[part 2 of 3: package /STELLANTIS/EPT/ASWCs]
AUTOSAR XML (schema 4-2-2)
package /STELLANTIS/EPT/ASWCs  (continued)
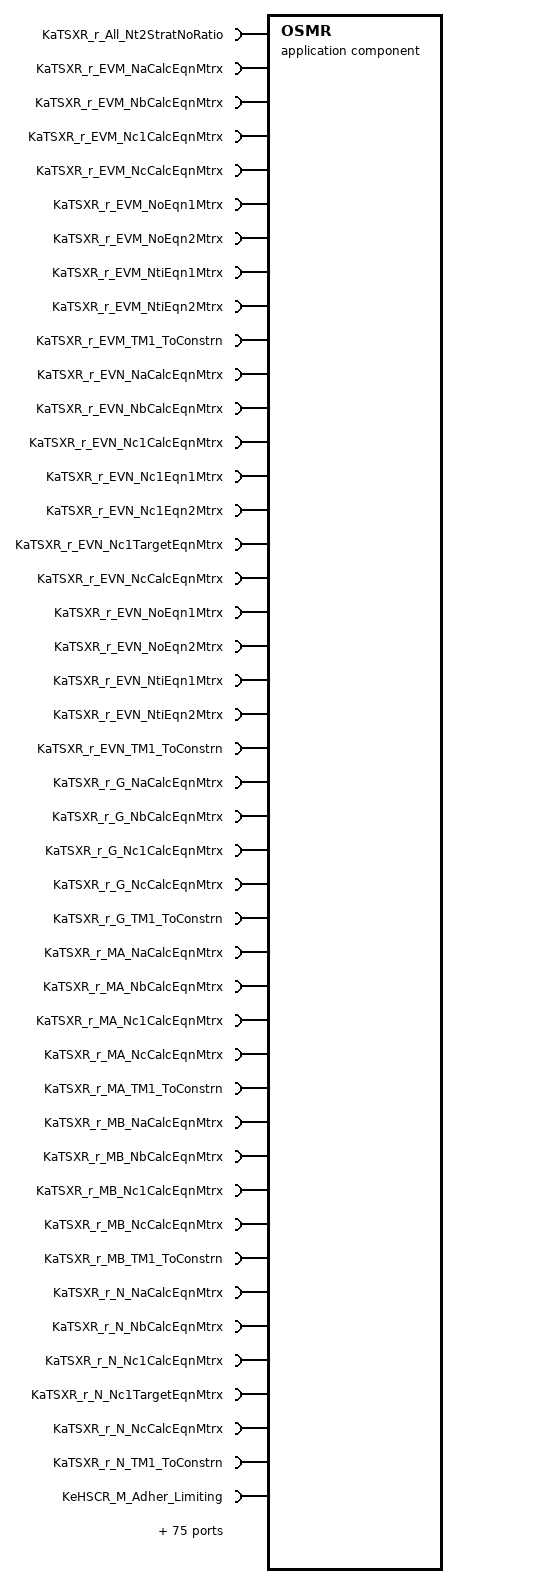
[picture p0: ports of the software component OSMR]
  application sw component type OSMR  (continued)
    119 x require port:
      KaTSXR_r_All_Nt2StratNoRatio: parameter-require-com-spec{init-value=KaTSXR_r_All_Nt2StratNoRatio_KaTSXR_r_All_Nt2StratNoRatio:[KaTSXR_r_All_Nt2StratNoRatio_KaTSXR_r_All_Nt2StratNoRatio_rt_Array_Float_9_1:1, KaTSXR_r_All_Nt2StratNoRatio_KaTSXR_r_All_Nt2StratNoRatio_rt_Array_Float_9_2:1, KaTSXR_r_All_Nt2StratNoRatio_KaTSXR_r_All_Nt2StratNoRatio_rt_Array_Float_9_3:1, KaTSXR_r_All_Nt2StratNoRatio_KaTSXR_r_All_Nt2StratNoRatio_rt_Array_Float_9_4:1, KaTSXR_r_All_Nt2StratNoRatio_KaTSXR_r_All_Nt2StratNoRatio_rt_Array_Float_9_5:1, KaTSXR_r_All_Nt2StratNoRatio_KaTSXR_r_All_Nt2StratNoRatio_rt_Array_Float_9_6:1, KaTSXR_r_All_Nt2StratNoRatio_KaTSXR_r_All_Nt2StratNoRatio_rt_Array_Float_9_7:1, KaTSXR_r_All_Nt2StratNoRatio_KaTSXR_r_All_Nt2StratNoRatio_rt_Array_Float_9_8:1, KaTSXR_r_All_Nt2StratNoRatio_KaTSXR_r_All_Nt2StratNoRatio_rt_Array_Float_9_9:1], parameter=KaTSXR_r_All_Nt2StratNoRatio}, required-interface=KaTSXR_r_All_Nt2StratNoRatio
      KaTSXR_r_EVM_NaCalcEqnMtrx: parameter-require-com-spec{init-value=KaTSXR_r_EVM_NaCalcEqnMtrx_KaTSXR_r_EVM_NaCalcEqnMtrx:[KaTSXR_r_EVM_NaCalcEqnMtrx_KaTSXR_r_EVM_NaCalcEqnMtrx_rt_Array_Float_27_1:0, KaTSXR_r_EVM_NaCalcEqnMtrx_KaTSXR_r_EVM_NaCalcEqnMtrx_rt_Array_Float_27_2:0, KaTSXR_r_EVM_NaCalcEqnMtrx_KaTSXR_r_EVM_NaCalcEqnMtrx_rt_Array_Float_27_3:0, KaTSXR_r_EVM_NaCalcEqnMtrx_KaTSXR_r_EVM_NaCalcEqnMtrx_rt_Array_Float_27_4:0, KaTSXR_r_EVM_NaCalcEqnMtrx_KaTSXR_r_EVM_NaCalcEqnMtrx_rt_Array_Float_27_5:0, KaTSXR_r_EVM_NaCalcEqnMtrx_KaTSXR_r_EVM_NaCalcEqnMtrx_rt_Array_Float_27_6:0, KaTSXR_r_EVM_NaCalcEqnMtrx_KaTSXR_r_EVM_NaCalcEqnMtrx_rt_Array_Float_27_7:0, KaTSXR_r_EVM_NaCalcEqnMtrx_KaTSXR_r_EVM_NaCalcEqnMtrx_rt_Array_Float_27_8:0, KaTSXR_r_EVM_NaCalcEqnMtrx_KaTSXR_r_EVM_NaCalcEqnMtrx_rt_Array_Float_27_9:0, KaTSXR_r_EVM_NaCalcEqnMtrx_KaTSXR_r_EVM_NaCalcEqnMtrx_rt_Array_Float_27_10:0, KaTSXR_r_EVM_NaCalcEqnMtrx_KaTSXR_r_EVM_NaCalcEqnMtrx_rt_Array_Float_27_11:0, KaTSXR_r_EVM_NaCalcEqnMtrx_KaTSXR_r_EVM_NaCalcEqnMtrx_rt_Array_Float_27_12:0, KaTSXR_r_EVM_NaCalcEqnMtrx_KaTSXR_r_EVM_NaCalcEqnMtrx_rt_Array_Float_27_13:0, KaTSXR_r_EVM_NaCalcEqnMtrx_KaTSXR_r_EVM_NaCalcEqnMtrx_rt_Array_Float_27_14:0, KaTSXR_r_EVM_NaCalcEqnMtrx_KaTSXR_r_EVM_NaCalcEqnMtrx_rt_Array_Float_27_15:0, KaTSXR_r_EVM_NaCalcEqnMtrx_KaTSXR_r_EVM_NaCalcEqnMtrx_rt_Array_Float_27_16:0, KaTSXR_r_EVM_NaCalcEqnMtrx_KaTSXR_r_EVM_NaCalcEqnMtrx_rt_Array_Float_27_17:0, KaTSXR_r_EVM_NaCalcEqnMtrx_KaTSXR_r_EVM_NaCalcEqnMtrx_rt_Array_Float_27_18:0, KaTSXR_r_EVM_NaCalcEqnMtrx_KaTSXR_r_EVM_NaCalcEqnMtrx_rt_Array_Float_27_19:0, KaTSXR_r_EVM_NaCalcEqnMtrx_KaTSXR_r_EVM_NaCalcEqnMtrx_rt_Array_Float_27_20:0, KaTSXR_r_EVM_NaCalcEqnMtrx_KaTSXR_r_EVM_NaCalcEqnMtrx_rt_Array_Float_27_21:0, KaTSXR_r_EVM_NaCalcEqnMtrx_KaTSXR_r_EVM_NaCalcEqnMtrx_rt_Array_Float_27_22:0, KaTSXR_r_EVM_NaCalcEqnMtrx_KaTSXR_r_EVM_NaCalcEqnMtrx_rt_Array_Float_27_23:0, KaTSXR_r_EVM_NaCalcEqnMtrx_KaTSXR_r_EVM_NaCalcEqnMtrx_rt_Array_Float_27_24:0, KaTSXR_r_EVM_NaCalcEqnMtrx_KaTSXR_r_EVM_NaCalcEqnMtrx_rt_Array_Float_27_25:0, KaTSXR_r_EVM_NaCalcEqnMtrx_KaTSXR_r_EVM_NaCalcEqnMtrx_rt_Array_Float_27_26:0, KaTSXR_r_EVM_NaCalcEqnMtrx_KaTSXR_r_EVM_NaCalcEqnMtrx_rt_Array_Float_27_27:0], parameter=KaTSXR_r_EVM_NaCalcEqnMtrx}, required-interface=KaTSXR_r_EVM_NaCalcEqnMtrx
      KaTSXR_r_EVM_NbCalcEqnMtrx: parameter-require-com-spec{init-value=KaTSXR_r_EVM_NbCalcEqnMtrx_KaTSXR_r_EVM_NbCalcEqnMtrx:[KaTSXR_r_EVM_NbCalcEqnMtrx_KaTSXR_r_EVM_NbCalcEqnMtrx_rt_Array_Float_27_1:0, KaTSXR_r_EVM_NbCalcEqnMtrx_KaTSXR_r_EVM_NbCalcEqnMtrx_rt_Array_Float_27_2:0, KaTSXR_r_EVM_NbCalcEqnMtrx_KaTSXR_r_EVM_NbCalcEqnMtrx_rt_Array_Float_27_3:0, KaTSXR_r_EVM_NbCalcEqnMtrx_KaTSXR_r_EVM_NbCalcEqnMtrx_rt_Array_Float_27_4:0, KaTSXR_r_EVM_NbCalcEqnMtrx_KaTSXR_r_EVM_NbCalcEqnMtrx_rt_Array_Float_27_5:0, KaTSXR_r_EVM_NbCalcEqnMtrx_KaTSXR_r_EVM_NbCalcEqnMtrx_rt_Array_Float_27_6:0, KaTSXR_r_EVM_NbCalcEqnMtrx_KaTSXR_r_EVM_NbCalcEqnMtrx_rt_Array_Float_27_7:0, KaTSXR_r_EVM_NbCalcEqnMtrx_KaTSXR_r_EVM_NbCalcEqnMtrx_rt_Array_Float_27_8:0, KaTSXR_r_EVM_NbCalcEqnMtrx_KaTSXR_r_EVM_NbCalcEqnMtrx_rt_Array_Float_27_9:0, KaTSXR_r_EVM_NbCalcEqnMtrx_KaTSXR_r_EVM_NbCalcEqnMtrx_rt_Array_Float_27_10:0, KaTSXR_r_EVM_NbCalcEqnMtrx_KaTSXR_r_EVM_NbCalcEqnMtrx_rt_Array_Float_27_11:0, KaTSXR_r_EVM_NbCalcEqnMtrx_KaTSXR_r_EVM_NbCalcEqnMtrx_rt_Array_Float_27_12:0, KaTSXR_r_EVM_NbCalcEqnMtrx_KaTSXR_r_EVM_NbCalcEqnMtrx_rt_Array_Float_27_13:0, KaTSXR_r_EVM_NbCalcEqnMtrx_KaTSXR_r_EVM_NbCalcEqnMtrx_rt_Array_Float_27_14:0, KaTSXR_r_EVM_NbCalcEqnMtrx_KaTSXR_r_EVM_NbCalcEqnMtrx_rt_Array_Float_27_15:0, KaTSXR_r_EVM_NbCalcEqnMtrx_KaTSXR_r_EVM_NbCalcEqnMtrx_rt_Array_Float_27_16:0, KaTSXR_r_EVM_NbCalcEqnMtrx_KaTSXR_r_EVM_NbCalcEqnMtrx_rt_Array_Float_27_17:0, KaTSXR_r_EVM_NbCalcEqnMtrx_KaTSXR_r_EVM_NbCalcEqnMtrx_rt_Array_Float_27_18:0, KaTSXR_r_EVM_NbCalcEqnMtrx_KaTSXR_r_EVM_NbCalcEqnMtrx_rt_Array_Float_27_19:0, KaTSXR_r_EVM_NbCalcEqnMtrx_KaTSXR_r_EVM_NbCalcEqnMtrx_rt_Array_Float_27_20:0, KaTSXR_r_EVM_NbCalcEqnMtrx_KaTSXR_r_EVM_NbCalcEqnMtrx_rt_Array_Float_27_21:0, KaTSXR_r_EVM_NbCalcEqnMtrx_KaTSXR_r_EVM_NbCalcEqnMtrx_rt_Array_Float_27_22:0, KaTSXR_r_EVM_NbCalcEqnMtrx_KaTSXR_r_EVM_NbCalcEqnMtrx_rt_Array_Float_27_23:0, KaTSXR_r_EVM_NbCalcEqnMtrx_KaTSXR_r_EVM_NbCalcEqnMtrx_rt_Array_Float_27_24:0, KaTSXR_r_EVM_NbCalcEqnMtrx_KaTSXR_r_EVM_NbCalcEqnMtrx_rt_Array_Float_27_25:0, KaTSXR_r_EVM_NbCalcEqnMtrx_KaTSXR_r_EVM_NbCalcEqnMtrx_rt_Array_Float_27_26:0, KaTSXR_r_EVM_NbCalcEqnMtrx_KaTSXR_r_EVM_NbCalcEqnMtrx_rt_Array_Float_27_27:0], parameter=KaTSXR_r_EVM_NbCalcEqnMtrx}, required-interface=KaTSXR_r_EVM_NbCalcEqnMtrx
      KaTSXR_r_EVM_Nc1CalcEqnMtrx: parameter-require-com-spec{init-value=KaTSXR_r_EVM_Nc1CalcEqnMtrx_KaTSXR_r_EVM_Nc1CalcEqnMtrx:[KaTSXR_r_EVM_Nc1CalcEqnMtrx_KaTSXR_r_EVM_Nc1CalcEqnMtrx_rt_Array_Float_27_1:0, KaTSXR_r_EVM_Nc1CalcEqnMtrx_KaTSXR_r_EVM_Nc1CalcEqnMtrx_rt_Array_Float_27_2:0, KaTSXR_r_EVM_Nc1CalcEqnMtrx_KaTSXR_r_EVM_Nc1CalcEqnMtrx_rt_Array_Float_27_3:0, KaTSXR_r_EVM_Nc1CalcEqnMtrx_KaTSXR_r_EVM_Nc1CalcEqnMtrx_rt_Array_Float_27_4:0, KaTSXR_r_EVM_Nc1CalcEqnMtrx_KaTSXR_r_EVM_Nc1CalcEqnMtrx_rt_Array_Float_27_5:0, KaTSXR_r_EVM_Nc1CalcEqnMtrx_KaTSXR_r_EVM_Nc1CalcEqnMtrx_rt_Array_Float_27_6:0, KaTSXR_r_EVM_Nc1CalcEqnMtrx_KaTSXR_r_EVM_Nc1CalcEqnMtrx_rt_Array_Float_27_7:0, KaTSXR_r_EVM_Nc1CalcEqnMtrx_KaTSXR_r_EVM_Nc1CalcEqnMtrx_rt_Array_Float_27_8:0, KaTSXR_r_EVM_Nc1CalcEqnMtrx_KaTSXR_r_EVM_Nc1CalcEqnMtrx_rt_Array_Float_27_9:0, KaTSXR_r_EVM_Nc1CalcEqnMtrx_KaTSXR_r_EVM_Nc1CalcEqnMtrx_rt_Array_Float_27_10:0, KaTSXR_r_EVM_Nc1CalcEqnMtrx_KaTSXR_r_EVM_Nc1CalcEqnMtrx_rt_Array_Float_27_11:0, KaTSXR_r_EVM_Nc1CalcEqnMtrx_KaTSXR_r_EVM_Nc1CalcEqnMtrx_rt_Array_Float_27_12:0, KaTSXR_r_EVM_Nc1CalcEqnMtrx_KaTSXR_r_EVM_Nc1CalcEqnMtrx_rt_Array_Float_27_13:0, KaTSXR_r_EVM_Nc1CalcEqnMtrx_KaTSXR_r_EVM_Nc1CalcEqnMtrx_rt_Array_Float_27_14:0, KaTSXR_r_EVM_Nc1CalcEqnMtrx_KaTSXR_r_EVM_Nc1CalcEqnMtrx_rt_Array_Float_27_15:0, KaTSXR_r_EVM_Nc1CalcEqnMtrx_KaTSXR_r_EVM_Nc1CalcEqnMtrx_rt_Array_Float_27_16:0, KaTSXR_r_EVM_Nc1CalcEqnMtrx_KaTSXR_r_EVM_Nc1CalcEqnMtrx_rt_Array_Float_27_17:0, KaTSXR_r_EVM_Nc1CalcEqnMtrx_KaTSXR_r_EVM_Nc1CalcEqnMtrx_rt_Array_Float_27_18:0, KaTSXR_r_EVM_Nc1CalcEqnMtrx_KaTSXR_r_EVM_Nc1CalcEqnMtrx_rt_Array_Float_27_19:0, KaTSXR_r_EVM_Nc1CalcEqnMtrx_KaTSXR_r_EVM_Nc1CalcEqnMtrx_rt_Array_Float_27_20:0, KaTSXR_r_EVM_Nc1CalcEqnMtrx_KaTSXR_r_EVM_Nc1CalcEqnMtrx_rt_Array_Float_27_21:0, KaTSXR_r_EVM_Nc1CalcEqnMtrx_KaTSXR_r_EVM_Nc1CalcEqnMtrx_rt_Array_Float_27_22:0, KaTSXR_r_EVM_Nc1CalcEqnMtrx_KaTSXR_r_EVM_Nc1CalcEqnMtrx_rt_Array_Float_27_23:0, KaTSXR_r_EVM_Nc1CalcEqnMtrx_KaTSXR_r_EVM_Nc1CalcEqnMtrx_rt_Array_Float_27_24:0, KaTSXR_r_EVM_Nc1CalcEqnMtrx_KaTSXR_r_EVM_Nc1CalcEqnMtrx_rt_Array_Float_27_25:0, KaTSXR_r_EVM_Nc1CalcEqnMtrx_KaTSXR_r_EVM_Nc1CalcEqnMtrx_rt_Array_Float_27_26:0, KaTSXR_r_EVM_Nc1CalcEqnMtrx_KaTSXR_r_EVM_Nc1CalcEqnMtrx_rt_Array_Float_27_27:0], parameter=KaTSXR_r_EVM_Nc1CalcEqnMtrx}, required-interface=KaTSXR_r_EVM_Nc1CalcEqnMtrx
      KaTSXR_r_EVM_NcCalcEqnMtrx: parameter-require-com-spec{init-value=KaTSXR_r_EVM_NcCalcEqnMtrx_KaTSXR_r_EVM_NcCalcEqnMtrx:[KaTSXR_r_EVM_NcCalcEqnMtrx_KaTSXR_r_EVM_NcCalcEqnMtrx_rt_Array_Float_27_1:0, KaTSXR_r_EVM_NcCalcEqnMtrx_KaTSXR_r_EVM_NcCalcEqnMtrx_rt_Array_Float_27_2:0, KaTSXR_r_EVM_NcCalcEqnMtrx_KaTSXR_r_EVM_NcCalcEqnMtrx_rt_Array_Float_27_3:0, KaTSXR_r_EVM_NcCalcEqnMtrx_KaTSXR_r_EVM_NcCalcEqnMtrx_rt_Array_Float_27_4:0, KaTSXR_r_EVM_NcCalcEqnMtrx_KaTSXR_r_EVM_NcCalcEqnMtrx_rt_Array_Float_27_5:0, KaTSXR_r_EVM_NcCalcEqnMtrx_KaTSXR_r_EVM_NcCalcEqnMtrx_rt_Array_Float_27_6:0, KaTSXR_r_EVM_NcCalcEqnMtrx_KaTSXR_r_EVM_NcCalcEqnMtrx_rt_Array_Float_27_7:0, KaTSXR_r_EVM_NcCalcEqnMtrx_KaTSXR_r_EVM_NcCalcEqnMtrx_rt_Array_Float_27_8:0, KaTSXR_r_EVM_NcCalcEqnMtrx_KaTSXR_r_EVM_NcCalcEqnMtrx_rt_Array_Float_27_9:0, KaTSXR_r_EVM_NcCalcEqnMtrx_KaTSXR_r_EVM_NcCalcEqnMtrx_rt_Array_Float_27_10:0, KaTSXR_r_EVM_NcCalcEqnMtrx_KaTSXR_r_EVM_NcCalcEqnMtrx_rt_Array_Float_27_11:0, KaTSXR_r_EVM_NcCalcEqnMtrx_KaTSXR_r_EVM_NcCalcEqnMtrx_rt_Array_Float_27_12:0, KaTSXR_r_EVM_NcCalcEqnMtrx_KaTSXR_r_EVM_NcCalcEqnMtrx_rt_Array_Float_27_13:0, KaTSXR_r_EVM_NcCalcEqnMtrx_KaTSXR_r_EVM_NcCalcEqnMtrx_rt_Array_Float_27_14:0, KaTSXR_r_EVM_NcCalcEqnMtrx_KaTSXR_r_EVM_NcCalcEqnMtrx_rt_Array_Float_27_15:0, KaTSXR_r_EVM_NcCalcEqnMtrx_KaTSXR_r_EVM_NcCalcEqnMtrx_rt_Array_Float_27_16:0, KaTSXR_r_EVM_NcCalcEqnMtrx_KaTSXR_r_EVM_NcCalcEqnMtrx_rt_Array_Float_27_17:0, KaTSXR_r_EVM_NcCalcEqnMtrx_KaTSXR_r_EVM_NcCalcEqnMtrx_rt_Array_Float_27_18:0, KaTSXR_r_EVM_NcCalcEqnMtrx_KaTSXR_r_EVM_NcCalcEqnMtrx_rt_Array_Float_27_19:0, KaTSXR_r_EVM_NcCalcEqnMtrx_KaTSXR_r_EVM_NcCalcEqnMtrx_rt_Array_Float_27_20:0, KaTSXR_r_EVM_NcCalcEqnMtrx_KaTSXR_r_EVM_NcCalcEqnMtrx_rt_Array_Float_27_21:0, KaTSXR_r_EVM_NcCalcEqnMtrx_KaTSXR_r_EVM_NcCalcEqnMtrx_rt_Array_Float_27_22:0, KaTSXR_r_EVM_NcCalcEqnMtrx_KaTSXR_r_EVM_NcCalcEqnMtrx_rt_Array_Float_27_23:0, KaTSXR_r_EVM_NcCalcEqnMtrx_KaTSXR_r_EVM_NcCalcEqnMtrx_rt_Array_Float_27_24:0, KaTSXR_r_EVM_NcCalcEqnMtrx_KaTSXR_r_EVM_NcCalcEqnMtrx_rt_Array_Float_27_25:0, KaTSXR_r_EVM_NcCalcEqnMtrx_KaTSXR_r_EVM_NcCalcEqnMtrx_rt_Array_Float_27_26:0, KaTSXR_r_EVM_NcCalcEqnMtrx_KaTSXR_r_EVM_NcCalcEqnMtrx_rt_Array_Float_27_27:0], parameter=KaTSXR_r_EVM_NcCalcEqnMtrx}, required-interface=KaTSXR_r_EVM_NcCalcEqnMtrx
      KaTSXR_r_EVM_NoEqn1Mtrx: parameter-require-com-spec{init-value=KaTSXR_r_EVM_NoEqn1Mtrx_KaTSXR_r_EVM_NoEqn1Mtrx:[KaTSXR_r_EVM_NoEqn1Mtrx_KaTSXR_r_EVM_NoEqn1Mtrx_rt_Array_Float_54_1:0, KaTSXR_r_EVM_NoEqn1Mtrx_KaTSXR_r_EVM_NoEqn1Mtrx_rt_Array_Float_54_2:0, KaTSXR_r_EVM_NoEqn1Mtrx_KaTSXR_r_EVM_NoEqn1Mtrx_rt_Array_Float_54_3:0, KaTSXR_r_EVM_NoEqn1Mtrx_KaTSXR_r_EVM_NoEqn1Mtrx_rt_Array_Float_54_4:0, KaTSXR_r_EVM_NoEqn1Mtrx_KaTSXR_r_EVM_NoEqn1Mtrx_rt_Array_Float_54_5:0, KaTSXR_r_EVM_NoEqn1Mtrx_KaTSXR_r_EVM_NoEqn1Mtrx_rt_Array_Float_54_6:0, KaTSXR_r_EVM_NoEqn1Mtrx_KaTSXR_r_EVM_NoEqn1Mtrx_rt_Array_Float_54_7:0, KaTSXR_r_EVM_NoEqn1Mtrx_KaTSXR_r_EVM_NoEqn1Mtrx_rt_Array_Float_54_8:0, KaTSXR_r_EVM_NoEqn1Mtrx_KaTSXR_r_EVM_NoEqn1Mtrx_rt_Array_Float_54_9:0, KaTSXR_r_EVM_NoEqn1Mtrx_KaTSXR_r_EVM_NoEqn1Mtrx_rt_Array_Float_54_10:0, KaTSXR_r_EVM_NoEqn1Mtrx_KaTSXR_r_EVM_NoEqn1Mtrx_rt_Array_Float_54_11:0, KaTSXR_r_EVM_NoEqn1Mtrx_KaTSXR_r_EVM_NoEqn1Mtrx_rt_Array_Float_54_12:0, KaTSXR_r_EVM_NoEqn1Mtrx_KaTSXR_r_EVM_NoEqn1Mtrx_rt_Array_Float_54_13:0, KaTSXR_r_EVM_NoEqn1Mtrx_KaTSXR_r_EVM_NoEqn1Mtrx_rt_Array_Float_54_14:0, KaTSXR_r_EVM_NoEqn1Mtrx_KaTSXR_r_EVM_NoEqn1Mtrx_rt_Array_Float_54_15:0, KaTSXR_r_EVM_NoEqn1Mtrx_KaTSXR_r_EVM_NoEqn1Mtrx_rt_Array_Float_54_16:0, KaTSXR_r_EVM_NoEqn1Mtrx_KaTSXR_r_EVM_NoEqn1Mtrx_rt_Array_Float_54_17:0, KaTSXR_r_EVM_NoEqn1Mtrx_KaTSXR_r_EVM_NoEqn1Mtrx_rt_Array_Float_54_18:0, KaTSXR_r_EVM_NoEqn1Mtrx_KaTSXR_r_EVM_NoEqn1Mtrx_rt_Array_Float_54_19:0, KaTSXR_r_EVM_NoEqn1Mtrx_KaTSXR_r_EVM_NoEqn1Mtrx_rt_Array_Float_54_20:0, KaTSXR_r_EVM_NoEqn1Mtrx_KaTSXR_r_EVM_NoEqn1Mtrx_rt_Array_Float_54_21:0, KaTSXR_r_EVM_NoEqn1Mtrx_KaTSXR_r_EVM_NoEqn1Mtrx_rt_Array_Float_54_22:0, KaTSXR_r_EVM_NoEqn1Mtrx_KaTSXR_r_EVM_NoEqn1Mtrx_rt_Array_Float_54_23:0, KaTSXR_r_EVM_NoEqn1Mtrx_KaTSXR_r_EVM_NoEqn1Mtrx_rt_Array_Float_54_24:0, KaTSXR_r_EVM_NoEqn1Mtrx_KaTSXR_r_EVM_NoEqn1Mtrx_rt_Array_Float_54_25:0, KaTSXR_r_EVM_NoEqn1Mtrx_KaTSXR_r_EVM_NoEqn1Mtrx_rt_Array_Float_54_26:0, KaTSXR_r_EVM_NoEqn1Mtrx_KaTSXR_r_EVM_NoEqn1Mtrx_rt_Array_Float_54_27:0, KaTSXR_r_EVM_NoEqn1Mtrx_KaTSXR_r_EVM_NoEqn1Mtrx_rt_Array_Float_54_28:0, KaTSXR_r_EVM_NoEqn1Mtrx_KaTSXR_r_EVM_NoEqn1Mtrx_rt_Array_Float_54_29:0, KaTSXR_r_EVM_NoEqn1Mtrx_KaTSXR_r_EVM_NoEqn1Mtrx_rt_Array_Float_54_30:0, KaTSXR_r_EVM_NoEqn1Mtrx_KaTSXR_r_EVM_NoEqn1Mtrx_rt_Array_Float_54_31:0, KaTSXR_r_EVM_NoEqn1Mtrx_KaTSXR_r_EVM_NoEqn1Mtrx_rt_Array_Float_54_32:0, KaTSXR_r_EVM_NoEqn1Mtrx_KaTSXR_r_EVM_NoEqn1Mtrx_rt_Array_Float_54_33:0, KaTSXR_r_EVM_NoEqn1Mtrx_KaTSXR_r_EVM_NoEqn1Mtrx_rt_Array_Float_54_34:0, KaTSXR_r_EVM_NoEqn1Mtrx_KaTSXR_r_EVM_NoEqn1Mtrx_rt_Array_Float_54_35:0, KaTSXR_r_EVM_NoEqn1Mtrx_KaTSXR_r_EVM_NoEqn1Mtrx_rt_Array_Float_54_36:0, KaTSXR_r_EVM_NoEqn1Mtrx_KaTSXR_r_EVM_NoEqn1Mtrx_rt_Array_Float_54_37:0, KaTSXR_r_EVM_NoEqn1Mtrx_KaTSXR_r_EVM_NoEqn1Mtrx_rt_Array_Float_54_38:0, KaTSXR_r_EVM_NoEqn1Mtrx_KaTSXR_r_EVM_NoEqn1Mtrx_rt_Array_Float_54_39:0, KaTSXR_r_EVM_NoEqn1Mtrx_KaTSXR_r_EVM_NoEqn1Mtrx_rt_Array_Float_54_40:0, KaTSXR_r_EVM_NoEqn1Mtrx_KaTSXR_r_EVM_NoEqn1Mtrx_rt_Array_Float_54_41:0, KaTSXR_r_EVM_NoEqn1Mtrx_KaTSXR_r_EVM_NoEqn1Mtrx_rt_Array_Float_54_42:0, KaTSXR_r_EVM_NoEqn1Mtrx_KaTSXR_r_EVM_NoEqn1Mtrx_rt_Array_Float_54_43:0, KaTSXR_r_EVM_NoEqn1Mtrx_KaTSXR_r_EVM_NoEqn1Mtrx_rt_Array_Float_54_44:0, KaTSXR_r_EVM_NoEqn1Mtrx_KaTSXR_r_EVM_NoEqn1Mtrx_rt_Array_Float_54_45:0, KaTSXR_r_EVM_NoEqn1Mtrx_KaTSXR_r_EVM_NoEqn1Mtrx_rt_Array_Float_54_46:0, KaTSXR_r_EVM_NoEqn1Mtrx_KaTSXR_r_EVM_NoEqn1Mtrx_rt_Array_Float_54_47:0, KaTSXR_r_EVM_NoEqn1Mtrx_KaTSXR_r_EVM_NoEqn1Mtrx_rt_Array_Float_54_48:0, KaTSXR_r_EVM_NoEqn1Mtrx_KaTSXR_r_EVM_NoEqn1Mtrx_rt_Array_Float_54_49:0, KaTSXR_r_EVM_NoEqn1Mtrx_KaTSXR_r_EVM_NoEqn1Mtrx_rt_Array_Float_54_50:0, KaTSXR_r_EVM_NoEqn1Mtrx_KaTSXR_r_EVM_NoEqn1Mtrx_rt_Array_Float_54_51:0, KaTSXR_r_EVM_NoEqn1Mtrx_KaTSXR_r_EVM_NoEqn1Mtrx_rt_Array_Float_54_52:0, KaTSXR_r_EVM_NoEqn1Mtrx_KaTSXR_r_EVM_NoEqn1Mtrx_rt_Array_Float_54_53:0, KaTSXR_r_EVM_NoEqn1Mtrx_KaTSXR_r_EVM_NoEqn1Mtrx_rt_Array_Float_54_54:0], parameter=KaTSXR_r_EVM_NoEqn1Mtrx}, required-interface=KaTSXR_r_EVM_NoEqn1Mtrx
      KaTSXR_r_EVM_NoEqn2Mtrx: parameter-require-com-spec{init-value=KaTSXR_r_EVM_NoEqn2Mtrx_KaTSXR_r_EVM_NoEqn2Mtrx:[KaTSXR_r_EVM_NoEqn2Mtrx_KaTSXR_r_EVM_NoEqn2Mtrx_rt_Array_Float_54_1:0, KaTSXR_r_EVM_NoEqn2Mtrx_KaTSXR_r_EVM_NoEqn2Mtrx_rt_Array_Float_54_2:0, KaTSXR_r_EVM_NoEqn2Mtrx_KaTSXR_r_EVM_NoEqn2Mtrx_rt_Array_Float_54_3:0, KaTSXR_r_EVM_NoEqn2Mtrx_KaTSXR_r_EVM_NoEqn2Mtrx_rt_Array_Float_54_4:0, KaTSXR_r_EVM_NoEqn2Mtrx_KaTSXR_r_EVM_NoEqn2Mtrx_rt_Array_Float_54_5:0, KaTSXR_r_EVM_NoEqn2Mtrx_KaTSXR_r_EVM_NoEqn2Mtrx_rt_Array_Float_54_6:0, KaTSXR_r_EVM_NoEqn2Mtrx_KaTSXR_r_EVM_NoEqn2Mtrx_rt_Array_Float_54_7:0, KaTSXR_r_EVM_NoEqn2Mtrx_KaTSXR_r_EVM_NoEqn2Mtrx_rt_Array_Float_54_8:0, KaTSXR_r_EVM_NoEqn2Mtrx_KaTSXR_r_EVM_NoEqn2Mtrx_rt_Array_Float_54_9:0, KaTSXR_r_EVM_NoEqn2Mtrx_KaTSXR_r_EVM_NoEqn2Mtrx_rt_Array_Float_54_10:0, KaTSXR_r_EVM_NoEqn2Mtrx_KaTSXR_r_EVM_NoEqn2Mtrx_rt_Array_Float_54_11:0, KaTSXR_r_EVM_NoEqn2Mtrx_KaTSXR_r_EVM_NoEqn2Mtrx_rt_Array_Float_54_12:0, KaTSXR_r_EVM_NoEqn2Mtrx_KaTSXR_r_EVM_NoEqn2Mtrx_rt_Array_Float_54_13:0, KaTSXR_r_EVM_NoEqn2Mtrx_KaTSXR_r_EVM_NoEqn2Mtrx_rt_Array_Float_54_14:0, KaTSXR_r_EVM_NoEqn2Mtrx_KaTSXR_r_EVM_NoEqn2Mtrx_rt_Array_Float_54_15:0, KaTSXR_r_EVM_NoEqn2Mtrx_KaTSXR_r_EVM_NoEqn2Mtrx_rt_Array_Float_54_16:0, KaTSXR_r_EVM_NoEqn2Mtrx_KaTSXR_r_EVM_NoEqn2Mtrx_rt_Array_Float_54_17:0, KaTSXR_r_EVM_NoEqn2Mtrx_KaTSXR_r_EVM_NoEqn2Mtrx_rt_Array_Float_54_18:0, KaTSXR_r_EVM_NoEqn2Mtrx_KaTSXR_r_EVM_NoEqn2Mtrx_rt_Array_Float_54_19:0, KaTSXR_r_EVM_NoEqn2Mtrx_KaTSXR_r_EVM_NoEqn2Mtrx_rt_Array_Float_54_20:0, KaTSXR_r_EVM_NoEqn2Mtrx_KaTSXR_r_EVM_NoEqn2Mtrx_rt_Array_Float_54_21:0, KaTSXR_r_EVM_NoEqn2Mtrx_KaTSXR_r_EVM_NoEqn2Mtrx_rt_Array_Float_54_22:0, KaTSXR_r_EVM_NoEqn2Mtrx_KaTSXR_r_EVM_NoEqn2Mtrx_rt_Array_Float_54_23:0, KaTSXR_r_EVM_NoEqn2Mtrx_KaTSXR_r_EVM_NoEqn2Mtrx_rt_Array_Float_54_24:0, KaTSXR_r_EVM_NoEqn2Mtrx_KaTSXR_r_EVM_NoEqn2Mtrx_rt_Array_Float_54_25:0, KaTSXR_r_EVM_NoEqn2Mtrx_KaTSXR_r_EVM_NoEqn2Mtrx_rt_Array_Float_54_26:0, KaTSXR_r_EVM_NoEqn2Mtrx_KaTSXR_r_EVM_NoEqn2Mtrx_rt_Array_Float_54_27:0, KaTSXR_r_EVM_NoEqn2Mtrx_KaTSXR_r_EVM_NoEqn2Mtrx_rt_Array_Float_54_28:0, KaTSXR_r_EVM_NoEqn2Mtrx_KaTSXR_r_EVM_NoEqn2Mtrx_rt_Array_Float_54_29:0, KaTSXR_r_EVM_NoEqn2Mtrx_KaTSXR_r_EVM_NoEqn2Mtrx_rt_Array_Float_54_30:0, KaTSXR_r_EVM_NoEqn2Mtrx_KaTSXR_r_EVM_NoEqn2Mtrx_rt_Array_Float_54_31:0, KaTSXR_r_EVM_NoEqn2Mtrx_KaTSXR_r_EVM_NoEqn2Mtrx_rt_Array_Float_54_32:0, KaTSXR_r_EVM_NoEqn2Mtrx_KaTSXR_r_EVM_NoEqn2Mtrx_rt_Array_Float_54_33:0, KaTSXR_r_EVM_NoEqn2Mtrx_KaTSXR_r_EVM_NoEqn2Mtrx_rt_Array_Float_54_34:0, KaTSXR_r_EVM_NoEqn2Mtrx_KaTSXR_r_EVM_NoEqn2Mtrx_rt_Array_Float_54_35:0, KaTSXR_r_EVM_NoEqn2Mtrx_KaTSXR_r_EVM_NoEqn2Mtrx_rt_Array_Float_54_36:0, KaTSXR_r_EVM_NoEqn2Mtrx_KaTSXR_r_EVM_NoEqn2Mtrx_rt_Array_Float_54_37:0, KaTSXR_r_EVM_NoEqn2Mtrx_KaTSXR_r_EVM_NoEqn2Mtrx_rt_Array_Float_54_38:0, KaTSXR_r_EVM_NoEqn2Mtrx_KaTSXR_r_EVM_NoEqn2Mtrx_rt_Array_Float_54_39:0, KaTSXR_r_EVM_NoEqn2Mtrx_KaTSXR_r_EVM_NoEqn2Mtrx_rt_Array_Float_54_40:0, KaTSXR_r_EVM_NoEqn2Mtrx_KaTSXR_r_EVM_NoEqn2Mtrx_rt_Array_Float_54_41:0, KaTSXR_r_EVM_NoEqn2Mtrx_KaTSXR_r_EVM_NoEqn2Mtrx_rt_Array_Float_54_42:0, KaTSXR_r_EVM_NoEqn2Mtrx_KaTSXR_r_EVM_NoEqn2Mtrx_rt_Array_Float_54_43:0, KaTSXR_r_EVM_NoEqn2Mtrx_KaTSXR_r_EVM_NoEqn2Mtrx_rt_Array_Float_54_44:0, KaTSXR_r_EVM_NoEqn2Mtrx_KaTSXR_r_EVM_NoEqn2Mtrx_rt_Array_Float_54_45:0, KaTSXR_r_EVM_NoEqn2Mtrx_KaTSXR_r_EVM_NoEqn2Mtrx_rt_Array_Float_54_46:0, KaTSXR_r_EVM_NoEqn2Mtrx_KaTSXR_r_EVM_NoEqn2Mtrx_rt_Array_Float_54_47:0, KaTSXR_r_EVM_NoEqn2Mtrx_KaTSXR_r_EVM_NoEqn2Mtrx_rt_Array_Float_54_48:0, KaTSXR_r_EVM_NoEqn2Mtrx_KaTSXR_r_EVM_NoEqn2Mtrx_rt_Array_Float_54_49:0, KaTSXR_r_EVM_NoEqn2Mtrx_KaTSXR_r_EVM_NoEqn2Mtrx_rt_Array_Float_54_50:0, KaTSXR_r_EVM_NoEqn2Mtrx_KaTSXR_r_EVM_NoEqn2Mtrx_rt_Array_Float_54_51:0, KaTSXR_r_EVM_NoEqn2Mtrx_KaTSXR_r_EVM_NoEqn2Mtrx_rt_Array_Float_54_52:0, KaTSXR_r_EVM_NoEqn2Mtrx_KaTSXR_r_EVM_NoEqn2Mtrx_rt_Array_Float_54_53:0, KaTSXR_r_EVM_NoEqn2Mtrx_KaTSXR_r_EVM_NoEqn2Mtrx_rt_Array_Float_54_54:0], parameter=KaTSXR_r_EVM_NoEqn2Mtrx}, required-interface=KaTSXR_r_EVM_NoEqn2Mtrx
      KaTSXR_r_EVM_NtiEqn1Mtrx: parameter-require-com-spec{init-value=KaTSXR_r_EVM_NtiEqn1Mtrx_KaTSXR_r_EVM_NtiEqn1Mtrx:[KaTSXR_r_EVM_NtiEqn1Mtrx_KaTSXR_r_EVM_NtiEqn1Mtrx_rt_Array_Float_54_1:0, KaTSXR_r_EVM_NtiEqn1Mtrx_KaTSXR_r_EVM_NtiEqn1Mtrx_rt_Array_Float_54_2:0, KaTSXR_r_EVM_NtiEqn1Mtrx_KaTSXR_r_EVM_NtiEqn1Mtrx_rt_Array_Float_54_3:0, KaTSXR_r_EVM_NtiEqn1Mtrx_KaTSXR_r_EVM_NtiEqn1Mtrx_rt_Array_Float_54_4:0, KaTSXR_r_EVM_NtiEqn1Mtrx_KaTSXR_r_EVM_NtiEqn1Mtrx_rt_Array_Float_54_5:0, KaTSXR_r_EVM_NtiEqn1Mtrx_KaTSXR_r_EVM_NtiEqn1Mtrx_rt_Array_Float_54_6:0, KaTSXR_r_EVM_NtiEqn1Mtrx_KaTSXR_r_EVM_NtiEqn1Mtrx_rt_Array_Float_54_7:0, KaTSXR_r_EVM_NtiEqn1Mtrx_KaTSXR_r_EVM_NtiEqn1Mtrx_rt_Array_Float_54_8:0, KaTSXR_r_EVM_NtiEqn1Mtrx_KaTSXR_r_EVM_NtiEqn1Mtrx_rt_Array_Float_54_9:0, KaTSXR_r_EVM_NtiEqn1Mtrx_KaTSXR_r_EVM_NtiEqn1Mtrx_rt_Array_Float_54_10:0, KaTSXR_r_EVM_NtiEqn1Mtrx_KaTSXR_r_EVM_NtiEqn1Mtrx_rt_Array_Float_54_11:0, KaTSXR_r_EVM_NtiEqn1Mtrx_KaTSXR_r_EVM_NtiEqn1Mtrx_rt_Array_Float_54_12:0, KaTSXR_r_EVM_NtiEqn1Mtrx_KaTSXR_r_EVM_NtiEqn1Mtrx_rt_Array_Float_54_13:0, KaTSXR_r_EVM_NtiEqn1Mtrx_KaTSXR_r_EVM_NtiEqn1Mtrx_rt_Array_Float_54_14:0, KaTSXR_r_EVM_NtiEqn1Mtrx_KaTSXR_r_EVM_NtiEqn1Mtrx_rt_Array_Float_54_15:0, KaTSXR_r_EVM_NtiEqn1Mtrx_KaTSXR_r_EVM_NtiEqn1Mtrx_rt_Array_Float_54_16:0, KaTSXR_r_EVM_NtiEqn1Mtrx_KaTSXR_r_EVM_NtiEqn1Mtrx_rt_Array_Float_54_17:0, KaTSXR_r_EVM_NtiEqn1Mtrx_KaTSXR_r_EVM_NtiEqn1Mtrx_rt_Array_Float_54_18:0, KaTSXR_r_EVM_NtiEqn1Mtrx_KaTSXR_r_EVM_NtiEqn1Mtrx_rt_Array_Float_54_19:0, KaTSXR_r_EVM_NtiEqn1Mtrx_KaTSXR_r_EVM_NtiEqn1Mtrx_rt_Array_Float_54_20:0, KaTSXR_r_EVM_NtiEqn1Mtrx_KaTSXR_r_EVM_NtiEqn1Mtrx_rt_Array_Float_54_21:0, KaTSXR_r_EVM_NtiEqn1Mtrx_KaTSXR_r_EVM_NtiEqn1Mtrx_rt_Array_Float_54_22:0, KaTSXR_r_EVM_NtiEqn1Mtrx_KaTSXR_r_EVM_NtiEqn1Mtrx_rt_Array_Float_54_23:0, KaTSXR_r_EVM_NtiEqn1Mtrx_KaTSXR_r_EVM_NtiEqn1Mtrx_rt_Array_Float_54_24:0, KaTSXR_r_EVM_NtiEqn1Mtrx_KaTSXR_r_EVM_NtiEqn1Mtrx_rt_Array_Float_54_25:0, KaTSXR_r_EVM_NtiEqn1Mtrx_KaTSXR_r_EVM_NtiEqn1Mtrx_rt_Array_Float_54_26:0, KaTSXR_r_EVM_NtiEqn1Mtrx_KaTSXR_r_EVM_NtiEqn1Mtrx_rt_Array_Float_54_27:0, KaTSXR_r_EVM_NtiEqn1Mtrx_KaTSXR_r_EVM_NtiEqn1Mtrx_rt_Array_Float_54_28:0, KaTSXR_r_EVM_NtiEqn1Mtrx_KaTSXR_r_EVM_NtiEqn1Mtrx_rt_Array_Float_54_29:0, KaTSXR_r_EVM_NtiEqn1Mtrx_KaTSXR_r_EVM_NtiEqn1Mtrx_rt_Array_Float_54_30:0, KaTSXR_r_EVM_NtiEqn1Mtrx_KaTSXR_r_EVM_NtiEqn1Mtrx_rt_Array_Float_54_31:0, KaTSXR_r_EVM_NtiEqn1Mtrx_KaTSXR_r_EVM_NtiEqn1Mtrx_rt_Array_Float_54_32:0, KaTSXR_r_EVM_NtiEqn1Mtrx_KaTSXR_r_EVM_NtiEqn1Mtrx_rt_Array_Float_54_33:0, KaTSXR_r_EVM_NtiEqn1Mtrx_KaTSXR_r_EVM_NtiEqn1Mtrx_rt_Array_Float_54_34:0, KaTSXR_r_EVM_NtiEqn1Mtrx_KaTSXR_r_EVM_NtiEqn1Mtrx_rt_Array_Float_54_35:0, KaTSXR_r_EVM_NtiEqn1Mtrx_KaTSXR_r_EVM_NtiEqn1Mtrx_rt_Array_Float_54_36:0, KaTSXR_r_EVM_NtiEqn1Mtrx_KaTSXR_r_EVM_NtiEqn1Mtrx_rt_Array_Float_54_37:0, KaTSXR_r_EVM_NtiEqn1Mtrx_KaTSXR_r_EVM_NtiEqn1Mtrx_rt_Array_Float_54_38:0, KaTSXR_r_EVM_NtiEqn1Mtrx_KaTSXR_r_EVM_NtiEqn1Mtrx_rt_Array_Float_54_39:0, KaTSXR_r_EVM_NtiEqn1Mtrx_KaTSXR_r_EVM_NtiEqn1Mtrx_rt_Array_Float_54_40:0, KaTSXR_r_EVM_NtiEqn1Mtrx_KaTSXR_r_EVM_NtiEqn1Mtrx_rt_Array_Float_54_41:0, KaTSXR_r_EVM_NtiEqn1Mtrx_KaTSXR_r_EVM_NtiEqn1Mtrx_rt_Array_Float_54_42:0, KaTSXR_r_EVM_NtiEqn1Mtrx_KaTSXR_r_EVM_NtiEqn1Mtrx_rt_Array_Float_54_43:0, KaTSXR_r_EVM_NtiEqn1Mtrx_KaTSXR_r_EVM_NtiEqn1Mtrx_rt_Array_Float_54_44:0, KaTSXR_r_EVM_NtiEqn1Mtrx_KaTSXR_r_EVM_NtiEqn1Mtrx_rt_Array_Float_54_45:0, KaTSXR_r_EVM_NtiEqn1Mtrx_KaTSXR_r_EVM_NtiEqn1Mtrx_rt_Array_Float_54_46:0, KaTSXR_r_EVM_NtiEqn1Mtrx_KaTSXR_r_EVM_NtiEqn1Mtrx_rt_Array_Float_54_47:0, KaTSXR_r_EVM_NtiEqn1Mtrx_KaTSXR_r_EVM_NtiEqn1Mtrx_rt_Array_Float_54_48:0, KaTSXR_r_EVM_NtiEqn1Mtrx_KaTSXR_r_EVM_NtiEqn1Mtrx_rt_Array_Float_54_49:0, KaTSXR_r_EVM_NtiEqn1Mtrx_KaTSXR_r_EVM_NtiEqn1Mtrx_rt_Array_Float_54_50:0, KaTSXR_r_EVM_NtiEqn1Mtrx_KaTSXR_r_EVM_NtiEqn1Mtrx_rt_Array_Float_54_51:0, KaTSXR_r_EVM_NtiEqn1Mtrx_KaTSXR_r_EVM_NtiEqn1Mtrx_rt_Array_Float_54_52:0, KaTSXR_r_EVM_NtiEqn1Mtrx_KaTSXR_r_EVM_NtiEqn1Mtrx_rt_Array_Float_54_53:0, KaTSXR_r_EVM_NtiEqn1Mtrx_KaTSXR_r_EVM_NtiEqn1Mtrx_rt_Array_Float_54_54:0], parameter=KaTSXR_r_EVM_NtiEqn1Mtrx}, required-interface=KaTSXR_r_EVM_NtiEqn1Mtrx
      KaTSXR_r_EVM_NtiEqn2Mtrx: parameter-require-com-spec{init-value=KaTSXR_r_EVM_NtiEqn2Mtrx_KaTSXR_r_EVM_NtiEqn2Mtrx:[KaTSXR_r_EVM_NtiEqn2Mtrx_KaTSXR_r_EVM_NtiEqn2Mtrx_rt_Array_Float_54_1:0, KaTSXR_r_EVM_NtiEqn2Mtrx_KaTSXR_r_EVM_NtiEqn2Mtrx_rt_Array_Float_54_2:0, KaTSXR_r_EVM_NtiEqn2Mtrx_KaTSXR_r_EVM_NtiEqn2Mtrx_rt_Array_Float_54_3:0, KaTSXR_r_EVM_NtiEqn2Mtrx_KaTSXR_r_EVM_NtiEqn2Mtrx_rt_Array_Float_54_4:0, KaTSXR_r_EVM_NtiEqn2Mtrx_KaTSXR_r_EVM_NtiEqn2Mtrx_rt_Array_Float_54_5:0, KaTSXR_r_EVM_NtiEqn2Mtrx_KaTSXR_r_EVM_NtiEqn2Mtrx_rt_Array_Float_54_6:0, KaTSXR_r_EVM_NtiEqn2Mtrx_KaTSXR_r_EVM_NtiEqn2Mtrx_rt_Array_Float_54_7:0, KaTSXR_r_EVM_NtiEqn2Mtrx_KaTSXR_r_EVM_NtiEqn2Mtrx_rt_Array_Float_54_8:0, KaTSXR_r_EVM_NtiEqn2Mtrx_KaTSXR_r_EVM_NtiEqn2Mtrx_rt_Array_Float_54_9:0, KaTSXR_r_EVM_NtiEqn2Mtrx_KaTSXR_r_EVM_NtiEqn2Mtrx_rt_Array_Float_54_10:0, KaTSXR_r_EVM_NtiEqn2Mtrx_KaTSXR_r_EVM_NtiEqn2Mtrx_rt_Array_Float_54_11:0, KaTSXR_r_EVM_NtiEqn2Mtrx_KaTSXR_r_EVM_NtiEqn2Mtrx_rt_Array_Float_54_12:0, KaTSXR_r_EVM_NtiEqn2Mtrx_KaTSXR_r_EVM_NtiEqn2Mtrx_rt_Array_Float_54_13:0, KaTSXR_r_EVM_NtiEqn2Mtrx_KaTSXR_r_EVM_NtiEqn2Mtrx_rt_Array_Float_54_14:0, KaTSXR_r_EVM_NtiEqn2Mtrx_KaTSXR_r_EVM_NtiEqn2Mtrx_rt_Array_Float_54_15:0, KaTSXR_r_EVM_NtiEqn2Mtrx_KaTSXR_r_EVM_NtiEqn2Mtrx_rt_Array_Float_54_16:0, KaTSXR_r_EVM_NtiEqn2Mtrx_KaTSXR_r_EVM_NtiEqn2Mtrx_rt_Array_Float_54_17:0, KaTSXR_r_EVM_NtiEqn2Mtrx_KaTSXR_r_EVM_NtiEqn2Mtrx_rt_Array_Float_54_18:0, KaTSXR_r_EVM_NtiEqn2Mtrx_KaTSXR_r_EVM_NtiEqn2Mtrx_rt_Array_Float_54_19:0, KaTSXR_r_EVM_NtiEqn2Mtrx_KaTSXR_r_EVM_NtiEqn2Mtrx_rt_Array_Float_54_20:0, KaTSXR_r_EVM_NtiEqn2Mtrx_KaTSXR_r_EVM_NtiEqn2Mtrx_rt_Array_Float_54_21:0, KaTSXR_r_EVM_NtiEqn2Mtrx_KaTSXR_r_EVM_NtiEqn2Mtrx_rt_Array_Float_54_22:0, KaTSXR_r_EVM_NtiEqn2Mtrx_KaTSXR_r_EVM_NtiEqn2Mtrx_rt_Array_Float_54_23:0, KaTSXR_r_EVM_NtiEqn2Mtrx_KaTSXR_r_EVM_NtiEqn2Mtrx_rt_Array_Float_54_24:0, KaTSXR_r_EVM_NtiEqn2Mtrx_KaTSXR_r_EVM_NtiEqn2Mtrx_rt_Array_Float_54_25:0, KaTSXR_r_EVM_NtiEqn2Mtrx_KaTSXR_r_EVM_NtiEqn2Mtrx_rt_Array_Float_54_26:0, KaTSXR_r_EVM_NtiEqn2Mtrx_KaTSXR_r_EVM_NtiEqn2Mtrx_rt_Array_Float_54_27:0, KaTSXR_r_EVM_NtiEqn2Mtrx_KaTSXR_r_EVM_NtiEqn2Mtrx_rt_Array_Float_54_28:0, KaTSXR_r_EVM_NtiEqn2Mtrx_KaTSXR_r_EVM_NtiEqn2Mtrx_rt_Array_Float_54_29:0, KaTSXR_r_EVM_NtiEqn2Mtrx_KaTSXR_r_EVM_NtiEqn2Mtrx_rt_Array_Float_54_30:0, KaTSXR_r_EVM_NtiEqn2Mtrx_KaTSXR_r_EVM_NtiEqn2Mtrx_rt_Array_Float_54_31:0, KaTSXR_r_EVM_NtiEqn2Mtrx_KaTSXR_r_EVM_NtiEqn2Mtrx_rt_Array_Float_54_32:0, KaTSXR_r_EVM_NtiEqn2Mtrx_KaTSXR_r_EVM_NtiEqn2Mtrx_rt_Array_Float_54_33:0, KaTSXR_r_EVM_NtiEqn2Mtrx_KaTSXR_r_EVM_NtiEqn2Mtrx_rt_Array_Float_54_34:0, KaTSXR_r_EVM_NtiEqn2Mtrx_KaTSXR_r_EVM_NtiEqn2Mtrx_rt_Array_Float_54_35:0, KaTSXR_r_EVM_NtiEqn2Mtrx_KaTSXR_r_EVM_NtiEqn2Mtrx_rt_Array_Float_54_36:0, KaTSXR_r_EVM_NtiEqn2Mtrx_KaTSXR_r_EVM_NtiEqn2Mtrx_rt_Array_Float_54_37:0, KaTSXR_r_EVM_NtiEqn2Mtrx_KaTSXR_r_EVM_NtiEqn2Mtrx_rt_Array_Float_54_38:0, KaTSXR_r_EVM_NtiEqn2Mtrx_KaTSXR_r_EVM_NtiEqn2Mtrx_rt_Array_Float_54_39:0, KaTSXR_r_EVM_NtiEqn2Mtrx_KaTSXR_r_EVM_NtiEqn2Mtrx_rt_Array_Float_54_40:0, KaTSXR_r_EVM_NtiEqn2Mtrx_KaTSXR_r_EVM_NtiEqn2Mtrx_rt_Array_Float_54_41:0, KaTSXR_r_EVM_NtiEqn2Mtrx_KaTSXR_r_EVM_NtiEqn2Mtrx_rt_Array_Float_54_42:0, KaTSXR_r_EVM_NtiEqn2Mtrx_KaTSXR_r_EVM_NtiEqn2Mtrx_rt_Array_Float_54_43:0, KaTSXR_r_EVM_NtiEqn2Mtrx_KaTSXR_r_EVM_NtiEqn2Mtrx_rt_Array_Float_54_44:0, KaTSXR_r_EVM_NtiEqn2Mtrx_KaTSXR_r_EVM_NtiEqn2Mtrx_rt_Array_Float_54_45:0, KaTSXR_r_EVM_NtiEqn2Mtrx_KaTSXR_r_EVM_NtiEqn2Mtrx_rt_Array_Float_54_46:0, KaTSXR_r_EVM_NtiEqn2Mtrx_KaTSXR_r_EVM_NtiEqn2Mtrx_rt_Array_Float_54_47:0, KaTSXR_r_EVM_NtiEqn2Mtrx_KaTSXR_r_EVM_NtiEqn2Mtrx_rt_Array_Float_54_48:0, KaTSXR_r_EVM_NtiEqn2Mtrx_KaTSXR_r_EVM_NtiEqn2Mtrx_rt_Array_Float_54_49:0, KaTSXR_r_EVM_NtiEqn2Mtrx_KaTSXR_r_EVM_NtiEqn2Mtrx_rt_Array_Float_54_50:0, KaTSXR_r_EVM_NtiEqn2Mtrx_KaTSXR_r_EVM_NtiEqn2Mtrx_rt_Array_Float_54_51:0, KaTSXR_r_EVM_NtiEqn2Mtrx_KaTSXR_r_EVM_NtiEqn2Mtrx_rt_Array_Float_54_52:0, KaTSXR_r_EVM_NtiEqn2Mtrx_KaTSXR_r_EVM_NtiEqn2Mtrx_rt_Array_Float_54_53:0, KaTSXR_r_EVM_NtiEqn2Mtrx_KaTSXR_r_EVM_NtiEqn2Mtrx_rt_Array_Float_54_54:0], parameter=KaTSXR_r_EVM_NtiEqn2Mtrx}, required-interface=KaTSXR_r_EVM_NtiEqn2Mtrx
      KaTSXR_r_EVM_TM1_ToConstrn: parameter-require-com-spec{init-value=KaTSXR_r_EVM_TM1_ToConstrn_KaTSXR_r_EVM_TM1_ToConstrn:[KaTSXR_r_EVM_TM1_ToConstrn_KaTSXR_r_EVM_TM1_ToConstrn_rt_Array_Float_126_1:0, KaTSXR_r_EVM_TM1_ToConstrn_KaTSXR_r_EVM_TM1_ToConstrn_rt_Array_Float_126_2:0, KaTSXR_r_EVM_TM1_ToConstrn_KaTSXR_r_EVM_TM1_ToConstrn_rt_Array_Float_126_3:0, KaTSXR_r_EVM_TM1_ToConstrn_KaTSXR_r_EVM_TM1_ToConstrn_rt_Array_Float_126_4:0, KaTSXR_r_EVM_TM1_ToConstrn_KaTSXR_r_EVM_TM1_ToConstrn_rt_Array_Float_126_5:0, KaTSXR_r_EVM_TM1_ToConstrn_KaTSXR_r_EVM_TM1_ToConstrn_rt_Array_Float_126_6:0, KaTSXR_r_EVM_TM1_ToConstrn_KaTSXR_r_EVM_TM1_ToConstrn_rt_Array_Float_126_7:0, KaTSXR_r_EVM_TM1_ToConstrn_KaTSXR_r_EVM_TM1_ToConstrn_rt_Array_Float_126_8:0, KaTSXR_r_EVM_TM1_ToConstrn_KaTSXR_r_EVM_TM1_ToConstrn_rt_Array_Float_126_9:0, KaTSXR_r_EVM_TM1_ToConstrn_KaTSXR_r_EVM_TM1_ToConstrn_rt_Array_Float_126_10:0, KaTSXR_r_EVM_TM1_ToConstrn_KaTSXR_r_EVM_TM1_ToConstrn_rt_Array_Float_126_11:0, KaTSXR_r_EVM_TM1_ToConstrn_KaTSXR_r_EVM_TM1_ToConstrn_rt_Array_Float_126_12:0, KaTSXR_r_EVM_TM1_ToConstrn_KaTSXR_r_EVM_TM1_ToConstrn_rt_Array_Float_126_13:0, KaTSXR_r_EVM_TM1_ToConstrn_KaTSXR_r_EVM_TM1_ToConstrn_rt_Array_Float_126_14:0, KaTSXR_r_EVM_TM1_ToConstrn_KaTSXR_r_EVM_TM1_ToConstrn_rt_Array_Float_126_15:0, KaTSXR_r_EVM_TM1_ToConstrn_KaTSXR_r_EVM_TM1_ToConstrn_rt_Array_Float_126_16:0, KaTSXR_r_EVM_TM1_ToConstrn_KaTSXR_r_EVM_TM1_ToConstrn_rt_Array_Float_126_17:0, KaTSXR_r_EVM_TM1_ToConstrn_KaTSXR_r_EVM_TM1_ToConstrn_rt_Array_Float_126_18:0, KaTSXR_r_EVM_TM1_ToConstrn_KaTSXR_r_EVM_TM1_ToConstrn_rt_Array_Float_126_19:0, KaTSXR_r_EVM_TM1_ToConstrn_KaTSXR_r_EVM_TM1_ToConstrn_rt_Array_Float_126_20:0, KaTSXR_r_EVM_TM1_ToConstrn_KaTSXR_r_EVM_TM1_ToConstrn_rt_Array_Float_126_21:0, KaTSXR_r_EVM_TM1_ToConstrn_KaTSXR_r_EVM_TM1_ToConstrn_rt_Array_Float_126_22:0, KaTSXR_r_EVM_TM1_ToConstrn_KaTSXR_r_EVM_TM1_ToConstrn_rt_Array_Float_126_23:0, KaTSXR_r_EVM_TM1_ToConstrn_KaTSXR_r_EVM_TM1_ToConstrn_rt_Array_Float_126_24:0, KaTSXR_r_EVM_TM1_ToConstrn_KaTSXR_r_EVM_TM1_ToConstrn_rt_Array_Float_126_25:0, KaTSXR_r_EVM_TM1_ToConstrn_KaTSXR_r_EVM_TM1_ToConstrn_rt_Array_Float_126_26:0, KaTSXR_r_EVM_TM1_ToConstrn_KaTSXR_r_EVM_TM1_ToConstrn_rt_Array_Float_126_27:0, KaTSXR_r_EVM_TM1_ToConstrn_KaTSXR_r_EVM_TM1_ToConstrn_rt_Array_Float_126_28:0, KaTSXR_r_EVM_TM1_ToConstrn_KaTSXR_r_EVM_TM1_ToConstrn_rt_Array_Float_126_29:0, KaTSXR_r_EVM_TM1_ToConstrn_KaTSXR_r_EVM_TM1_ToConstrn_rt_Array_Float_126_30:0, KaTSXR_r_EVM_TM1_ToConstrn_KaTSXR_r_EVM_TM1_ToConstrn_rt_Array_Float_126_31:0, KaTSXR_r_EVM_TM1_ToConstrn_KaTSXR_r_EVM_TM1_ToConstrn_rt_Array_Float_126_32:0, KaTSXR_r_EVM_TM1_ToConstrn_KaTSXR_r_EVM_TM1_ToConstrn_rt_Array_Float_126_33:0, KaTSXR_r_EVM_TM1_ToConstrn_KaTSXR_r_EVM_TM1_ToConstrn_rt_Array_Float_126_34:0, KaTSXR_r_EVM_TM1_ToConstrn_KaTSXR_r_EVM_TM1_ToConstrn_rt_Array_Float_126_35:0, KaTSXR_r_EVM_TM1_ToConstrn_KaTSXR_r_EVM_TM1_ToConstrn_rt_Array_Float_126_36:0, KaTSXR_r_EVM_TM1_ToConstrn_KaTSXR_r_EVM_TM1_ToConstrn_rt_Array_Float_126_37:0, KaTSXR_r_EVM_TM1_ToConstrn_KaTSXR_r_EVM_TM1_ToConstrn_rt_Array_Float_126_38:0, KaTSXR_r_EVM_TM1_ToConstrn_KaTSXR_r_EVM_TM1_ToConstrn_rt_Array_Float_126_39:0, KaTSXR_r_EVM_TM1_ToConstrn_KaTSXR_r_EVM_TM1_ToConstrn_rt_Array_Float_126_40:0, KaTSXR_r_EVM_TM1_ToConstrn_KaTSXR_r_EVM_TM1_ToConstrn_rt_Array_Float_126_41:0, KaTSXR_r_EVM_TM1_ToConstrn_KaTSXR_r_EVM_TM1_ToConstrn_rt_Array_Float_126_42:0, KaTSXR_r_EVM_TM1_ToConstrn_KaTSXR_r_EVM_TM1_ToConstrn_rt_Array_Float_126_43:0, KaTSXR_r_EVM_TM1_ToConstrn_KaTSXR_r_EVM_TM1_ToConstrn_rt_Array_Float_126_44:0, KaTSXR_r_EVM_TM1_ToConstrn_KaTSXR_r_EVM_TM1_ToConstrn_rt_Array_Float_126_45:0, KaTSXR_r_EVM_TM1_ToConstrn_KaTSXR_r_EVM_TM1_ToConstrn_rt_Array_Float_126_46:0, KaTSXR_r_EVM_TM1_ToConstrn_KaTSXR_r_EVM_TM1_ToConstrn_rt_Array_Float_126_47:0, KaTSXR_r_EVM_TM1_ToConstrn_KaTSXR_r_EVM_TM1_ToConstrn_rt_Array_Float_126_48:0, KaTSXR_r_EVM_TM1_ToConstrn_KaTSXR_r_EVM_TM1_ToConstrn_rt_Array_Float_126_49:0, KaTSXR_r_EVM_TM1_ToConstrn_KaTSXR_r_EVM_TM1_ToConstrn_rt_Array_Float_126_50:0, KaTSXR_r_EVM_TM1_ToConstrn_KaTSXR_r_EVM_TM1_ToConstrn_rt_Array_Float_126_51:0, KaTSXR_r_EVM_TM1_ToConstrn_KaTSXR_r_EVM_TM1_ToConstrn_rt_Array_Float_126_52:0, KaTSXR_r_EVM_TM1_ToConstrn_KaTSXR_r_EVM_TM1_ToConstrn_rt_Array_Float_126_53:0, KaTSXR_r_EVM_TM1_ToConstrn_KaTSXR_r_EVM_TM1_ToConstrn_rt_Array_Float_126_54:0, KaTSXR_r_EVM_TM1_ToConstrn_KaTSXR_r_EVM_TM1_ToConstrn_rt_Array_Float_126_55:0, KaTSXR_r_EVM_TM1_ToConstrn_KaTSXR_r_EVM_TM1_ToConstrn_rt_Array_Float_126_56:0, KaTSXR_r_EVM_TM1_ToConstrn_KaTSXR_r_EVM_TM1_ToConstrn_rt_Array_Float_126_57:0, KaTSXR_r_EVM_TM1_ToConstrn_KaTSXR_r_EVM_TM1_ToConstrn_rt_Array_Float_126_58:0, KaTSXR_r_EVM_TM1_ToConstrn_KaTSXR_r_EVM_TM1_ToConstrn_rt_Array_Float_126_59:0, KaTSXR_r_EVM_TM1_ToConstrn_KaTSXR_r_EVM_TM1_ToConstrn_rt_Array_Float_126_60:0, KaTSXR_r_EVM_TM1_ToConstrn_KaTSXR_r_EVM_TM1_ToConstrn_rt_Array_Float_126_61:0, KaTSXR_r_EVM_TM1_ToConstrn_KaTSXR_r_EVM_TM1_ToConstrn_rt_Array_Float_126_62:0, KaTSXR_r_EVM_TM1_ToConstrn_KaTSXR_r_EVM_TM1_ToConstrn_rt_Array_Float_126_63:0, KaTSXR_r_EVM_TM1_ToConstrn_KaTSXR_r_EVM_TM1_ToConstrn_rt_Array_Float_126_64:0, KaTSXR_r_EVM_TM1_ToConstrn_KaTSXR_r_EVM_TM1_ToConstrn_rt_Array_Float_126_65:0, KaTSXR_r_EVM_TM1_ToConstrn_KaTSXR_r_EVM_TM1_ToConstrn_rt_Array_Float_126_66:0, KaTSXR_r_EVM_TM1_ToConstrn_KaTSXR_r_EVM_TM1_ToConstrn_rt_Array_Float_126_67:0, KaTSXR_r_EVM_TM1_ToConstrn_KaTSXR_r_EVM_TM1_ToConstrn_rt_Array_Float_126_68:0, KaTSXR_r_EVM_TM1_ToConstrn_KaTSXR_r_EVM_TM1_ToConstrn_rt_Array_Float_126_69:0, KaTSXR_r_EVM_TM1_ToConstrn_KaTSXR_r_EVM_TM1_ToConstrn_rt_Array_Float_126_70:0, KaTSXR_r_EVM_TM1_ToConstrn_KaTSXR_r_EVM_TM1_ToConstrn_rt_Array_Float_126_71:0, KaTSXR_r_EVM_TM1_ToConstrn_KaTSXR_r_EVM_TM1_ToConstrn_rt_Array_Float_126_72:0, KaTSXR_r_EVM_TM1_ToConstrn_KaTSXR_r_EVM_TM1_ToConstrn_rt_Array_Float_126_73:0, KaTSXR_r_EVM_TM1_ToConstrn_KaTSXR_r_EVM_TM1_ToConstrn_rt_Array_Float_126_74:0, KaTSXR_r_EVM_TM1_ToConstrn_KaTSXR_r_EVM_TM1_ToConstrn_rt_Array_Float_126_75:0, KaTSXR_r_EVM_TM1_ToConstrn_KaTSXR_r_EVM_TM1_ToConstrn_rt_Array_Float_126_76:0, KaTSXR_r_EVM_TM1_ToConstrn_KaTSXR_r_EVM_TM1_ToConstrn_rt_Array_Float_126_77:0, KaTSXR_r_EVM_TM1_ToConstrn_KaTSXR_r_EVM_TM1_ToConstrn_rt_Array_Float_126_78:0, KaTSXR_r_EVM_TM1_ToConstrn_KaTSXR_r_EVM_TM1_ToConstrn_rt_Array_Float_126_79:0, KaTSXR_r_EVM_TM1_ToConstrn_KaTSXR_r_EVM_TM1_ToConstrn_rt_Array_Float_126_80:0, KaTSXR_r_EVM_TM1_ToConstrn_KaTSXR_r_EVM_TM1_ToConstrn_rt_Array_Float_126_81:0, KaTSXR_r_EVM_TM1_ToConstrn_KaTSXR_r_EVM_TM1_ToConstrn_rt_Array_Float_126_82:0, KaTSXR_r_EVM_TM1_ToConstrn_KaTSXR_r_EVM_TM1_ToConstrn_rt_Array_Float_126_83:0, KaTSXR_r_EVM_TM1_ToConstrn_KaTSXR_r_EVM_TM1_ToConstrn_rt_Array_Float_126_84:0, KaTSXR_r_EVM_TM1_ToConstrn_KaTSXR_r_EVM_TM1_ToConstrn_rt_Array_Float_126_85:0, KaTSXR_r_EVM_TM1_ToConstrn_KaTSXR_r_EVM_TM1_ToConstrn_rt_Array_Float_126_86:0, KaTSXR_r_EVM_TM1_ToConstrn_KaTSXR_r_EVM_TM1_ToConstrn_rt_Array_Float_126_87:0, KaTSXR_r_EVM_TM1_ToConstrn_KaTSXR_r_EVM_TM1_ToConstrn_rt_Array_Float_126_88:0, KaTSXR_r_EVM_TM1_ToConstrn_KaTSXR_r_EVM_TM1_ToConstrn_rt_Array_Float_126_89:0, KaTSXR_r_EVM_TM1_ToConstrn_KaTSXR_r_EVM_TM1_ToConstrn_rt_Array_Float_126_90:0, KaTSXR_r_EVM_TM1_ToConstrn_KaTSXR_r_EVM_TM1_ToConstrn_rt_Array_Float_126_91:0, KaTSXR_r_EVM_TM1_ToConstrn_KaTSXR_r_EVM_TM1_ToConstrn_rt_Array_Float_126_92:0, KaTSXR_r_EVM_TM1_ToConstrn_KaTSXR_r_EVM_TM1_ToConstrn_rt_Array_Float_126_93:0, KaTSXR_r_EVM_TM1_ToConstrn_KaTSXR_r_EVM_TM1_ToConstrn_rt_Array_Float_126_94:0, KaTSXR_r_EVM_TM1_ToConstrn_KaTSXR_r_EVM_TM1_ToConstrn_rt_Array_Float_126_95:0, KaTSXR_r_EVM_TM1_ToConstrn_KaTSXR_r_EVM_TM1_ToConstrn_rt_Array_Float_126_96:0, KaTSXR_r_EVM_TM1_ToConstrn_KaTSXR_r_EVM_TM1_ToConstrn_rt_Array_Float_126_97:0, KaTSXR_r_EVM_TM1_ToConstrn_KaTSXR_r_EVM_TM1_ToConstrn_rt_Array_Float_126_98:0, KaTSXR_r_EVM_TM1_ToConstrn_KaTSXR_r_EVM_TM1_ToConstrn_rt_Array_Float_126_99:0, KaTSXR_r_EVM_TM1_ToConstrn_KaTSXR_r_EVM_TM1_ToConstrn_rt_Array_Float_126_100:0, KaTSXR_r_EVM_TM1_ToConstrn_KaTSXR_r_EVM_TM1_ToConstrn_rt_Array_Float_126_101:0, KaTSXR_r_EVM_TM1_ToConstrn_KaTSXR_r_EVM_TM1_ToConstrn_rt_Array_Float_126_102:0, KaTSXR_r_EVM_TM1_ToConstrn_KaTSXR_r_EVM_TM1_ToConstrn_rt_Array_Float_126_103:0, KaTSXR_r_EVM_TM1_ToConstrn_KaTSXR_r_EVM_TM1_ToConstrn_rt_Array_Float_126_104:0, KaTSXR_r_EVM_TM1_ToConstrn_KaTSXR_r_EVM_TM1_ToConstrn_rt_Array_Float_126_105:0, KaTSXR_r_EVM_TM1_ToConstrn_KaTSXR_r_EVM_TM1_ToConstrn_rt_Array_Float_126_106:0, KaTSXR_r_EVM_TM1_ToConstrn_KaTSXR_r_EVM_TM1_ToConstrn_rt_Array_Float_126_107:0, KaTSXR_r_EVM_TM1_ToConstrn_KaTSXR_r_EVM_TM1_ToConstrn_rt_Array_Float_126_108:0, KaTSXR_r_EVM_TM1_ToConstrn_KaTSXR_r_EVM_TM1_ToConstrn_rt_Array_Float_126_109:0, KaTSXR_r_EVM_TM1_ToConstrn_KaTSXR_r_EVM_TM1_ToConstrn_rt_Array_Float_126_110:0, KaTSXR_r_EVM_TM1_ToConstrn_KaTSXR_r_EVM_TM1_ToConstrn_rt_Array_Float_126_111:0, KaTSXR_r_EVM_TM1_ToConstrn_KaTSXR_r_EVM_TM1_ToConstrn_rt_Array_Float_126_112:0, KaTSXR_r_EVM_TM1_ToConstrn_KaTSXR_r_EVM_TM1_ToConstrn_rt_Array_Float_126_113:0, KaTSXR_r_EVM_TM1_ToConstrn_KaTSXR_r_EVM_TM1_ToConstrn_rt_Array_Float_126_114:0, KaTSXR_r_EVM_TM1_ToConstrn_KaTSXR_r_EVM_TM1_ToConstrn_rt_Array_Float_126_115:0, KaTSXR_r_EVM_TM1_ToConstrn_KaTSXR_r_EVM_TM1_ToConstrn_rt_Array_Float_126_116:0, KaTSXR_r_EVM_TM1_ToConstrn_KaTSXR_r_EVM_TM1_ToConstrn_rt_Array_Float_126_117:0, KaTSXR_r_EVM_TM1_ToConstrn_KaTSXR_r_EVM_TM1_ToConstrn_rt_Array_Float_126_118:0, KaTSXR_r_EVM_TM1_ToConstrn_KaTSXR_r_EVM_TM1_ToConstrn_rt_Array_Float_126_119:0, KaTSXR_r_EVM_TM1_ToConstrn_KaTSXR_r_EVM_TM1_ToConstrn_rt_Array_Float_126_120:0, KaTSXR_r_EVM_TM1_ToConstrn_KaTSXR_r_EVM_TM1_ToConstrn_rt_Array_Float_126_121:0, KaTSXR_r_EVM_TM1_ToConstrn_KaTSXR_r_EVM_TM1_ToConstrn_rt_Array_Float_126_122:0, KaTSXR_r_EVM_TM1_ToConstrn_KaTSXR_r_EVM_TM1_ToConstrn_rt_Array_Float_126_123:0, KaTSXR_r_EVM_TM1_ToConstrn_KaTSXR_r_EVM_TM1_ToConstrn_rt_Array_Float_126_124:0, KaTSXR_r_EVM_TM1_ToConstrn_KaTSXR_r_EVM_TM1_ToConstrn_rt_Array_Float_126_125:0, KaTSXR_r_EVM_TM1_ToConstrn_KaTSXR_r_EVM_TM1_ToConstrn_rt_Array_Float_126_126:0], parameter=KaTSXR_r_EVM_TM1_ToConstrn}, required-interface=KaTSXR_r_EVM_TM1_ToConstrn
      KaTSXR_r_EVN_NaCalcEqnMtrx: parameter-require-com-spec{init-value=KaTSXR_r_EVN_NaCalcEqnMtrx_KaTSXR_r_EVN_NaCalcEqnMtrx:[KaTSXR_r_EVN_NaCalcEqnMtrx_KaTSXR_r_EVN_NaCalcEqnMtrx_rt_Array_Float_27_1:0, KaTSXR_r_EVN_NaCalcEqnMtrx_KaTSXR_r_EVN_NaCalcEqnMtrx_rt_Array_Float_27_2:0, KaTSXR_r_EVN_NaCalcEqnMtrx_KaTSXR_r_EVN_NaCalcEqnMtrx_rt_Array_Float_27_3:0, KaTSXR_r_EVN_NaCalcEqnMtrx_KaTSXR_r_EVN_NaCalcEqnMtrx_rt_Array_Float_27_4:0, KaTSXR_r_EVN_NaCalcEqnMtrx_KaTSXR_r_EVN_NaCalcEqnMtrx_rt_Array_Float_27_5:0, KaTSXR_r_EVN_NaCalcEqnMtrx_KaTSXR_r_EVN_NaCalcEqnMtrx_rt_Array_Float_27_6:0, KaTSXR_r_EVN_NaCalcEqnMtrx_KaTSXR_r_EVN_NaCalcEqnMtrx_rt_Array_Float_27_7:0, KaTSXR_r_EVN_NaCalcEqnMtrx_KaTSXR_r_EVN_NaCalcEqnMtrx_rt_Array_Float_27_8:0, KaTSXR_r_EVN_NaCalcEqnMtrx_KaTSXR_r_EVN_NaCalcEqnMtrx_rt_Array_Float_27_9:0, KaTSXR_r_EVN_NaCalcEqnMtrx_KaTSXR_r_EVN_NaCalcEqnMtrx_rt_Array_Float_27_10:0, KaTSXR_r_EVN_NaCalcEqnMtrx_KaTSXR_r_EVN_NaCalcEqnMtrx_rt_Array_Float_27_11:0, KaTSXR_r_EVN_NaCalcEqnMtrx_KaTSXR_r_EVN_NaCalcEqnMtrx_rt_Array_Float_27_12:0, KaTSXR_r_EVN_NaCalcEqnMtrx_KaTSXR_r_EVN_NaCalcEqnMtrx_rt_Array_Float_27_13:0, KaTSXR_r_EVN_NaCalcEqnMtrx_KaTSXR_r_EVN_NaCalcEqnMtrx_rt_Array_Float_27_14:0, KaTSXR_r_EVN_NaCalcEqnMtrx_KaTSXR_r_EVN_NaCalcEqnMtrx_rt_Array_Float_27_15:0, KaTSXR_r_EVN_NaCalcEqnMtrx_KaTSXR_r_EVN_NaCalcEqnMtrx_rt_Array_Float_27_16:0, KaTSXR_r_EVN_NaCalcEqnMtrx_KaTSXR_r_EVN_NaCalcEqnMtrx_rt_Array_Float_27_17:0, KaTSXR_r_EVN_NaCalcEqnMtrx_KaTSXR_r_EVN_NaCalcEqnMtrx_rt_Array_Float_27_18:0, KaTSXR_r_EVN_NaCalcEqnMtrx_KaTSXR_r_EVN_NaCalcEqnMtrx_rt_Array_Float_27_19:0, KaTSXR_r_EVN_NaCalcEqnMtrx_KaTSXR_r_EVN_NaCalcEqnMtrx_rt_Array_Float_27_20:0, KaTSXR_r_EVN_NaCalcEqnMtrx_KaTSXR_r_EVN_NaCalcEqnMtrx_rt_Array_Float_27_21:0, KaTSXR_r_EVN_NaCalcEqnMtrx_KaTSXR_r_EVN_NaCalcEqnMtrx_rt_Array_Float_27_22:0, KaTSXR_r_EVN_NaCalcEqnMtrx_KaTSXR_r_EVN_NaCalcEqnMtrx_rt_Array_Float_27_23:0, KaTSXR_r_EVN_NaCalcEqnMtrx_KaTSXR_r_EVN_NaCalcEqnMtrx_rt_Array_Float_27_24:0, KaTSXR_r_EVN_NaCalcEqnMtrx_KaTSXR_r_EVN_NaCalcEqnMtrx_rt_Array_Float_27_25:0, KaTSXR_r_EVN_NaCalcEqnMtrx_KaTSXR_r_EVN_NaCalcEqnMtrx_rt_Array_Float_27_26:0, KaTSXR_r_EVN_NaCalcEqnMtrx_KaTSXR_r_EVN_NaCalcEqnMtrx_rt_Array_Float_27_27:0], parameter=KaTSXR_r_EVN_NaCalcEqnMtrx}, required-interface=KaTSXR_r_EVN_NaCalcEqnMtrx
      KaTSXR_r_EVN_NbCalcEqnMtrx: parameter-require-com-spec{init-value=KaTSXR_r_EVN_NbCalcEqnMtrx_KaTSXR_r_EVN_NbCalcEqnMtrx:[KaTSXR_r_EVN_NbCalcEqnMtrx_KaTSXR_r_EVN_NbCalcEqnMtrx_rt_Array_Float_27_1:0, KaTSXR_r_EVN_NbCalcEqnMtrx_KaTSXR_r_EVN_NbCalcEqnMtrx_rt_Array_Float_27_2:0, KaTSXR_r_EVN_NbCalcEqnMtrx_KaTSXR_r_EVN_NbCalcEqnMtrx_rt_Array_Float_27_3:0, KaTSXR_r_EVN_NbCalcEqnMtrx_KaTSXR_r_EVN_NbCalcEqnMtrx_rt_Array_Float_27_4:0, KaTSXR_r_EVN_NbCalcEqnMtrx_KaTSXR_r_EVN_NbCalcEqnMtrx_rt_Array_Float_27_5:0, KaTSXR_r_EVN_NbCalcEqnMtrx_KaTSXR_r_EVN_NbCalcEqnMtrx_rt_Array_Float_27_6:0, KaTSXR_r_EVN_NbCalcEqnMtrx_KaTSXR_r_EVN_NbCalcEqnMtrx_rt_Array_Float_27_7:0, KaTSXR_r_EVN_NbCalcEqnMtrx_KaTSXR_r_EVN_NbCalcEqnMtrx_rt_Array_Float_27_8:0, KaTSXR_r_EVN_NbCalcEqnMtrx_KaTSXR_r_EVN_NbCalcEqnMtrx_rt_Array_Float_27_9:0, KaTSXR_r_EVN_NbCalcEqnMtrx_KaTSXR_r_EVN_NbCalcEqnMtrx_rt_Array_Float_27_10:0, KaTSXR_r_EVN_NbCalcEqnMtrx_KaTSXR_r_EVN_NbCalcEqnMtrx_rt_Array_Float_27_11:0, KaTSXR_r_EVN_NbCalcEqnMtrx_KaTSXR_r_EVN_NbCalcEqnMtrx_rt_Array_Float_27_12:0, KaTSXR_r_EVN_NbCalcEqnMtrx_KaTSXR_r_EVN_NbCalcEqnMtrx_rt_Array_Float_27_13:0, KaTSXR_r_EVN_NbCalcEqnMtrx_KaTSXR_r_EVN_NbCalcEqnMtrx_rt_Array_Float_27_14:0, KaTSXR_r_EVN_NbCalcEqnMtrx_KaTSXR_r_EVN_NbCalcEqnMtrx_rt_Array_Float_27_15:0, KaTSXR_r_EVN_NbCalcEqnMtrx_KaTSXR_r_EVN_NbCalcEqnMtrx_rt_Array_Float_27_16:0, KaTSXR_r_EVN_NbCalcEqnMtrx_KaTSXR_r_EVN_NbCalcEqnMtrx_rt_Array_Float_27_17:0, KaTSXR_r_EVN_NbCalcEqnMtrx_KaTSXR_r_EVN_NbCalcEqnMtrx_rt_Array_Float_27_18:0, KaTSXR_r_EVN_NbCalcEqnMtrx_KaTSXR_r_EVN_NbCalcEqnMtrx_rt_Array_Float_27_19:0, KaTSXR_r_EVN_NbCalcEqnMtrx_KaTSXR_r_EVN_NbCalcEqnMtrx_rt_Array_Float_27_20:0, KaTSXR_r_EVN_NbCalcEqnMtrx_KaTSXR_r_EVN_NbCalcEqnMtrx_rt_Array_Float_27_21:0, KaTSXR_r_EVN_NbCalcEqnMtrx_KaTSXR_r_EVN_NbCalcEqnMtrx_rt_Array_Float_27_22:0, KaTSXR_r_EVN_NbCalcEqnMtrx_KaTSXR_r_EVN_NbCalcEqnMtrx_rt_Array_Float_27_23:0, KaTSXR_r_EVN_NbCalcEqnMtrx_KaTSXR_r_EVN_NbCalcEqnMtrx_rt_Array_Float_27_24:0, KaTSXR_r_EVN_NbCalcEqnMtrx_KaTSXR_r_EVN_NbCalcEqnMtrx_rt_Array_Float_27_25:0, KaTSXR_r_EVN_NbCalcEqnMtrx_KaTSXR_r_EVN_NbCalcEqnMtrx_rt_Array_Float_27_26:0, KaTSXR_r_EVN_NbCalcEqnMtrx_KaTSXR_r_EVN_NbCalcEqnMtrx_rt_Array_Float_27_27:0], parameter=KaTSXR_r_EVN_NbCalcEqnMtrx}, required-interface=KaTSXR_r_EVN_NbCalcEqnMtrx
      KaTSXR_r_EVN_Nc1CalcEqnMtrx: parameter-require-com-spec{init-value=KaTSXR_r_EVN_Nc1CalcEqnMtrx_KaTSXR_r_EVN_Nc1CalcEqnMtrx:[KaTSXR_r_EVN_Nc1CalcEqnMtrx_KaTSXR_r_EVN_Nc1CalcEqnMtrx_rt_Array_Float_27_1:0, KaTSXR_r_EVN_Nc1CalcEqnMtrx_KaTSXR_r_EVN_Nc1CalcEqnMtrx_rt_Array_Float_27_2:0, KaTSXR_r_EVN_Nc1CalcEqnMtrx_KaTSXR_r_EVN_Nc1CalcEqnMtrx_rt_Array_Float_27_3:0, KaTSXR_r_EVN_Nc1CalcEqnMtrx_KaTSXR_r_EVN_Nc1CalcEqnMtrx_rt_Array_Float_27_4:0, KaTSXR_r_EVN_Nc1CalcEqnMtrx_KaTSXR_r_EVN_Nc1CalcEqnMtrx_rt_Array_Float_27_5:0, KaTSXR_r_EVN_Nc1CalcEqnMtrx_KaTSXR_r_EVN_Nc1CalcEqnMtrx_rt_Array_Float_27_6:0, KaTSXR_r_EVN_Nc1CalcEqnMtrx_KaTSXR_r_EVN_Nc1CalcEqnMtrx_rt_Array_Float_27_7:0, KaTSXR_r_EVN_Nc1CalcEqnMtrx_KaTSXR_r_EVN_Nc1CalcEqnMtrx_rt_Array_Float_27_8:0, KaTSXR_r_EVN_Nc1CalcEqnMtrx_KaTSXR_r_EVN_Nc1CalcEqnMtrx_rt_Array_Float_27_9:0, KaTSXR_r_EVN_Nc1CalcEqnMtrx_KaTSXR_r_EVN_Nc1CalcEqnMtrx_rt_Array_Float_27_10:0, KaTSXR_r_EVN_Nc1CalcEqnMtrx_KaTSXR_r_EVN_Nc1CalcEqnMtrx_rt_Array_Float_27_11:0, KaTSXR_r_EVN_Nc1CalcEqnMtrx_KaTSXR_r_EVN_Nc1CalcEqnMtrx_rt_Array_Float_27_12:0, KaTSXR_r_EVN_Nc1CalcEqnMtrx_KaTSXR_r_EVN_Nc1CalcEqnMtrx_rt_Array_Float_27_13:0, KaTSXR_r_EVN_Nc1CalcEqnMtrx_KaTSXR_r_EVN_Nc1CalcEqnMtrx_rt_Array_Float_27_14:0, KaTSXR_r_EVN_Nc1CalcEqnMtrx_KaTSXR_r_EVN_Nc1CalcEqnMtrx_rt_Array_Float_27_15:0, KaTSXR_r_EVN_Nc1CalcEqnMtrx_KaTSXR_r_EVN_Nc1CalcEqnMtrx_rt_Array_Float_27_16:0, KaTSXR_r_EVN_Nc1CalcEqnMtrx_KaTSXR_r_EVN_Nc1CalcEqnMtrx_rt_Array_Float_27_17:0, KaTSXR_r_EVN_Nc1CalcEqnMtrx_KaTSXR_r_EVN_Nc1CalcEqnMtrx_rt_Array_Float_27_18:0, KaTSXR_r_EVN_Nc1CalcEqnMtrx_KaTSXR_r_EVN_Nc1CalcEqnMtrx_rt_Array_Float_27_19:0, KaTSXR_r_EVN_Nc1CalcEqnMtrx_KaTSXR_r_EVN_Nc1CalcEqnMtrx_rt_Array_Float_27_20:0, KaTSXR_r_EVN_Nc1CalcEqnMtrx_KaTSXR_r_EVN_Nc1CalcEqnMtrx_rt_Array_Float_27_21:0, KaTSXR_r_EVN_Nc1CalcEqnMtrx_KaTSXR_r_EVN_Nc1CalcEqnMtrx_rt_Array_Float_27_22:0, KaTSXR_r_EVN_Nc1CalcEqnMtrx_KaTSXR_r_EVN_Nc1CalcEqnMtrx_rt_Array_Float_27_23:0, KaTSXR_r_EVN_Nc1CalcEqnMtrx_KaTSXR_r_EVN_Nc1CalcEqnMtrx_rt_Array_Float_27_24:0, KaTSXR_r_EVN_Nc1CalcEqnMtrx_KaTSXR_r_EVN_Nc1CalcEqnMtrx_rt_Array_Float_27_25:0, KaTSXR_r_EVN_Nc1CalcEqnMtrx_KaTSXR_r_EVN_Nc1CalcEqnMtrx_rt_Array_Float_27_26:0, KaTSXR_r_EVN_Nc1CalcEqnMtrx_KaTSXR_r_EVN_Nc1CalcEqnMtrx_rt_Array_Float_27_27:0], parameter=KaTSXR_r_EVN_Nc1CalcEqnMtrx}, required-interface=KaTSXR_r_EVN_Nc1CalcEqnMtrx
      KaTSXR_r_EVN_Nc1Eqn1Mtrx: parameter-require-com-spec{init-value=KaTSXR_r_EVN_Nc1Eqn1Mtrx_KaTSXR_r_EVN_Nc1Eqn1Mtrx:[KaTSXR_r_EVN_Nc1Eqn1Mtrx_KaTSXR_r_EVN_Nc1Eqn1Mtrx_rt_Array_Float_54_1:0, KaTSXR_r_EVN_Nc1Eqn1Mtrx_KaTSXR_r_EVN_Nc1Eqn1Mtrx_rt_Array_Float_54_2:0, KaTSXR_r_EVN_Nc1Eqn1Mtrx_KaTSXR_r_EVN_Nc1Eqn1Mtrx_rt_Array_Float_54_3:0, KaTSXR_r_EVN_Nc1Eqn1Mtrx_KaTSXR_r_EVN_Nc1Eqn1Mtrx_rt_Array_Float_54_4:0, KaTSXR_r_EVN_Nc1Eqn1Mtrx_KaTSXR_r_EVN_Nc1Eqn1Mtrx_rt_Array_Float_54_5:0, KaTSXR_r_EVN_Nc1Eqn1Mtrx_KaTSXR_r_EVN_Nc1Eqn1Mtrx_rt_Array_Float_54_6:0, KaTSXR_r_EVN_Nc1Eqn1Mtrx_KaTSXR_r_EVN_Nc1Eqn1Mtrx_rt_Array_Float_54_7:0, KaTSXR_r_EVN_Nc1Eqn1Mtrx_KaTSXR_r_EVN_Nc1Eqn1Mtrx_rt_Array_Float_54_8:0, KaTSXR_r_EVN_Nc1Eqn1Mtrx_KaTSXR_r_EVN_Nc1Eqn1Mtrx_rt_Array_Float_54_9:0, KaTSXR_r_EVN_Nc1Eqn1Mtrx_KaTSXR_r_EVN_Nc1Eqn1Mtrx_rt_Array_Float_54_10:0, KaTSXR_r_EVN_Nc1Eqn1Mtrx_KaTSXR_r_EVN_Nc1Eqn1Mtrx_rt_Array_Float_54_11:0, KaTSXR_r_EVN_Nc1Eqn1Mtrx_KaTSXR_r_EVN_Nc1Eqn1Mtrx_rt_Array_Float_54_12:0, KaTSXR_r_EVN_Nc1Eqn1Mtrx_KaTSXR_r_EVN_Nc1Eqn1Mtrx_rt_Array_Float_54_13:0, KaTSXR_r_EVN_Nc1Eqn1Mtrx_KaTSXR_r_EVN_Nc1Eqn1Mtrx_rt_Array_Float_54_14:0, KaTSXR_r_EVN_Nc1Eqn1Mtrx_KaTSXR_r_EVN_Nc1Eqn1Mtrx_rt_Array_Float_54_15:0, KaTSXR_r_EVN_Nc1Eqn1Mtrx_KaTSXR_r_EVN_Nc1Eqn1Mtrx_rt_Array_Float_54_16:0, KaTSXR_r_EVN_Nc1Eqn1Mtrx_KaTSXR_r_EVN_Nc1Eqn1Mtrx_rt_Array_Float_54_17:0, KaTSXR_r_EVN_Nc1Eqn1Mtrx_KaTSXR_r_EVN_Nc1Eqn1Mtrx_rt_Array_Float_54_18:0, KaTSXR_r_EVN_Nc1Eqn1Mtrx_KaTSXR_r_EVN_Nc1Eqn1Mtrx_rt_Array_Float_54_19:0, KaTSXR_r_EVN_Nc1Eqn1Mtrx_KaTSXR_r_EVN_Nc1Eqn1Mtrx_rt_Array_Float_54_20:0, KaTSXR_r_EVN_Nc1Eqn1Mtrx_KaTSXR_r_EVN_Nc1Eqn1Mtrx_rt_Array_Float_54_21:0, KaTSXR_r_EVN_Nc1Eqn1Mtrx_KaTSXR_r_EVN_Nc1Eqn1Mtrx_rt_Array_Float_54_22:0, KaTSXR_r_EVN_Nc1Eqn1Mtrx_KaTSXR_r_EVN_Nc1Eqn1Mtrx_rt_Array_Float_54_23:0, KaTSXR_r_EVN_Nc1Eqn1Mtrx_KaTSXR_r_EVN_Nc1Eqn1Mtrx_rt_Array_Float_54_24:0, KaTSXR_r_EVN_Nc1Eqn1Mtrx_KaTSXR_r_EVN_Nc1Eqn1Mtrx_rt_Array_Float_54_25:0, KaTSXR_r_EVN_Nc1Eqn1Mtrx_KaTSXR_r_EVN_Nc1Eqn1Mtrx_rt_Array_Float_54_26:0, KaTSXR_r_EVN_Nc1Eqn1Mtrx_KaTSXR_r_EVN_Nc1Eqn1Mtrx_rt_Array_Float_54_27:0, KaTSXR_r_EVN_Nc1Eqn1Mtrx_KaTSXR_r_EVN_Nc1Eqn1Mtrx_rt_Array_Float_54_28:0, KaTSXR_r_EVN_Nc1Eqn1Mtrx_KaTSXR_r_EVN_Nc1Eqn1Mtrx_rt_Array_Float_54_29:0, KaTSXR_r_EVN_Nc1Eqn1Mtrx_KaTSXR_r_EVN_Nc1Eqn1Mtrx_rt_Array_Float_54_30:0, KaTSXR_r_EVN_Nc1Eqn1Mtrx_KaTSXR_r_EVN_Nc1Eqn1Mtrx_rt_Array_Float_54_31:0, KaTSXR_r_EVN_Nc1Eqn1Mtrx_KaTSXR_r_EVN_Nc1Eqn1Mtrx_rt_Array_Float_54_32:0, KaTSXR_r_EVN_Nc1Eqn1Mtrx_KaTSXR_r_EVN_Nc1Eqn1Mtrx_rt_Array_Float_54_33:0, KaTSXR_r_EVN_Nc1Eqn1Mtrx_KaTSXR_r_EVN_Nc1Eqn1Mtrx_rt_Array_Float_54_34:0, KaTSXR_r_EVN_Nc1Eqn1Mtrx_KaTSXR_r_EVN_Nc1Eqn1Mtrx_rt_Array_Float_54_35:0, KaTSXR_r_EVN_Nc1Eqn1Mtrx_KaTSXR_r_EVN_Nc1Eqn1Mtrx_rt_Array_Float_54_36:0, KaTSXR_r_EVN_Nc1Eqn1Mtrx_KaTSXR_r_EVN_Nc1Eqn1Mtrx_rt_Array_Float_54_37:0, KaTSXR_r_EVN_Nc1Eqn1Mtrx_KaTSXR_r_EVN_Nc1Eqn1Mtrx_rt_Array_Float_54_38:0, KaTSXR_r_EVN_Nc1Eqn1Mtrx_KaTSXR_r_EVN_Nc1Eqn1Mtrx_rt_Array_Float_54_39:0, KaTSXR_r_EVN_Nc1Eqn1Mtrx_KaTSXR_r_EVN_Nc1Eqn1Mtrx_rt_Array_Float_54_40:0, KaTSXR_r_EVN_Nc1Eqn1Mtrx_KaTSXR_r_EVN_Nc1Eqn1Mtrx_rt_Array_Float_54_41:0, KaTSXR_r_EVN_Nc1Eqn1Mtrx_KaTSXR_r_EVN_Nc1Eqn1Mtrx_rt_Array_Float_54_42:0, KaTSXR_r_EVN_Nc1Eqn1Mtrx_KaTSXR_r_EVN_Nc1Eqn1Mtrx_rt_Array_Float_54_43:0, KaTSXR_r_EVN_Nc1Eqn1Mtrx_KaTSXR_r_EVN_Nc1Eqn1Mtrx_rt_Array_Float_54_44:0, KaTSXR_r_EVN_Nc1Eqn1Mtrx_KaTSXR_r_EVN_Nc1Eqn1Mtrx_rt_Array_Float_54_45:0, KaTSXR_r_EVN_Nc1Eqn1Mtrx_KaTSXR_r_EVN_Nc1Eqn1Mtrx_rt_Array_Float_54_46:0, KaTSXR_r_EVN_Nc1Eqn1Mtrx_KaTSXR_r_EVN_Nc1Eqn1Mtrx_rt_Array_Float_54_47:0, KaTSXR_r_EVN_Nc1Eqn1Mtrx_KaTSXR_r_EVN_Nc1Eqn1Mtrx_rt_Array_Float_54_48:0, KaTSXR_r_EVN_Nc1Eqn1Mtrx_KaTSXR_r_EVN_Nc1Eqn1Mtrx_rt_Array_Float_54_49:0, KaTSXR_r_EVN_Nc1Eqn1Mtrx_KaTSXR_r_EVN_Nc1Eqn1Mtrx_rt_Array_Float_54_50:0, KaTSXR_r_EVN_Nc1Eqn1Mtrx_KaTSXR_r_EVN_Nc1Eqn1Mtrx_rt_Array_Float_54_51:0, KaTSXR_r_EVN_Nc1Eqn1Mtrx_KaTSXR_r_EVN_Nc1Eqn1Mtrx_rt_Array_Float_54_52:0, KaTSXR_r_EVN_Nc1Eqn1Mtrx_KaTSXR_r_EVN_Nc1Eqn1Mtrx_rt_Array_Float_54_53:0, KaTSXR_r_EVN_Nc1Eqn1Mtrx_KaTSXR_r_EVN_Nc1Eqn1Mtrx_rt_Array_Float_54_54:0], parameter=KaTSXR_r_EVN_Nc1Eqn1Mtrx}, required-interface=KaTSXR_r_EVN_Nc1Eqn1Mtrx
      KaTSXR_r_EVN_Nc1Eqn2Mtrx: parameter-require-com-spec{init-value=KaTSXR_r_EVN_Nc1Eqn2Mtrx_KaTSXR_r_EVN_Nc1Eqn2Mtrx:[KaTSXR_r_EVN_Nc1Eqn2Mtrx_KaTSXR_r_EVN_Nc1Eqn2Mtrx_rt_Array_Float_54_1:0, KaTSXR_r_EVN_Nc1Eqn2Mtrx_KaTSXR_r_EVN_Nc1Eqn2Mtrx_rt_Array_Float_54_2:0, KaTSXR_r_EVN_Nc1Eqn2Mtrx_KaTSXR_r_EVN_Nc1Eqn2Mtrx_rt_Array_Float_54_3:0, KaTSXR_r_EVN_Nc1Eqn2Mtrx_KaTSXR_r_EVN_Nc1Eqn2Mtrx_rt_Array_Float_54_4:0, KaTSXR_r_EVN_Nc1Eqn2Mtrx_KaTSXR_r_EVN_Nc1Eqn2Mtrx_rt_Array_Float_54_5:0, KaTSXR_r_EVN_Nc1Eqn2Mtrx_KaTSXR_r_EVN_Nc1Eqn2Mtrx_rt_Array_Float_54_6:0, KaTSXR_r_EVN_Nc1Eqn2Mtrx_KaTSXR_r_EVN_Nc1Eqn2Mtrx_rt_Array_Float_54_7:0, KaTSXR_r_EVN_Nc1Eqn2Mtrx_KaTSXR_r_EVN_Nc1Eqn2Mtrx_rt_Array_Float_54_8:0, KaTSXR_r_EVN_Nc1Eqn2Mtrx_KaTSXR_r_EVN_Nc1Eqn2Mtrx_rt_Array_Float_54_9:0, KaTSXR_r_EVN_Nc1Eqn2Mtrx_KaTSXR_r_EVN_Nc1Eqn2Mtrx_rt_Array_Float_54_10:0, KaTSXR_r_EVN_Nc1Eqn2Mtrx_KaTSXR_r_EVN_Nc1Eqn2Mtrx_rt_Array_Float_54_11:0, KaTSXR_r_EVN_Nc1Eqn2Mtrx_KaTSXR_r_EVN_Nc1Eqn2Mtrx_rt_Array_Float_54_12:0, KaTSXR_r_EVN_Nc1Eqn2Mtrx_KaTSXR_r_EVN_Nc1Eqn2Mtrx_rt_Array_Float_54_13:0, KaTSXR_r_EVN_Nc1Eqn2Mtrx_KaTSXR_r_EVN_Nc1Eqn2Mtrx_rt_Array_Float_54_14:0, KaTSXR_r_EVN_Nc1Eqn2Mtrx_KaTSXR_r_EVN_Nc1Eqn2Mtrx_rt_Array_Float_54_15:0, KaTSXR_r_EVN_Nc1Eqn2Mtrx_KaTSXR_r_EVN_Nc1Eqn2Mtrx_rt_Array_Float_54_16:0, KaTSXR_r_EVN_Nc1Eqn2Mtrx_KaTSXR_r_EVN_Nc1Eqn2Mtrx_rt_Array_Float_54_17:0, KaTSXR_r_EVN_Nc1Eqn2Mtrx_KaTSXR_r_EVN_Nc1Eqn2Mtrx_rt_Array_Float_54_18:0, KaTSXR_r_EVN_Nc1Eqn2Mtrx_KaTSXR_r_EVN_Nc1Eqn2Mtrx_rt_Array_Float_54_19:0, KaTSXR_r_EVN_Nc1Eqn2Mtrx_KaTSXR_r_EVN_Nc1Eqn2Mtrx_rt_Array_Float_54_20:0, KaTSXR_r_EVN_Nc1Eqn2Mtrx_KaTSXR_r_EVN_Nc1Eqn2Mtrx_rt_Array_Float_54_21:0, KaTSXR_r_EVN_Nc1Eqn2Mtrx_KaTSXR_r_EVN_Nc1Eqn2Mtrx_rt_Array_Float_54_22:0, KaTSXR_r_EVN_Nc1Eqn2Mtrx_KaTSXR_r_EVN_Nc1Eqn2Mtrx_rt_Array_Float_54_23:0, KaTSXR_r_EVN_Nc1Eqn2Mtrx_KaTSXR_r_EVN_Nc1Eqn2Mtrx_rt_Array_Float_54_24:0, KaTSXR_r_EVN_Nc1Eqn2Mtrx_KaTSXR_r_EVN_Nc1Eqn2Mtrx_rt_Array_Float_54_25:0, KaTSXR_r_EVN_Nc1Eqn2Mtrx_KaTSXR_r_EVN_Nc1Eqn2Mtrx_rt_Array_Float_54_26:0, KaTSXR_r_EVN_Nc1Eqn2Mtrx_KaTSXR_r_EVN_Nc1Eqn2Mtrx_rt_Array_Float_54_27:0, KaTSXR_r_EVN_Nc1Eqn2Mtrx_KaTSXR_r_EVN_Nc1Eqn2Mtrx_rt_Array_Float_54_28:0, KaTSXR_r_EVN_Nc1Eqn2Mtrx_KaTSXR_r_EVN_Nc1Eqn2Mtrx_rt_Array_Float_54_29:0, KaTSXR_r_EVN_Nc1Eqn2Mtrx_KaTSXR_r_EVN_Nc1Eqn2Mtrx_rt_Array_Float_54_30:0, KaTSXR_r_EVN_Nc1Eqn2Mtrx_KaTSXR_r_EVN_Nc1Eqn2Mtrx_rt_Array_Float_54_31:0, KaTSXR_r_EVN_Nc1Eqn2Mtrx_KaTSXR_r_EVN_Nc1Eqn2Mtrx_rt_Array_Float_54_32:0, KaTSXR_r_EVN_Nc1Eqn2Mtrx_KaTSXR_r_EVN_Nc1Eqn2Mtrx_rt_Array_Float_54_33:0, KaTSXR_r_EVN_Nc1Eqn2Mtrx_KaTSXR_r_EVN_Nc1Eqn2Mtrx_rt_Array_Float_54_34:0, KaTSXR_r_EVN_Nc1Eqn2Mtrx_KaTSXR_r_EVN_Nc1Eqn2Mtrx_rt_Array_Float_54_35:0, KaTSXR_r_EVN_Nc1Eqn2Mtrx_KaTSXR_r_EVN_Nc1Eqn2Mtrx_rt_Array_Float_54_36:0, KaTSXR_r_EVN_Nc1Eqn2Mtrx_KaTSXR_r_EVN_Nc1Eqn2Mtrx_rt_Array_Float_54_37:0, KaTSXR_r_EVN_Nc1Eqn2Mtrx_KaTSXR_r_EVN_Nc1Eqn2Mtrx_rt_Array_Float_54_38:0, KaTSXR_r_EVN_Nc1Eqn2Mtrx_KaTSXR_r_EVN_Nc1Eqn2Mtrx_rt_Array_Float_54_39:0, KaTSXR_r_EVN_Nc1Eqn2Mtrx_KaTSXR_r_EVN_Nc1Eqn2Mtrx_rt_Array_Float_54_40:0, KaTSXR_r_EVN_Nc1Eqn2Mtrx_KaTSXR_r_EVN_Nc1Eqn2Mtrx_rt_Array_Float_54_41:0, KaTSXR_r_EVN_Nc1Eqn2Mtrx_KaTSXR_r_EVN_Nc1Eqn2Mtrx_rt_Array_Float_54_42:0, KaTSXR_r_EVN_Nc1Eqn2Mtrx_KaTSXR_r_EVN_Nc1Eqn2Mtrx_rt_Array_Float_54_43:0, KaTSXR_r_EVN_Nc1Eqn2Mtrx_KaTSXR_r_EVN_Nc1Eqn2Mtrx_rt_Array_Float_54_44:0, KaTSXR_r_EVN_Nc1Eqn2Mtrx_KaTSXR_r_EVN_Nc1Eqn2Mtrx_rt_Array_Float_54_45:0, KaTSXR_r_EVN_Nc1Eqn2Mtrx_KaTSXR_r_EVN_Nc1Eqn2Mtrx_rt_Array_Float_54_46:0, KaTSXR_r_EVN_Nc1Eqn2Mtrx_KaTSXR_r_EVN_Nc1Eqn2Mtrx_rt_Array_Float_54_47:0, KaTSXR_r_EVN_Nc1Eqn2Mtrx_KaTSXR_r_EVN_Nc1Eqn2Mtrx_rt_Array_Float_54_48:0, KaTSXR_r_EVN_Nc1Eqn2Mtrx_KaTSXR_r_EVN_Nc1Eqn2Mtrx_rt_Array_Float_54_49:0, KaTSXR_r_EVN_Nc1Eqn2Mtrx_KaTSXR_r_EVN_Nc1Eqn2Mtrx_rt_Array_Float_54_50:0, KaTSXR_r_EVN_Nc1Eqn2Mtrx_KaTSXR_r_EVN_Nc1Eqn2Mtrx_rt_Array_Float_54_51:0, KaTSXR_r_EVN_Nc1Eqn2Mtrx_KaTSXR_r_EVN_Nc1Eqn2Mtrx_rt_Array_Float_54_52:0, KaTSXR_r_EVN_Nc1Eqn2Mtrx_KaTSXR_r_EVN_Nc1Eqn2Mtrx_rt_Array_Float_54_53:0, KaTSXR_r_EVN_Nc1Eqn2Mtrx_KaTSXR_r_EVN_Nc1Eqn2Mtrx_rt_Array_Float_54_54:0], parameter=KaTSXR_r_EVN_Nc1Eqn2Mtrx}, required-interface=KaTSXR_r_EVN_Nc1Eqn2Mtrx
      KaTSXR_r_EVN_Nc1TargetEqnMtrx: parameter-require-com-spec{init-value=KaTSXR_r_EVN_Nc1TargetEqnMtrx_KaTSXR_r_EVN_Nc1TargetEqnMtrx:[KaTSXR_r_EVN_Nc1TargetEqnMtrx_KaTSXR_r_EVN_Nc1TargetEqnMtrx_rt_Array_Float_27_1:0, KaTSXR_r_EVN_Nc1TargetEqnMtrx_KaTSXR_r_EVN_Nc1TargetEqnMtrx_rt_Array_Float_27_2:0, KaTSXR_r_EVN_Nc1TargetEqnMtrx_KaTSXR_r_EVN_Nc1TargetEqnMtrx_rt_Array_Float_27_3:0, KaTSXR_r_EVN_Nc1TargetEqnMtrx_KaTSXR_r_EVN_Nc1TargetEqnMtrx_rt_Array_Float_27_4:0, KaTSXR_r_EVN_Nc1TargetEqnMtrx_KaTSXR_r_EVN_Nc1TargetEqnMtrx_rt_Array_Float_27_5:0, KaTSXR_r_EVN_Nc1TargetEqnMtrx_KaTSXR_r_EVN_Nc1TargetEqnMtrx_rt_Array_Float_27_6:0, KaTSXR_r_EVN_Nc1TargetEqnMtrx_KaTSXR_r_EVN_Nc1TargetEqnMtrx_rt_Array_Float_27_7:0, KaTSXR_r_EVN_Nc1TargetEqnMtrx_KaTSXR_r_EVN_Nc1TargetEqnMtrx_rt_Array_Float_27_8:0, KaTSXR_r_EVN_Nc1TargetEqnMtrx_KaTSXR_r_EVN_Nc1TargetEqnMtrx_rt_Array_Float_27_9:0, KaTSXR_r_EVN_Nc1TargetEqnMtrx_KaTSXR_r_EVN_Nc1TargetEqnMtrx_rt_Array_Float_27_10:0, KaTSXR_r_EVN_Nc1TargetEqnMtrx_KaTSXR_r_EVN_Nc1TargetEqnMtrx_rt_Array_Float_27_11:0, KaTSXR_r_EVN_Nc1TargetEqnMtrx_KaTSXR_r_EVN_Nc1TargetEqnMtrx_rt_Array_Float_27_12:0, KaTSXR_r_EVN_Nc1TargetEqnMtrx_KaTSXR_r_EVN_Nc1TargetEqnMtrx_rt_Array_Float_27_13:0, KaTSXR_r_EVN_Nc1TargetEqnMtrx_KaTSXR_r_EVN_Nc1TargetEqnMtrx_rt_Array_Float_27_14:0, KaTSXR_r_EVN_Nc1TargetEqnMtrx_KaTSXR_r_EVN_Nc1TargetEqnMtrx_rt_Array_Float_27_15:0, KaTSXR_r_EVN_Nc1TargetEqnMtrx_KaTSXR_r_EVN_Nc1TargetEqnMtrx_rt_Array_Float_27_16:0, KaTSXR_r_EVN_Nc1TargetEqnMtrx_KaTSXR_r_EVN_Nc1TargetEqnMtrx_rt_Array_Float_27_17:0, KaTSXR_r_EVN_Nc1TargetEqnMtrx_KaTSXR_r_EVN_Nc1TargetEqnMtrx_rt_Array_Float_27_18:0, KaTSXR_r_EVN_Nc1TargetEqnMtrx_KaTSXR_r_EVN_Nc1TargetEqnMtrx_rt_Array_Float_27_19:0, KaTSXR_r_EVN_Nc1TargetEqnMtrx_KaTSXR_r_EVN_Nc1TargetEqnMtrx_rt_Array_Float_27_20:0, KaTSXR_r_EVN_Nc1TargetEqnMtrx_KaTSXR_r_EVN_Nc1TargetEqnMtrx_rt_Array_Float_27_21:0, KaTSXR_r_EVN_Nc1TargetEqnMtrx_KaTSXR_r_EVN_Nc1TargetEqnMtrx_rt_Array_Float_27_22:0, KaTSXR_r_EVN_Nc1TargetEqnMtrx_KaTSXR_r_EVN_Nc1TargetEqnMtrx_rt_Array_Float_27_23:0, KaTSXR_r_EVN_Nc1TargetEqnMtrx_KaTSXR_r_EVN_Nc1TargetEqnMtrx_rt_Array_Float_27_24:0, KaTSXR_r_EVN_Nc1TargetEqnMtrx_KaTSXR_r_EVN_Nc1TargetEqnMtrx_rt_Array_Float_27_25:0, KaTSXR_r_EVN_Nc1TargetEqnMtrx_KaTSXR_r_EVN_Nc1TargetEqnMtrx_rt_Array_Float_27_26:0, KaTSXR_r_EVN_Nc1TargetEqnMtrx_KaTSXR_r_EVN_Nc1TargetEqnMtrx_rt_Array_Float_27_27:0], parameter=KaTSXR_r_EVN_Nc1TargetEqnMtrx}, required-interface=KaTSXR_r_EVN_Nc1TargetEqnMtrx
      KaTSXR_r_EVN_NcCalcEqnMtrx: parameter-require-com-spec{init-value=KaTSXR_r_EVN_NcCalcEqnMtrx_KaTSXR_r_EVN_NcCalcEqnMtrx:[KaTSXR_r_EVN_NcCalcEqnMtrx_KaTSXR_r_EVN_NcCalcEqnMtrx_rt_Array_Float_27_1:0, KaTSXR_r_EVN_NcCalcEqnMtrx_KaTSXR_r_EVN_NcCalcEqnMtrx_rt_Array_Float_27_2:0, KaTSXR_r_EVN_NcCalcEqnMtrx_KaTSXR_r_EVN_NcCalcEqnMtrx_rt_Array_Float_27_3:0, KaTSXR_r_EVN_NcCalcEqnMtrx_KaTSXR_r_EVN_NcCalcEqnMtrx_rt_Array_Float_27_4:0, KaTSXR_r_EVN_NcCalcEqnMtrx_KaTSXR_r_EVN_NcCalcEqnMtrx_rt_Array_Float_27_5:0, KaTSXR_r_EVN_NcCalcEqnMtrx_KaTSXR_r_EVN_NcCalcEqnMtrx_rt_Array_Float_27_6:0, KaTSXR_r_EVN_NcCalcEqnMtrx_KaTSXR_r_EVN_NcCalcEqnMtrx_rt_Array_Float_27_7:0, KaTSXR_r_EVN_NcCalcEqnMtrx_KaTSXR_r_EVN_NcCalcEqnMtrx_rt_Array_Float_27_8:0, KaTSXR_r_EVN_NcCalcEqnMtrx_KaTSXR_r_EVN_NcCalcEqnMtrx_rt_Array_Float_27_9:0, KaTSXR_r_EVN_NcCalcEqnMtrx_KaTSXR_r_EVN_NcCalcEqnMtrx_rt_Array_Float_27_10:0, KaTSXR_r_EVN_NcCalcEqnMtrx_KaTSXR_r_EVN_NcCalcEqnMtrx_rt_Array_Float_27_11:0, KaTSXR_r_EVN_NcCalcEqnMtrx_KaTSXR_r_EVN_NcCalcEqnMtrx_rt_Array_Float_27_12:0, KaTSXR_r_EVN_NcCalcEqnMtrx_KaTSXR_r_EVN_NcCalcEqnMtrx_rt_Array_Float_27_13:0, KaTSXR_r_EVN_NcCalcEqnMtrx_KaTSXR_r_EVN_NcCalcEqnMtrx_rt_Array_Float_27_14:0, KaTSXR_r_EVN_NcCalcEqnMtrx_KaTSXR_r_EVN_NcCalcEqnMtrx_rt_Array_Float_27_15:0, KaTSXR_r_EVN_NcCalcEqnMtrx_KaTSXR_r_EVN_NcCalcEqnMtrx_rt_Array_Float_27_16:0, KaTSXR_r_EVN_NcCalcEqnMtrx_KaTSXR_r_EVN_NcCalcEqnMtrx_rt_Array_Float_27_17:0, KaTSXR_r_EVN_NcCalcEqnMtrx_KaTSXR_r_EVN_NcCalcEqnMtrx_rt_Array_Float_27_18:0, KaTSXR_r_EVN_NcCalcEqnMtrx_KaTSXR_r_EVN_NcCalcEqnMtrx_rt_Array_Float_27_19:0, KaTSXR_r_EVN_NcCalcEqnMtrx_KaTSXR_r_EVN_NcCalcEqnMtrx_rt_Array_Float_27_20:0, KaTSXR_r_EVN_NcCalcEqnMtrx_KaTSXR_r_EVN_NcCalcEqnMtrx_rt_Array_Float_27_21:0, KaTSXR_r_EVN_NcCalcEqnMtrx_KaTSXR_r_EVN_NcCalcEqnMtrx_rt_Array_Float_27_22:0, KaTSXR_r_EVN_NcCalcEqnMtrx_KaTSXR_r_EVN_NcCalcEqnMtrx_rt_Array_Float_27_23:0, KaTSXR_r_EVN_NcCalcEqnMtrx_KaTSXR_r_EVN_NcCalcEqnMtrx_rt_Array_Float_27_24:0, KaTSXR_r_EVN_NcCalcEqnMtrx_KaTSXR_r_EVN_NcCalcEqnMtrx_rt_Array_Float_27_25:0, KaTSXR_r_EVN_NcCalcEqnMtrx_KaTSXR_r_EVN_NcCalcEqnMtrx_rt_Array_Float_27_26:0, KaTSXR_r_EVN_NcCalcEqnMtrx_KaTSXR_r_EVN_NcCalcEqnMtrx_rt_Array_Float_27_27:0], parameter=KaTSXR_r_EVN_NcCalcEqnMtrx}, required-interface=KaTSXR_r_EVN_NcCalcEqnMtrx
      KaTSXR_r_EVN_NoEqn1Mtrx: parameter-require-com-spec{init-value=KaTSXR_r_EVN_NoEqn1Mtrx_KaTSXR_r_EVN_NoEqn1Mtrx:[KaTSXR_r_EVN_NoEqn1Mtrx_KaTSXR_r_EVN_NoEqn1Mtrx_rt_Array_Float_54_1:0, KaTSXR_r_EVN_NoEqn1Mtrx_KaTSXR_r_EVN_NoEqn1Mtrx_rt_Array_Float_54_2:0, KaTSXR_r_EVN_NoEqn1Mtrx_KaTSXR_r_EVN_NoEqn1Mtrx_rt_Array_Float_54_3:0, KaTSXR_r_EVN_NoEqn1Mtrx_KaTSXR_r_EVN_NoEqn1Mtrx_rt_Array_Float_54_4:0, KaTSXR_r_EVN_NoEqn1Mtrx_KaTSXR_r_EVN_NoEqn1Mtrx_rt_Array_Float_54_5:0, KaTSXR_r_EVN_NoEqn1Mtrx_KaTSXR_r_EVN_NoEqn1Mtrx_rt_Array_Float_54_6:0, KaTSXR_r_EVN_NoEqn1Mtrx_KaTSXR_r_EVN_NoEqn1Mtrx_rt_Array_Float_54_7:0, KaTSXR_r_EVN_NoEqn1Mtrx_KaTSXR_r_EVN_NoEqn1Mtrx_rt_Array_Float_54_8:0, KaTSXR_r_EVN_NoEqn1Mtrx_KaTSXR_r_EVN_NoEqn1Mtrx_rt_Array_Float_54_9:0, KaTSXR_r_EVN_NoEqn1Mtrx_KaTSXR_r_EVN_NoEqn1Mtrx_rt_Array_Float_54_10:0, KaTSXR_r_EVN_NoEqn1Mtrx_KaTSXR_r_EVN_NoEqn1Mtrx_rt_Array_Float_54_11:0, KaTSXR_r_EVN_NoEqn1Mtrx_KaTSXR_r_EVN_NoEqn1Mtrx_rt_Array_Float_54_12:0, KaTSXR_r_EVN_NoEqn1Mtrx_KaTSXR_r_EVN_NoEqn1Mtrx_rt_Array_Float_54_13:0, KaTSXR_r_EVN_NoEqn1Mtrx_KaTSXR_r_EVN_NoEqn1Mtrx_rt_Array_Float_54_14:0, KaTSXR_r_EVN_NoEqn1Mtrx_KaTSXR_r_EVN_NoEqn1Mtrx_rt_Array_Float_54_15:0, KaTSXR_r_EVN_NoEqn1Mtrx_KaTSXR_r_EVN_NoEqn1Mtrx_rt_Array_Float_54_16:0, KaTSXR_r_EVN_NoEqn1Mtrx_KaTSXR_r_EVN_NoEqn1Mtrx_rt_Array_Float_54_17:0, KaTSXR_r_EVN_NoEqn1Mtrx_KaTSXR_r_EVN_NoEqn1Mtrx_rt_Array_Float_54_18:0, KaTSXR_r_EVN_NoEqn1Mtrx_KaTSXR_r_EVN_NoEqn1Mtrx_rt_Array_Float_54_19:0, KaTSXR_r_EVN_NoEqn1Mtrx_KaTSXR_r_EVN_NoEqn1Mtrx_rt_Array_Float_54_20:0, KaTSXR_r_EVN_NoEqn1Mtrx_KaTSXR_r_EVN_NoEqn1Mtrx_rt_Array_Float_54_21:0, KaTSXR_r_EVN_NoEqn1Mtrx_KaTSXR_r_EVN_NoEqn1Mtrx_rt_Array_Float_54_22:0, KaTSXR_r_EVN_NoEqn1Mtrx_KaTSXR_r_EVN_NoEqn1Mtrx_rt_Array_Float_54_23:0, KaTSXR_r_EVN_NoEqn1Mtrx_KaTSXR_r_EVN_NoEqn1Mtrx_rt_Array_Float_54_24:0, KaTSXR_r_EVN_NoEqn1Mtrx_KaTSXR_r_EVN_NoEqn1Mtrx_rt_Array_Float_54_25:0, KaTSXR_r_EVN_NoEqn1Mtrx_KaTSXR_r_EVN_NoEqn1Mtrx_rt_Array_Float_54_26:0, KaTSXR_r_EVN_NoEqn1Mtrx_KaTSXR_r_EVN_NoEqn1Mtrx_rt_Array_Float_54_27:0, KaTSXR_r_EVN_NoEqn1Mtrx_KaTSXR_r_EVN_NoEqn1Mtrx_rt_Array_Float_54_28:0, KaTSXR_r_EVN_NoEqn1Mtrx_KaTSXR_r_EVN_NoEqn1Mtrx_rt_Array_Float_54_29:0, KaTSXR_r_EVN_NoEqn1Mtrx_KaTSXR_r_EVN_NoEqn1Mtrx_rt_Array_Float_54_30:0, KaTSXR_r_EVN_NoEqn1Mtrx_KaTSXR_r_EVN_NoEqn1Mtrx_rt_Array_Float_54_31:0, KaTSXR_r_EVN_NoEqn1Mtrx_KaTSXR_r_EVN_NoEqn1Mtrx_rt_Array_Float_54_32:0, KaTSXR_r_EVN_NoEqn1Mtrx_KaTSXR_r_EVN_NoEqn1Mtrx_rt_Array_Float_54_33:0, KaTSXR_r_EVN_NoEqn1Mtrx_KaTSXR_r_EVN_NoEqn1Mtrx_rt_Array_Float_54_34:0, KaTSXR_r_EVN_NoEqn1Mtrx_KaTSXR_r_EVN_NoEqn1Mtrx_rt_Array_Float_54_35:0, KaTSXR_r_EVN_NoEqn1Mtrx_KaTSXR_r_EVN_NoEqn1Mtrx_rt_Array_Float_54_36:0, KaTSXR_r_EVN_NoEqn1Mtrx_KaTSXR_r_EVN_NoEqn1Mtrx_rt_Array_Float_54_37:0, KaTSXR_r_EVN_NoEqn1Mtrx_KaTSXR_r_EVN_NoEqn1Mtrx_rt_Array_Float_54_38:0, KaTSXR_r_EVN_NoEqn1Mtrx_KaTSXR_r_EVN_NoEqn1Mtrx_rt_Array_Float_54_39:0, KaTSXR_r_EVN_NoEqn1Mtrx_KaTSXR_r_EVN_NoEqn1Mtrx_rt_Array_Float_54_40:0, KaTSXR_r_EVN_NoEqn1Mtrx_KaTSXR_r_EVN_NoEqn1Mtrx_rt_Array_Float_54_41:0, KaTSXR_r_EVN_NoEqn1Mtrx_KaTSXR_r_EVN_NoEqn1Mtrx_rt_Array_Float_54_42:0, KaTSXR_r_EVN_NoEqn1Mtrx_KaTSXR_r_EVN_NoEqn1Mtrx_rt_Array_Float_54_43:0, KaTSXR_r_EVN_NoEqn1Mtrx_KaTSXR_r_EVN_NoEqn1Mtrx_rt_Array_Float_54_44:0, KaTSXR_r_EVN_NoEqn1Mtrx_KaTSXR_r_EVN_NoEqn1Mtrx_rt_Array_Float_54_45:0, KaTSXR_r_EVN_NoEqn1Mtrx_KaTSXR_r_EVN_NoEqn1Mtrx_rt_Array_Float_54_46:0, KaTSXR_r_EVN_NoEqn1Mtrx_KaTSXR_r_EVN_NoEqn1Mtrx_rt_Array_Float_54_47:0, KaTSXR_r_EVN_NoEqn1Mtrx_KaTSXR_r_EVN_NoEqn1Mtrx_rt_Array_Float_54_48:0, KaTSXR_r_EVN_NoEqn1Mtrx_KaTSXR_r_EVN_NoEqn1Mtrx_rt_Array_Float_54_49:0, KaTSXR_r_EVN_NoEqn1Mtrx_KaTSXR_r_EVN_NoEqn1Mtrx_rt_Array_Float_54_50:0, KaTSXR_r_EVN_NoEqn1Mtrx_KaTSXR_r_EVN_NoEqn1Mtrx_rt_Array_Float_54_51:0, KaTSXR_r_EVN_NoEqn1Mtrx_KaTSXR_r_EVN_NoEqn1Mtrx_rt_Array_Float_54_52:0, KaTSXR_r_EVN_NoEqn1Mtrx_KaTSXR_r_EVN_NoEqn1Mtrx_rt_Array_Float_54_53:0, KaTSXR_r_EVN_NoEqn1Mtrx_KaTSXR_r_EVN_NoEqn1Mtrx_rt_Array_Float_54_54:0], parameter=KaTSXR_r_EVN_NoEqn1Mtrx}, required-interface=KaTSXR_r_EVN_NoEqn1Mtrx
      KaTSXR_r_EVN_NoEqn2Mtrx: parameter-require-com-spec{init-value=KaTSXR_r_EVN_NoEqn2Mtrx_KaTSXR_r_EVN_NoEqn2Mtrx:[KaTSXR_r_EVN_NoEqn2Mtrx_KaTSXR_r_EVN_NoEqn2Mtrx_rt_Array_Float_54_1:0, KaTSXR_r_EVN_NoEqn2Mtrx_KaTSXR_r_EVN_NoEqn2Mtrx_rt_Array_Float_54_2:0, KaTSXR_r_EVN_NoEqn2Mtrx_KaTSXR_r_EVN_NoEqn2Mtrx_rt_Array_Float_54_3:0, KaTSXR_r_EVN_NoEqn2Mtrx_KaTSXR_r_EVN_NoEqn2Mtrx_rt_Array_Float_54_4:0, KaTSXR_r_EVN_NoEqn2Mtrx_KaTSXR_r_EVN_NoEqn2Mtrx_rt_Array_Float_54_5:0, KaTSXR_r_EVN_NoEqn2Mtrx_KaTSXR_r_EVN_NoEqn2Mtrx_rt_Array_Float_54_6:0, KaTSXR_r_EVN_NoEqn2Mtrx_KaTSXR_r_EVN_NoEqn2Mtrx_rt_Array_Float_54_7:0, KaTSXR_r_EVN_NoEqn2Mtrx_KaTSXR_r_EVN_NoEqn2Mtrx_rt_Array_Float_54_8:0, KaTSXR_r_EVN_NoEqn2Mtrx_KaTSXR_r_EVN_NoEqn2Mtrx_rt_Array_Float_54_9:0, KaTSXR_r_EVN_NoEqn2Mtrx_KaTSXR_r_EVN_NoEqn2Mtrx_rt_Array_Float_54_10:0, KaTSXR_r_EVN_NoEqn2Mtrx_KaTSXR_r_EVN_NoEqn2Mtrx_rt_Array_Float_54_11:0, KaTSXR_r_EVN_NoEqn2Mtrx_KaTSXR_r_EVN_NoEqn2Mtrx_rt_Array_Float_54_12:0, KaTSXR_r_EVN_NoEqn2Mtrx_KaTSXR_r_EVN_NoEqn2Mtrx_rt_Array_Float_54_13:0, KaTSXR_r_EVN_NoEqn2Mtrx_KaTSXR_r_EVN_NoEqn2Mtrx_rt_Array_Float_54_14:0, KaTSXR_r_EVN_NoEqn2Mtrx_KaTSXR_r_EVN_NoEqn2Mtrx_rt_Array_Float_54_15:0, KaTSXR_r_EVN_NoEqn2Mtrx_KaTSXR_r_EVN_NoEqn2Mtrx_rt_Array_Float_54_16:0, KaTSXR_r_EVN_NoEqn2Mtrx_KaTSXR_r_EVN_NoEqn2Mtrx_rt_Array_Float_54_17:0, KaTSXR_r_EVN_NoEqn2Mtrx_KaTSXR_r_EVN_NoEqn2Mtrx_rt_Array_Float_54_18:0, KaTSXR_r_EVN_NoEqn2Mtrx_KaTSXR_r_EVN_NoEqn2Mtrx_rt_Array_Float_54_19:0, KaTSXR_r_EVN_NoEqn2Mtrx_KaTSXR_r_EVN_NoEqn2Mtrx_rt_Array_Float_54_20:0, KaTSXR_r_EVN_NoEqn2Mtrx_KaTSXR_r_EVN_NoEqn2Mtrx_rt_Array_Float_54_21:0, KaTSXR_r_EVN_NoEqn2Mtrx_KaTSXR_r_EVN_NoEqn2Mtrx_rt_Array_Float_54_22:0, KaTSXR_r_EVN_NoEqn2Mtrx_KaTSXR_r_EVN_NoEqn2Mtrx_rt_Array_Float_54_23:0, KaTSXR_r_EVN_NoEqn2Mtrx_KaTSXR_r_EVN_NoEqn2Mtrx_rt_Array_Float_54_24:0, KaTSXR_r_EVN_NoEqn2Mtrx_KaTSXR_r_EVN_NoEqn2Mtrx_rt_Array_Float_54_25:0, KaTSXR_r_EVN_NoEqn2Mtrx_KaTSXR_r_EVN_NoEqn2Mtrx_rt_Array_Float_54_26:0, KaTSXR_r_EVN_NoEqn2Mtrx_KaTSXR_r_EVN_NoEqn2Mtrx_rt_Array_Float_54_27:0, KaTSXR_r_EVN_NoEqn2Mtrx_KaTSXR_r_EVN_NoEqn2Mtrx_rt_Array_Float_54_28:0, KaTSXR_r_EVN_NoEqn2Mtrx_KaTSXR_r_EVN_NoEqn2Mtrx_rt_Array_Float_54_29:0, KaTSXR_r_EVN_NoEqn2Mtrx_KaTSXR_r_EVN_NoEqn2Mtrx_rt_Array_Float_54_30:0, KaTSXR_r_EVN_NoEqn2Mtrx_KaTSXR_r_EVN_NoEqn2Mtrx_rt_Array_Float_54_31:0, KaTSXR_r_EVN_NoEqn2Mtrx_KaTSXR_r_EVN_NoEqn2Mtrx_rt_Array_Float_54_32:0, KaTSXR_r_EVN_NoEqn2Mtrx_KaTSXR_r_EVN_NoEqn2Mtrx_rt_Array_Float_54_33:0, KaTSXR_r_EVN_NoEqn2Mtrx_KaTSXR_r_EVN_NoEqn2Mtrx_rt_Array_Float_54_34:0, KaTSXR_r_EVN_NoEqn2Mtrx_KaTSXR_r_EVN_NoEqn2Mtrx_rt_Array_Float_54_35:0, KaTSXR_r_EVN_NoEqn2Mtrx_KaTSXR_r_EVN_NoEqn2Mtrx_rt_Array_Float_54_36:0, KaTSXR_r_EVN_NoEqn2Mtrx_KaTSXR_r_EVN_NoEqn2Mtrx_rt_Array_Float_54_37:0, KaTSXR_r_EVN_NoEqn2Mtrx_KaTSXR_r_EVN_NoEqn2Mtrx_rt_Array_Float_54_38:0, KaTSXR_r_EVN_NoEqn2Mtrx_KaTSXR_r_EVN_NoEqn2Mtrx_rt_Array_Float_54_39:0, KaTSXR_r_EVN_NoEqn2Mtrx_KaTSXR_r_EVN_NoEqn2Mtrx_rt_Array_Float_54_40:0, KaTSXR_r_EVN_NoEqn2Mtrx_KaTSXR_r_EVN_NoEqn2Mtrx_rt_Array_Float_54_41:0, KaTSXR_r_EVN_NoEqn2Mtrx_KaTSXR_r_EVN_NoEqn2Mtrx_rt_Array_Float_54_42:0, KaTSXR_r_EVN_NoEqn2Mtrx_KaTSXR_r_EVN_NoEqn2Mtrx_rt_Array_Float_54_43:0, KaTSXR_r_EVN_NoEqn2Mtrx_KaTSXR_r_EVN_NoEqn2Mtrx_rt_Array_Float_54_44:0, KaTSXR_r_EVN_NoEqn2Mtrx_KaTSXR_r_EVN_NoEqn2Mtrx_rt_Array_Float_54_45:0, KaTSXR_r_EVN_NoEqn2Mtrx_KaTSXR_r_EVN_NoEqn2Mtrx_rt_Array_Float_54_46:0, KaTSXR_r_EVN_NoEqn2Mtrx_KaTSXR_r_EVN_NoEqn2Mtrx_rt_Array_Float_54_47:0, KaTSXR_r_EVN_NoEqn2Mtrx_KaTSXR_r_EVN_NoEqn2Mtrx_rt_Array_Float_54_48:0, KaTSXR_r_EVN_NoEqn2Mtrx_KaTSXR_r_EVN_NoEqn2Mtrx_rt_Array_Float_54_49:0, KaTSXR_r_EVN_NoEqn2Mtrx_KaTSXR_r_EVN_NoEqn2Mtrx_rt_Array_Float_54_50:0, KaTSXR_r_EVN_NoEqn2Mtrx_KaTSXR_r_EVN_NoEqn2Mtrx_rt_Array_Float_54_51:0, KaTSXR_r_EVN_NoEqn2Mtrx_KaTSXR_r_EVN_NoEqn2Mtrx_rt_Array_Float_54_52:0, KaTSXR_r_EVN_NoEqn2Mtrx_KaTSXR_r_EVN_NoEqn2Mtrx_rt_Array_Float_54_53:0, KaTSXR_r_EVN_NoEqn2Mtrx_KaTSXR_r_EVN_NoEqn2Mtrx_rt_Array_Float_54_54:0], parameter=KaTSXR_r_EVN_NoEqn2Mtrx}, required-interface=KaTSXR_r_EVN_NoEqn2Mtrx
      KaTSXR_r_EVN_NtiEqn1Mtrx: parameter-require-com-spec{init-value=KaTSXR_r_EVN_NtiEqn1Mtrx_KaTSXR_r_EVN_NtiEqn1Mtrx:[KaTSXR_r_EVN_NtiEqn1Mtrx_KaTSXR_r_EVN_NtiEqn1Mtrx_rt_Array_Float_54_1:0, KaTSXR_r_EVN_NtiEqn1Mtrx_KaTSXR_r_EVN_NtiEqn1Mtrx_rt_Array_Float_54_2:0, KaTSXR_r_EVN_NtiEqn1Mtrx_KaTSXR_r_EVN_NtiEqn1Mtrx_rt_Array_Float_54_3:0, KaTSXR_r_EVN_NtiEqn1Mtrx_KaTSXR_r_EVN_NtiEqn1Mtrx_rt_Array_Float_54_4:0, KaTSXR_r_EVN_NtiEqn1Mtrx_KaTSXR_r_EVN_NtiEqn1Mtrx_rt_Array_Float_54_5:0, KaTSXR_r_EVN_NtiEqn1Mtrx_KaTSXR_r_EVN_NtiEqn1Mtrx_rt_Array_Float_54_6:0, KaTSXR_r_EVN_NtiEqn1Mtrx_KaTSXR_r_EVN_NtiEqn1Mtrx_rt_Array_Float_54_7:0, KaTSXR_r_EVN_NtiEqn1Mtrx_KaTSXR_r_EVN_NtiEqn1Mtrx_rt_Array_Float_54_8:0, KaTSXR_r_EVN_NtiEqn1Mtrx_KaTSXR_r_EVN_NtiEqn1Mtrx_rt_Array_Float_54_9:0, KaTSXR_r_EVN_NtiEqn1Mtrx_KaTSXR_r_EVN_NtiEqn1Mtrx_rt_Array_Float_54_10:0, KaTSXR_r_EVN_NtiEqn1Mtrx_KaTSXR_r_EVN_NtiEqn1Mtrx_rt_Array_Float_54_11:0, KaTSXR_r_EVN_NtiEqn1Mtrx_KaTSXR_r_EVN_NtiEqn1Mtrx_rt_Array_Float_54_12:0, KaTSXR_r_EVN_NtiEqn1Mtrx_KaTSXR_r_EVN_NtiEqn1Mtrx_rt_Array_Float_54_13:0, KaTSXR_r_EVN_NtiEqn1Mtrx_KaTSXR_r_EVN_NtiEqn1Mtrx_rt_Array_Float_54_14:0, KaTSXR_r_EVN_NtiEqn1Mtrx_KaTSXR_r_EVN_NtiEqn1Mtrx_rt_Array_Float_54_15:0, KaTSXR_r_EVN_NtiEqn1Mtrx_KaTSXR_r_EVN_NtiEqn1Mtrx_rt_Array_Float_54_16:0, KaTSXR_r_EVN_NtiEqn1Mtrx_KaTSXR_r_EVN_NtiEqn1Mtrx_rt_Array_Float_54_17:0, KaTSXR_r_EVN_NtiEqn1Mtrx_KaTSXR_r_EVN_NtiEqn1Mtrx_rt_Array_Float_54_18:0, KaTSXR_r_EVN_NtiEqn1Mtrx_KaTSXR_r_EVN_NtiEqn1Mtrx_rt_Array_Float_54_19:0, KaTSXR_r_EVN_NtiEqn1Mtrx_KaTSXR_r_EVN_NtiEqn1Mtrx_rt_Array_Float_54_20:0, KaTSXR_r_EVN_NtiEqn1Mtrx_KaTSXR_r_EVN_NtiEqn1Mtrx_rt_Array_Float_54_21:0, KaTSXR_r_EVN_NtiEqn1Mtrx_KaTSXR_r_EVN_NtiEqn1Mtrx_rt_Array_Float_54_22:0, KaTSXR_r_EVN_NtiEqn1Mtrx_KaTSXR_r_EVN_NtiEqn1Mtrx_rt_Array_Float_54_23:0, KaTSXR_r_EVN_NtiEqn1Mtrx_KaTSXR_r_EVN_NtiEqn1Mtrx_rt_Array_Float_54_24:0, KaTSXR_r_EVN_NtiEqn1Mtrx_KaTSXR_r_EVN_NtiEqn1Mtrx_rt_Array_Float_54_25:0, KaTSXR_r_EVN_NtiEqn1Mtrx_KaTSXR_r_EVN_NtiEqn1Mtrx_rt_Array_Float_54_26:0, KaTSXR_r_EVN_NtiEqn1Mtrx_KaTSXR_r_EVN_NtiEqn1Mtrx_rt_Array_Float_54_27:0, KaTSXR_r_EVN_NtiEqn1Mtrx_KaTSXR_r_EVN_NtiEqn1Mtrx_rt_Array_Float_54_28:0, KaTSXR_r_EVN_NtiEqn1Mtrx_KaTSXR_r_EVN_NtiEqn1Mtrx_rt_Array_Float_54_29:0, KaTSXR_r_EVN_NtiEqn1Mtrx_KaTSXR_r_EVN_NtiEqn1Mtrx_rt_Array_Float_54_30:0, KaTSXR_r_EVN_NtiEqn1Mtrx_KaTSXR_r_EVN_NtiEqn1Mtrx_rt_Array_Float_54_31:0, KaTSXR_r_EVN_NtiEqn1Mtrx_KaTSXR_r_EVN_NtiEqn1Mtrx_rt_Array_Float_54_32:0, KaTSXR_r_EVN_NtiEqn1Mtrx_KaTSXR_r_EVN_NtiEqn1Mtrx_rt_Array_Float_54_33:0, KaTSXR_r_EVN_NtiEqn1Mtrx_KaTSXR_r_EVN_NtiEqn1Mtrx_rt_Array_Float_54_34:0, KaTSXR_r_EVN_NtiEqn1Mtrx_KaTSXR_r_EVN_NtiEqn1Mtrx_rt_Array_Float_54_35:0, KaTSXR_r_EVN_NtiEqn1Mtrx_KaTSXR_r_EVN_NtiEqn1Mtrx_rt_Array_Float_54_36:0, KaTSXR_r_EVN_NtiEqn1Mtrx_KaTSXR_r_EVN_NtiEqn1Mtrx_rt_Array_Float_54_37:0, KaTSXR_r_EVN_NtiEqn1Mtrx_KaTSXR_r_EVN_NtiEqn1Mtrx_rt_Array_Float_54_38:0, KaTSXR_r_EVN_NtiEqn1Mtrx_KaTSXR_r_EVN_NtiEqn1Mtrx_rt_Array_Float_54_39:0, KaTSXR_r_EVN_NtiEqn1Mtrx_KaTSXR_r_EVN_NtiEqn1Mtrx_rt_Array_Float_54_40:0, KaTSXR_r_EVN_NtiEqn1Mtrx_KaTSXR_r_EVN_NtiEqn1Mtrx_rt_Array_Float_54_41:0, KaTSXR_r_EVN_NtiEqn1Mtrx_KaTSXR_r_EVN_NtiEqn1Mtrx_rt_Array_Float_54_42:0, KaTSXR_r_EVN_NtiEqn1Mtrx_KaTSXR_r_EVN_NtiEqn1Mtrx_rt_Array_Float_54_43:0, KaTSXR_r_EVN_NtiEqn1Mtrx_KaTSXR_r_EVN_NtiEqn1Mtrx_rt_Array_Float_54_44:0, KaTSXR_r_EVN_NtiEqn1Mtrx_KaTSXR_r_EVN_NtiEqn1Mtrx_rt_Array_Float_54_45:0, KaTSXR_r_EVN_NtiEqn1Mtrx_KaTSXR_r_EVN_NtiEqn1Mtrx_rt_Array_Float_54_46:0, KaTSXR_r_EVN_NtiEqn1Mtrx_KaTSXR_r_EVN_NtiEqn1Mtrx_rt_Array_Float_54_47:0, KaTSXR_r_EVN_NtiEqn1Mtrx_KaTSXR_r_EVN_NtiEqn1Mtrx_rt_Array_Float_54_48:0, KaTSXR_r_EVN_NtiEqn1Mtrx_KaTSXR_r_EVN_NtiEqn1Mtrx_rt_Array_Float_54_49:0, KaTSXR_r_EVN_NtiEqn1Mtrx_KaTSXR_r_EVN_NtiEqn1Mtrx_rt_Array_Float_54_50:0, KaTSXR_r_EVN_NtiEqn1Mtrx_KaTSXR_r_EVN_NtiEqn1Mtrx_rt_Array_Float_54_51:0, KaTSXR_r_EVN_NtiEqn1Mtrx_KaTSXR_r_EVN_NtiEqn1Mtrx_rt_Array_Float_54_52:0, KaTSXR_r_EVN_NtiEqn1Mtrx_KaTSXR_r_EVN_NtiEqn1Mtrx_rt_Array_Float_54_53:0, KaTSXR_r_EVN_NtiEqn1Mtrx_KaTSXR_r_EVN_NtiEqn1Mtrx_rt_Array_Float_54_54:0], parameter=KaTSXR_r_EVN_NtiEqn1Mtrx}, required-interface=KaTSXR_r_EVN_NtiEqn1Mtrx
      KaTSXR_r_EVN_NtiEqn2Mtrx: parameter-require-com-spec{init-value=KaTSXR_r_EVN_NtiEqn2Mtrx_KaTSXR_r_EVN_NtiEqn2Mtrx:[KaTSXR_r_EVN_NtiEqn2Mtrx_KaTSXR_r_EVN_NtiEqn2Mtrx_rt_Array_Float_54_1:0, KaTSXR_r_EVN_NtiEqn2Mtrx_KaTSXR_r_EVN_NtiEqn2Mtrx_rt_Array_Float_54_2:0, KaTSXR_r_EVN_NtiEqn2Mtrx_KaTSXR_r_EVN_NtiEqn2Mtrx_rt_Array_Float_54_3:0, KaTSXR_r_EVN_NtiEqn2Mtrx_KaTSXR_r_EVN_NtiEqn2Mtrx_rt_Array_Float_54_4:0, KaTSXR_r_EVN_NtiEqn2Mtrx_KaTSXR_r_EVN_NtiEqn2Mtrx_rt_Array_Float_54_5:0, KaTSXR_r_EVN_NtiEqn2Mtrx_KaTSXR_r_EVN_NtiEqn2Mtrx_rt_Array_Float_54_6:0, KaTSXR_r_EVN_NtiEqn2Mtrx_KaTSXR_r_EVN_NtiEqn2Mtrx_rt_Array_Float_54_7:0, KaTSXR_r_EVN_NtiEqn2Mtrx_KaTSXR_r_EVN_NtiEqn2Mtrx_rt_Array_Float_54_8:0, KaTSXR_r_EVN_NtiEqn2Mtrx_KaTSXR_r_EVN_NtiEqn2Mtrx_rt_Array_Float_54_9:0, KaTSXR_r_EVN_NtiEqn2Mtrx_KaTSXR_r_EVN_NtiEqn2Mtrx_rt_Array_Float_54_10:0, KaTSXR_r_EVN_NtiEqn2Mtrx_KaTSXR_r_EVN_NtiEqn2Mtrx_rt_Array_Float_54_11:0, KaTSXR_r_EVN_NtiEqn2Mtrx_KaTSXR_r_EVN_NtiEqn2Mtrx_rt_Array_Float_54_12:0, KaTSXR_r_EVN_NtiEqn2Mtrx_KaTSXR_r_EVN_NtiEqn2Mtrx_rt_Array_Float_54_13:0, KaTSXR_r_EVN_NtiEqn2Mtrx_KaTSXR_r_EVN_NtiEqn2Mtrx_rt_Array_Float_54_14:0, KaTSXR_r_EVN_NtiEqn2Mtrx_KaTSXR_r_EVN_NtiEqn2Mtrx_rt_Array_Float_54_15:0, KaTSXR_r_EVN_NtiEqn2Mtrx_KaTSXR_r_EVN_NtiEqn2Mtrx_rt_Array_Float_54_16:0, KaTSXR_r_EVN_NtiEqn2Mtrx_KaTSXR_r_EVN_NtiEqn2Mtrx_rt_Array_Float_54_17:0, KaTSXR_r_EVN_NtiEqn2Mtrx_KaTSXR_r_EVN_NtiEqn2Mtrx_rt_Array_Float_54_18:0, KaTSXR_r_EVN_NtiEqn2Mtrx_KaTSXR_r_EVN_NtiEqn2Mtrx_rt_Array_Float_54_19:0, KaTSXR_r_EVN_NtiEqn2Mtrx_KaTSXR_r_EVN_NtiEqn2Mtrx_rt_Array_Float_54_20:0, KaTSXR_r_EVN_NtiEqn2Mtrx_KaTSXR_r_EVN_NtiEqn2Mtrx_rt_Array_Float_54_21:0, KaTSXR_r_EVN_NtiEqn2Mtrx_KaTSXR_r_EVN_NtiEqn2Mtrx_rt_Array_Float_54_22:0, KaTSXR_r_EVN_NtiEqn2Mtrx_KaTSXR_r_EVN_NtiEqn2Mtrx_rt_Array_Float_54_23:0, KaTSXR_r_EVN_NtiEqn2Mtrx_KaTSXR_r_EVN_NtiEqn2Mtrx_rt_Array_Float_54_24:0, KaTSXR_r_EVN_NtiEqn2Mtrx_KaTSXR_r_EVN_NtiEqn2Mtrx_rt_Array_Float_54_25:0, KaTSXR_r_EVN_NtiEqn2Mtrx_KaTSXR_r_EVN_NtiEqn2Mtrx_rt_Array_Float_54_26:0, KaTSXR_r_EVN_NtiEqn2Mtrx_KaTSXR_r_EVN_NtiEqn2Mtrx_rt_Array_Float_54_27:0, KaTSXR_r_EVN_NtiEqn2Mtrx_KaTSXR_r_EVN_NtiEqn2Mtrx_rt_Array_Float_54_28:0, KaTSXR_r_EVN_NtiEqn2Mtrx_KaTSXR_r_EVN_NtiEqn2Mtrx_rt_Array_Float_54_29:0, KaTSXR_r_EVN_NtiEqn2Mtrx_KaTSXR_r_EVN_NtiEqn2Mtrx_rt_Array_Float_54_30:0, KaTSXR_r_EVN_NtiEqn2Mtrx_KaTSXR_r_EVN_NtiEqn2Mtrx_rt_Array_Float_54_31:0, KaTSXR_r_EVN_NtiEqn2Mtrx_KaTSXR_r_EVN_NtiEqn2Mtrx_rt_Array_Float_54_32:0, KaTSXR_r_EVN_NtiEqn2Mtrx_KaTSXR_r_EVN_NtiEqn2Mtrx_rt_Array_Float_54_33:0, KaTSXR_r_EVN_NtiEqn2Mtrx_KaTSXR_r_EVN_NtiEqn2Mtrx_rt_Array_Float_54_34:0, KaTSXR_r_EVN_NtiEqn2Mtrx_KaTSXR_r_EVN_NtiEqn2Mtrx_rt_Array_Float_54_35:0, KaTSXR_r_EVN_NtiEqn2Mtrx_KaTSXR_r_EVN_NtiEqn2Mtrx_rt_Array_Float_54_36:0, KaTSXR_r_EVN_NtiEqn2Mtrx_KaTSXR_r_EVN_NtiEqn2Mtrx_rt_Array_Float_54_37:0, KaTSXR_r_EVN_NtiEqn2Mtrx_KaTSXR_r_EVN_NtiEqn2Mtrx_rt_Array_Float_54_38:0, KaTSXR_r_EVN_NtiEqn2Mtrx_KaTSXR_r_EVN_NtiEqn2Mtrx_rt_Array_Float_54_39:0, KaTSXR_r_EVN_NtiEqn2Mtrx_KaTSXR_r_EVN_NtiEqn2Mtrx_rt_Array_Float_54_40:0, KaTSXR_r_EVN_NtiEqn2Mtrx_KaTSXR_r_EVN_NtiEqn2Mtrx_rt_Array_Float_54_41:0, KaTSXR_r_EVN_NtiEqn2Mtrx_KaTSXR_r_EVN_NtiEqn2Mtrx_rt_Array_Float_54_42:0, KaTSXR_r_EVN_NtiEqn2Mtrx_KaTSXR_r_EVN_NtiEqn2Mtrx_rt_Array_Float_54_43:0, KaTSXR_r_EVN_NtiEqn2Mtrx_KaTSXR_r_EVN_NtiEqn2Mtrx_rt_Array_Float_54_44:0, KaTSXR_r_EVN_NtiEqn2Mtrx_KaTSXR_r_EVN_NtiEqn2Mtrx_rt_Array_Float_54_45:0, KaTSXR_r_EVN_NtiEqn2Mtrx_KaTSXR_r_EVN_NtiEqn2Mtrx_rt_Array_Float_54_46:0, KaTSXR_r_EVN_NtiEqn2Mtrx_KaTSXR_r_EVN_NtiEqn2Mtrx_rt_Array_Float_54_47:0, KaTSXR_r_EVN_NtiEqn2Mtrx_KaTSXR_r_EVN_NtiEqn2Mtrx_rt_Array_Float_54_48:0, KaTSXR_r_EVN_NtiEqn2Mtrx_KaTSXR_r_EVN_NtiEqn2Mtrx_rt_Array_Float_54_49:0, KaTSXR_r_EVN_NtiEqn2Mtrx_KaTSXR_r_EVN_NtiEqn2Mtrx_rt_Array_Float_54_50:0, KaTSXR_r_EVN_NtiEqn2Mtrx_KaTSXR_r_EVN_NtiEqn2Mtrx_rt_Array_Float_54_51:0, KaTSXR_r_EVN_NtiEqn2Mtrx_KaTSXR_r_EVN_NtiEqn2Mtrx_rt_Array_Float_54_52:0, KaTSXR_r_EVN_NtiEqn2Mtrx_KaTSXR_r_EVN_NtiEqn2Mtrx_rt_Array_Float_54_53:0, KaTSXR_r_EVN_NtiEqn2Mtrx_KaTSXR_r_EVN_NtiEqn2Mtrx_rt_Array_Float_54_54:0], parameter=KaTSXR_r_EVN_NtiEqn2Mtrx}, required-interface=KaTSXR_r_EVN_NtiEqn2Mtrx
      KaTSXR_r_EVN_TM1_ToConstrn: parameter-require-com-spec{init-value=KaTSXR_r_EVN_TM1_ToConstrn_KaTSXR_r_EVN_TM1_ToConstrn:[KaTSXR_r_EVN_TM1_ToConstrn_KaTSXR_r_EVN_TM1_ToConstrn_rt_Array_Float_126_1:0, KaTSXR_r_EVN_TM1_ToConstrn_KaTSXR_r_EVN_TM1_ToConstrn_rt_Array_Float_126_2:0, KaTSXR_r_EVN_TM1_ToConstrn_KaTSXR_r_EVN_TM1_ToConstrn_rt_Array_Float_126_3:0, KaTSXR_r_EVN_TM1_ToConstrn_KaTSXR_r_EVN_TM1_ToConstrn_rt_Array_Float_126_4:0, KaTSXR_r_EVN_TM1_ToConstrn_KaTSXR_r_EVN_TM1_ToConstrn_rt_Array_Float_126_5:0, KaTSXR_r_EVN_TM1_ToConstrn_KaTSXR_r_EVN_TM1_ToConstrn_rt_Array_Float_126_6:0, KaTSXR_r_EVN_TM1_ToConstrn_KaTSXR_r_EVN_TM1_ToConstrn_rt_Array_Float_126_7:0, KaTSXR_r_EVN_TM1_ToConstrn_KaTSXR_r_EVN_TM1_ToConstrn_rt_Array_Float_126_8:0, KaTSXR_r_EVN_TM1_ToConstrn_KaTSXR_r_EVN_TM1_ToConstrn_rt_Array_Float_126_9:0, KaTSXR_r_EVN_TM1_ToConstrn_KaTSXR_r_EVN_TM1_ToConstrn_rt_Array_Float_126_10:0, KaTSXR_r_EVN_TM1_ToConstrn_KaTSXR_r_EVN_TM1_ToConstrn_rt_Array_Float_126_11:0, KaTSXR_r_EVN_TM1_ToConstrn_KaTSXR_r_EVN_TM1_ToConstrn_rt_Array_Float_126_12:0, KaTSXR_r_EVN_TM1_ToConstrn_KaTSXR_r_EVN_TM1_ToConstrn_rt_Array_Float_126_13:0, KaTSXR_r_EVN_TM1_ToConstrn_KaTSXR_r_EVN_TM1_ToConstrn_rt_Array_Float_126_14:0, KaTSXR_r_EVN_TM1_ToConstrn_KaTSXR_r_EVN_TM1_ToConstrn_rt_Array_Float_126_15:0, KaTSXR_r_EVN_TM1_ToConstrn_KaTSXR_r_EVN_TM1_ToConstrn_rt_Array_Float_126_16:0, KaTSXR_r_EVN_TM1_ToConstrn_KaTSXR_r_EVN_TM1_ToConstrn_rt_Array_Float_126_17:0, KaTSXR_r_EVN_TM1_ToConstrn_KaTSXR_r_EVN_TM1_ToConstrn_rt_Array_Float_126_18:0, KaTSXR_r_EVN_TM1_ToConstrn_KaTSXR_r_EVN_TM1_ToConstrn_rt_Array_Float_126_19:0, KaTSXR_r_EVN_TM1_ToConstrn_KaTSXR_r_EVN_TM1_ToConstrn_rt_Array_Float_126_20:0, KaTSXR_r_EVN_TM1_ToConstrn_KaTSXR_r_EVN_TM1_ToConstrn_rt_Array_Float_126_21:0, KaTSXR_r_EVN_TM1_ToConstrn_KaTSXR_r_EVN_TM1_ToConstrn_rt_Array_Float_126_22:0, KaTSXR_r_EVN_TM1_ToConstrn_KaTSXR_r_EVN_TM1_ToConstrn_rt_Array_Float_126_23:0, KaTSXR_r_EVN_TM1_ToConstrn_KaTSXR_r_EVN_TM1_ToConstrn_rt_Array_Float_126_24:0, KaTSXR_r_EVN_TM1_ToConstrn_KaTSXR_r_EVN_TM1_ToConstrn_rt_Array_Float_126_25:0, KaTSXR_r_EVN_TM1_ToConstrn_KaTSXR_r_EVN_TM1_ToConstrn_rt_Array_Float_126_26:0, KaTSXR_r_EVN_TM1_ToConstrn_KaTSXR_r_EVN_TM1_ToConstrn_rt_Array_Float_126_27:0, KaTSXR_r_EVN_TM1_ToConstrn_KaTSXR_r_EVN_TM1_ToConstrn_rt_Array_Float_126_28:0, KaTSXR_r_EVN_TM1_ToConstrn_KaTSXR_r_EVN_TM1_ToConstrn_rt_Array_Float_126_29:0, KaTSXR_r_EVN_TM1_ToConstrn_KaTSXR_r_EVN_TM1_ToConstrn_rt_Array_Float_126_30:0, KaTSXR_r_EVN_TM1_ToConstrn_KaTSXR_r_EVN_TM1_ToConstrn_rt_Array_Float_126_31:0, KaTSXR_r_EVN_TM1_ToConstrn_KaTSXR_r_EVN_TM1_ToConstrn_rt_Array_Float_126_32:0, KaTSXR_r_EVN_TM1_ToConstrn_KaTSXR_r_EVN_TM1_ToConstrn_rt_Array_Float_126_33:0, KaTSXR_r_EVN_TM1_ToConstrn_KaTSXR_r_EVN_TM1_ToConstrn_rt_Array_Float_126_34:0, KaTSXR_r_EVN_TM1_ToConstrn_KaTSXR_r_EVN_TM1_ToConstrn_rt_Array_Float_126_35:0, KaTSXR_r_EVN_TM1_ToConstrn_KaTSXR_r_EVN_TM1_ToConstrn_rt_Array_Float_126_36:0, KaTSXR_r_EVN_TM1_ToConstrn_KaTSXR_r_EVN_TM1_ToConstrn_rt_Array_Float_126_37:0, KaTSXR_r_EVN_TM1_ToConstrn_KaTSXR_r_EVN_TM1_ToConstrn_rt_Array_Float_126_38:0, KaTSXR_r_EVN_TM1_ToConstrn_KaTSXR_r_EVN_TM1_ToConstrn_rt_Array_Float_126_39:0, KaTSXR_r_EVN_TM1_ToConstrn_KaTSXR_r_EVN_TM1_ToConstrn_rt_Array_Float_126_40:0, KaTSXR_r_EVN_TM1_ToConstrn_KaTSXR_r_EVN_TM1_ToConstrn_rt_Array_Float_126_41:0, KaTSXR_r_EVN_TM1_ToConstrn_KaTSXR_r_EVN_TM1_ToConstrn_rt_Array_Float_126_42:0, KaTSXR_r_EVN_TM1_ToConstrn_KaTSXR_r_EVN_TM1_ToConstrn_rt_Array_Float_126_43:0, KaTSXR_r_EVN_TM1_ToConstrn_KaTSXR_r_EVN_TM1_ToConstrn_rt_Array_Float_126_44:0, KaTSXR_r_EVN_TM1_ToConstrn_KaTSXR_r_EVN_TM1_ToConstrn_rt_Array_Float_126_45:0, KaTSXR_r_EVN_TM1_ToConstrn_KaTSXR_r_EVN_TM1_ToConstrn_rt_Array_Float_126_46:0, KaTSXR_r_EVN_TM1_ToConstrn_KaTSXR_r_EVN_TM1_ToConstrn_rt_Array_Float_126_47:0, KaTSXR_r_EVN_TM1_ToConstrn_KaTSXR_r_EVN_TM1_ToConstrn_rt_Array_Float_126_48:0, KaTSXR_r_EVN_TM1_ToConstrn_KaTSXR_r_EVN_TM1_ToConstrn_rt_Array_Float_126_49:0, KaTSXR_r_EVN_TM1_ToConstrn_KaTSXR_r_EVN_TM1_ToConstrn_rt_Array_Float_126_50:0, KaTSXR_r_EVN_TM1_ToConstrn_KaTSXR_r_EVN_TM1_ToConstrn_rt_Array_Float_126_51:0, KaTSXR_r_EVN_TM1_ToConstrn_KaTSXR_r_EVN_TM1_ToConstrn_rt_Array_Float_126_52:0, KaTSXR_r_EVN_TM1_ToConstrn_KaTSXR_r_EVN_TM1_ToConstrn_rt_Array_Float_126_53:0, KaTSXR_r_EVN_TM1_ToConstrn_KaTSXR_r_EVN_TM1_ToConstrn_rt_Array_Float_126_54:0, KaTSXR_r_EVN_TM1_ToConstrn_KaTSXR_r_EVN_TM1_ToConstrn_rt_Array_Float_126_55:0, KaTSXR_r_EVN_TM1_ToConstrn_KaTSXR_r_EVN_TM1_ToConstrn_rt_Array_Float_126_56:0, KaTSXR_r_EVN_TM1_ToConstrn_KaTSXR_r_EVN_TM1_ToConstrn_rt_Array_Float_126_57:0, KaTSXR_r_EVN_TM1_ToConstrn_KaTSXR_r_EVN_TM1_ToConstrn_rt_Array_Float_126_58:0, KaTSXR_r_EVN_TM1_ToConstrn_KaTSXR_r_EVN_TM1_ToConstrn_rt_Array_Float_126_59:0, KaTSXR_r_EVN_TM1_ToConstrn_KaTSXR_r_EVN_TM1_ToConstrn_rt_Array_Float_126_60:0, KaTSXR_r_EVN_TM1_ToConstrn_KaTSXR_r_EVN_TM1_ToConstrn_rt_Array_Float_126_61:0, KaTSXR_r_EVN_TM1_ToConstrn_KaTSXR_r_EVN_TM1_ToConstrn_rt_Array_Float_126_62:0, KaTSXR_r_EVN_TM1_ToConstrn_KaTSXR_r_EVN_TM1_ToConstrn_rt_Array_Float_126_63:0, KaTSXR_r_EVN_TM1_ToConstrn_KaTSXR_r_EVN_TM1_ToConstrn_rt_Array_Float_126_64:0, KaTSXR_r_EVN_TM1_ToConstrn_KaTSXR_r_EVN_TM1_ToConstrn_rt_Array_Float_126_65:0, KaTSXR_r_EVN_TM1_ToConstrn_KaTSXR_r_EVN_TM1_ToConstrn_rt_Array_Float_126_66:0, KaTSXR_r_EVN_TM1_ToConstrn_KaTSXR_r_EVN_TM1_ToConstrn_rt_Array_Float_126_67:0, KaTSXR_r_EVN_TM1_ToConstrn_KaTSXR_r_EVN_TM1_ToConstrn_rt_Array_Float_126_68:0, KaTSXR_r_EVN_TM1_ToConstrn_KaTSXR_r_EVN_TM1_ToConstrn_rt_Array_Float_126_69:0, KaTSXR_r_EVN_TM1_ToConstrn_KaTSXR_r_EVN_TM1_ToConstrn_rt_Array_Float_126_70:0, KaTSXR_r_EVN_TM1_ToConstrn_KaTSXR_r_EVN_TM1_ToConstrn_rt_Array_Float_126_71:0, KaTSXR_r_EVN_TM1_ToConstrn_KaTSXR_r_EVN_TM1_ToConstrn_rt_Array_Float_126_72:0, KaTSXR_r_EVN_TM1_ToConstrn_KaTSXR_r_EVN_TM1_ToConstrn_rt_Array_Float_126_73:0, KaTSXR_r_EVN_TM1_ToConstrn_KaTSXR_r_EVN_TM1_ToConstrn_rt_Array_Float_126_74:0, KaTSXR_r_EVN_TM1_ToConstrn_KaTSXR_r_EVN_TM1_ToConstrn_rt_Array_Float_126_75:0, KaTSXR_r_EVN_TM1_ToConstrn_KaTSXR_r_EVN_TM1_ToConstrn_rt_Array_Float_126_76:0, KaTSXR_r_EVN_TM1_ToConstrn_KaTSXR_r_EVN_TM1_ToConstrn_rt_Array_Float_126_77:0, KaTSXR_r_EVN_TM1_ToConstrn_KaTSXR_r_EVN_TM1_ToConstrn_rt_Array_Float_126_78:0, KaTSXR_r_EVN_TM1_ToConstrn_KaTSXR_r_EVN_TM1_ToConstrn_rt_Array_Float_126_79:0, KaTSXR_r_EVN_TM1_ToConstrn_KaTSXR_r_EVN_TM1_ToConstrn_rt_Array_Float_126_80:0, KaTSXR_r_EVN_TM1_ToConstrn_KaTSXR_r_EVN_TM1_ToConstrn_rt_Array_Float_126_81:0, KaTSXR_r_EVN_TM1_ToConstrn_KaTSXR_r_EVN_TM1_ToConstrn_rt_Array_Float_126_82:0, KaTSXR_r_EVN_TM1_ToConstrn_KaTSXR_r_EVN_TM1_ToConstrn_rt_Array_Float_126_83:0, KaTSXR_r_EVN_TM1_ToConstrn_KaTSXR_r_EVN_TM1_ToConstrn_rt_Array_Float_126_84:0, KaTSXR_r_EVN_TM1_ToConstrn_KaTSXR_r_EVN_TM1_ToConstrn_rt_Array_Float_126_85:0, KaTSXR_r_EVN_TM1_ToConstrn_KaTSXR_r_EVN_TM1_ToConstrn_rt_Array_Float_126_86:0, KaTSXR_r_EVN_TM1_ToConstrn_KaTSXR_r_EVN_TM1_ToConstrn_rt_Array_Float_126_87:0, KaTSXR_r_EVN_TM1_ToConstrn_KaTSXR_r_EVN_TM1_ToConstrn_rt_Array_Float_126_88:0, KaTSXR_r_EVN_TM1_ToConstrn_KaTSXR_r_EVN_TM1_ToConstrn_rt_Array_Float_126_89:0, KaTSXR_r_EVN_TM1_ToConstrn_KaTSXR_r_EVN_TM1_ToConstrn_rt_Array_Float_126_90:0, KaTSXR_r_EVN_TM1_ToConstrn_KaTSXR_r_EVN_TM1_ToConstrn_rt_Array_Float_126_91:0, KaTSXR_r_EVN_TM1_ToConstrn_KaTSXR_r_EVN_TM1_ToConstrn_rt_Array_Float_126_92:0, KaTSXR_r_EVN_TM1_ToConstrn_KaTSXR_r_EVN_TM1_ToConstrn_rt_Array_Float_126_93:0, KaTSXR_r_EVN_TM1_ToConstrn_KaTSXR_r_EVN_TM1_ToConstrn_rt_Array_Float_126_94:0, KaTSXR_r_EVN_TM1_ToConstrn_KaTSXR_r_EVN_TM1_ToConstrn_rt_Array_Float_126_95:0, KaTSXR_r_EVN_TM1_ToConstrn_KaTSXR_r_EVN_TM1_ToConstrn_rt_Array_Float_126_96:0, KaTSXR_r_EVN_TM1_ToConstrn_KaTSXR_r_EVN_TM1_ToConstrn_rt_Array_Float_126_97:0, KaTSXR_r_EVN_TM1_ToConstrn_KaTSXR_r_EVN_TM1_ToConstrn_rt_Array_Float_126_98:0, KaTSXR_r_EVN_TM1_ToConstrn_KaTSXR_r_EVN_TM1_ToConstrn_rt_Array_Float_126_99:0, KaTSXR_r_EVN_TM1_ToConstrn_KaTSXR_r_EVN_TM1_ToConstrn_rt_Array_Float_126_100:0, KaTSXR_r_EVN_TM1_ToConstrn_KaTSXR_r_EVN_TM1_ToConstrn_rt_Array_Float_126_101:0, KaTSXR_r_EVN_TM1_ToConstrn_KaTSXR_r_EVN_TM1_ToConstrn_rt_Array_Float_126_102:0, KaTSXR_r_EVN_TM1_ToConstrn_KaTSXR_r_EVN_TM1_ToConstrn_rt_Array_Float_126_103:0, KaTSXR_r_EVN_TM1_ToConstrn_KaTSXR_r_EVN_TM1_ToConstrn_rt_Array_Float_126_104:0, KaTSXR_r_EVN_TM1_ToConstrn_KaTSXR_r_EVN_TM1_ToConstrn_rt_Array_Float_126_105:0, KaTSXR_r_EVN_TM1_ToConstrn_KaTSXR_r_EVN_TM1_ToConstrn_rt_Array_Float_126_106:0, KaTSXR_r_EVN_TM1_ToConstrn_KaTSXR_r_EVN_TM1_ToConstrn_rt_Array_Float_126_107:0, KaTSXR_r_EVN_TM1_ToConstrn_KaTSXR_r_EVN_TM1_ToConstrn_rt_Array_Float_126_108:0, KaTSXR_r_EVN_TM1_ToConstrn_KaTSXR_r_EVN_TM1_ToConstrn_rt_Array_Float_126_109:0, KaTSXR_r_EVN_TM1_ToConstrn_KaTSXR_r_EVN_TM1_ToConstrn_rt_Array_Float_126_110:0, KaTSXR_r_EVN_TM1_ToConstrn_KaTSXR_r_EVN_TM1_ToConstrn_rt_Array_Float_126_111:0, KaTSXR_r_EVN_TM1_ToConstrn_KaTSXR_r_EVN_TM1_ToConstrn_rt_Array_Float_126_112:0, KaTSXR_r_EVN_TM1_ToConstrn_KaTSXR_r_EVN_TM1_ToConstrn_rt_Array_Float_126_113:0, KaTSXR_r_EVN_TM1_ToConstrn_KaTSXR_r_EVN_TM1_ToConstrn_rt_Array_Float_126_114:0, KaTSXR_r_EVN_TM1_ToConstrn_KaTSXR_r_EVN_TM1_ToConstrn_rt_Array_Float_126_115:0, KaTSXR_r_EVN_TM1_ToConstrn_KaTSXR_r_EVN_TM1_ToConstrn_rt_Array_Float_126_116:0, KaTSXR_r_EVN_TM1_ToConstrn_KaTSXR_r_EVN_TM1_ToConstrn_rt_Array_Float_126_117:0, KaTSXR_r_EVN_TM1_ToConstrn_KaTSXR_r_EVN_TM1_ToConstrn_rt_Array_Float_126_118:0, KaTSXR_r_EVN_TM1_ToConstrn_KaTSXR_r_EVN_TM1_ToConstrn_rt_Array_Float_126_119:0, KaTSXR_r_EVN_TM1_ToConstrn_KaTSXR_r_EVN_TM1_ToConstrn_rt_Array_Float_126_120:0, KaTSXR_r_EVN_TM1_ToConstrn_KaTSXR_r_EVN_TM1_ToConstrn_rt_Array_Float_126_121:0, KaTSXR_r_EVN_TM1_ToConstrn_KaTSXR_r_EVN_TM1_ToConstrn_rt_Array_Float_126_122:0, KaTSXR_r_EVN_TM1_ToConstrn_KaTSXR_r_EVN_TM1_ToConstrn_rt_Array_Float_126_123:0, KaTSXR_r_EVN_TM1_ToConstrn_KaTSXR_r_EVN_TM1_ToConstrn_rt_Array_Float_126_124:0, KaTSXR_r_EVN_TM1_ToConstrn_KaTSXR_r_EVN_TM1_ToConstrn_rt_Array_Float_126_125:0, KaTSXR_r_EVN_TM1_ToConstrn_KaTSXR_r_EVN_TM1_ToConstrn_rt_Array_Float_126_126:0], parameter=KaTSXR_r_EVN_TM1_ToConstrn}, required-interface=KaTSXR_r_EVN_TM1_ToConstrn
      KaTSXR_r_G_NaCalcEqnMtrx: parameter-require-com-spec{init-value=KaTSXR_r_G_NaCalcEqnMtrx_KaTSXR_r_G_NaCalcEqnMtrx:[KaTSXR_r_G_NaCalcEqnMtrx_KaTSXR_r_G_NaCalcEqnMtrx_rt_Array_Float_27_1:0, KaTSXR_r_G_NaCalcEqnMtrx_KaTSXR_r_G_NaCalcEqnMtrx_rt_Array_Float_27_2:0, KaTSXR_r_G_NaCalcEqnMtrx_KaTSXR_r_G_NaCalcEqnMtrx_rt_Array_Float_27_3:0, KaTSXR_r_G_NaCalcEqnMtrx_KaTSXR_r_G_NaCalcEqnMtrx_rt_Array_Float_27_4:0, KaTSXR_r_G_NaCalcEqnMtrx_KaTSXR_r_G_NaCalcEqnMtrx_rt_Array_Float_27_5:0, KaTSXR_r_G_NaCalcEqnMtrx_KaTSXR_r_G_NaCalcEqnMtrx_rt_Array_Float_27_6:0, KaTSXR_r_G_NaCalcEqnMtrx_KaTSXR_r_G_NaCalcEqnMtrx_rt_Array_Float_27_7:0, KaTSXR_r_G_NaCalcEqnMtrx_KaTSXR_r_G_NaCalcEqnMtrx_rt_Array_Float_27_8:0, KaTSXR_r_G_NaCalcEqnMtrx_KaTSXR_r_G_NaCalcEqnMtrx_rt_Array_Float_27_9:0, KaTSXR_r_G_NaCalcEqnMtrx_KaTSXR_r_G_NaCalcEqnMtrx_rt_Array_Float_27_10:0, KaTSXR_r_G_NaCalcEqnMtrx_KaTSXR_r_G_NaCalcEqnMtrx_rt_Array_Float_27_11:0, KaTSXR_r_G_NaCalcEqnMtrx_KaTSXR_r_G_NaCalcEqnMtrx_rt_Array_Float_27_12:0, KaTSXR_r_G_NaCalcEqnMtrx_KaTSXR_r_G_NaCalcEqnMtrx_rt_Array_Float_27_13:0, KaTSXR_r_G_NaCalcEqnMtrx_KaTSXR_r_G_NaCalcEqnMtrx_rt_Array_Float_27_14:0, KaTSXR_r_G_NaCalcEqnMtrx_KaTSXR_r_G_NaCalcEqnMtrx_rt_Array_Float_27_15:0, KaTSXR_r_G_NaCalcEqnMtrx_KaTSXR_r_G_NaCalcEqnMtrx_rt_Array_Float_27_16:0, KaTSXR_r_G_NaCalcEqnMtrx_KaTSXR_r_G_NaCalcEqnMtrx_rt_Array_Float_27_17:0, KaTSXR_r_G_NaCalcEqnMtrx_KaTSXR_r_G_NaCalcEqnMtrx_rt_Array_Float_27_18:0, KaTSXR_r_G_NaCalcEqnMtrx_KaTSXR_r_G_NaCalcEqnMtrx_rt_Array_Float_27_19:0, KaTSXR_r_G_NaCalcEqnMtrx_KaTSXR_r_G_NaCalcEqnMtrx_rt_Array_Float_27_20:0, KaTSXR_r_G_NaCalcEqnMtrx_KaTSXR_r_G_NaCalcEqnMtrx_rt_Array_Float_27_21:0, KaTSXR_r_G_NaCalcEqnMtrx_KaTSXR_r_G_NaCalcEqnMtrx_rt_Array_Float_27_22:0, KaTSXR_r_G_NaCalcEqnMtrx_KaTSXR_r_G_NaCalcEqnMtrx_rt_Array_Float_27_23:0, KaTSXR_r_G_NaCalcEqnMtrx_KaTSXR_r_G_NaCalcEqnMtrx_rt_Array_Float_27_24:0, KaTSXR_r_G_NaCalcEqnMtrx_KaTSXR_r_G_NaCalcEqnMtrx_rt_Array_Float_27_25:0, KaTSXR_r_G_NaCalcEqnMtrx_KaTSXR_r_G_NaCalcEqnMtrx_rt_Array_Float_27_26:0, KaTSXR_r_G_NaCalcEqnMtrx_KaTSXR_r_G_NaCalcEqnMtrx_rt_Array_Float_27_27:0], parameter=KaTSXR_r_G_NaCalcEqnMtrx}, required-interface=KaTSXR_r_G_NaCalcEqnMtrx
      KaTSXR_r_G_NbCalcEqnMtrx: parameter-require-com-spec{init-value=KaTSXR_r_G_NbCalcEqnMtrx_KaTSXR_r_G_NbCalcEqnMtrx:[KaTSXR_r_G_NbCalcEqnMtrx_KaTSXR_r_G_NbCalcEqnMtrx_rt_Array_Float_27_1:0, KaTSXR_r_G_NbCalcEqnMtrx_KaTSXR_r_G_NbCalcEqnMtrx_rt_Array_Float_27_2:0, KaTSXR_r_G_NbCalcEqnMtrx_KaTSXR_r_G_NbCalcEqnMtrx_rt_Array_Float_27_3:0, KaTSXR_r_G_NbCalcEqnMtrx_KaTSXR_r_G_NbCalcEqnMtrx_rt_Array_Float_27_4:0, KaTSXR_r_G_NbCalcEqnMtrx_KaTSXR_r_G_NbCalcEqnMtrx_rt_Array_Float_27_5:0, KaTSXR_r_G_NbCalcEqnMtrx_KaTSXR_r_G_NbCalcEqnMtrx_rt_Array_Float_27_6:0, KaTSXR_r_G_NbCalcEqnMtrx_KaTSXR_r_G_NbCalcEqnMtrx_rt_Array_Float_27_7:0, KaTSXR_r_G_NbCalcEqnMtrx_KaTSXR_r_G_NbCalcEqnMtrx_rt_Array_Float_27_8:0, KaTSXR_r_G_NbCalcEqnMtrx_KaTSXR_r_G_NbCalcEqnMtrx_rt_Array_Float_27_9:0, KaTSXR_r_G_NbCalcEqnMtrx_KaTSXR_r_G_NbCalcEqnMtrx_rt_Array_Float_27_10:0, KaTSXR_r_G_NbCalcEqnMtrx_KaTSXR_r_G_NbCalcEqnMtrx_rt_Array_Float_27_11:0, KaTSXR_r_G_NbCalcEqnMtrx_KaTSXR_r_G_NbCalcEqnMtrx_rt_Array_Float_27_12:0, KaTSXR_r_G_NbCalcEqnMtrx_KaTSXR_r_G_NbCalcEqnMtrx_rt_Array_Float_27_13:0, KaTSXR_r_G_NbCalcEqnMtrx_KaTSXR_r_G_NbCalcEqnMtrx_rt_Array_Float_27_14:0, KaTSXR_r_G_NbCalcEqnMtrx_KaTSXR_r_G_NbCalcEqnMtrx_rt_Array_Float_27_15:0, KaTSXR_r_G_NbCalcEqnMtrx_KaTSXR_r_G_NbCalcEqnMtrx_rt_Array_Float_27_16:0, KaTSXR_r_G_NbCalcEqnMtrx_KaTSXR_r_G_NbCalcEqnMtrx_rt_Array_Float_27_17:0, KaTSXR_r_G_NbCalcEqnMtrx_KaTSXR_r_G_NbCalcEqnMtrx_rt_Array_Float_27_18:0, KaTSXR_r_G_NbCalcEqnMtrx_KaTSXR_r_G_NbCalcEqnMtrx_rt_Array_Float_27_19:0, KaTSXR_r_G_NbCalcEqnMtrx_KaTSXR_r_G_NbCalcEqnMtrx_rt_Array_Float_27_20:0, KaTSXR_r_G_NbCalcEqnMtrx_KaTSXR_r_G_NbCalcEqnMtrx_rt_Array_Float_27_21:0, KaTSXR_r_G_NbCalcEqnMtrx_KaTSXR_r_G_NbCalcEqnMtrx_rt_Array_Float_27_22:0, KaTSXR_r_G_NbCalcEqnMtrx_KaTSXR_r_G_NbCalcEqnMtrx_rt_Array_Float_27_23:0, KaTSXR_r_G_NbCalcEqnMtrx_KaTSXR_r_G_NbCalcEqnMtrx_rt_Array_Float_27_24:0, KaTSXR_r_G_NbCalcEqnMtrx_KaTSXR_r_G_NbCalcEqnMtrx_rt_Array_Float_27_25:0, KaTSXR_r_G_NbCalcEqnMtrx_KaTSXR_r_G_NbCalcEqnMtrx_rt_Array_Float_27_26:0, KaTSXR_r_G_NbCalcEqnMtrx_KaTSXR_r_G_NbCalcEqnMtrx_rt_Array_Float_27_27:0], parameter=KaTSXR_r_G_NbCalcEqnMtrx}, required-interface=KaTSXR_r_G_NbCalcEqnMtrx
      KaTSXR_r_G_Nc1CalcEqnMtrx: parameter-require-com-spec{init-value=KaTSXR_r_G_Nc1CalcEqnMtrx_KaTSXR_r_G_Nc1CalcEqnMtrx:[KaTSXR_r_G_Nc1CalcEqnMtrx_KaTSXR_r_G_Nc1CalcEqnMtrx_rt_Array_Float_27_1:0, KaTSXR_r_G_Nc1CalcEqnMtrx_KaTSXR_r_G_Nc1CalcEqnMtrx_rt_Array_Float_27_2:0, KaTSXR_r_G_Nc1CalcEqnMtrx_KaTSXR_r_G_Nc1CalcEqnMtrx_rt_Array_Float_27_3:0, KaTSXR_r_G_Nc1CalcEqnMtrx_KaTSXR_r_G_Nc1CalcEqnMtrx_rt_Array_Float_27_4:0, KaTSXR_r_G_Nc1CalcEqnMtrx_KaTSXR_r_G_Nc1CalcEqnMtrx_rt_Array_Float_27_5:0, KaTSXR_r_G_Nc1CalcEqnMtrx_KaTSXR_r_G_Nc1CalcEqnMtrx_rt_Array_Float_27_6:0, KaTSXR_r_G_Nc1CalcEqnMtrx_KaTSXR_r_G_Nc1CalcEqnMtrx_rt_Array_Float_27_7:0, KaTSXR_r_G_Nc1CalcEqnMtrx_KaTSXR_r_G_Nc1CalcEqnMtrx_rt_Array_Float_27_8:0, KaTSXR_r_G_Nc1CalcEqnMtrx_KaTSXR_r_G_Nc1CalcEqnMtrx_rt_Array_Float_27_9:0, KaTSXR_r_G_Nc1CalcEqnMtrx_KaTSXR_r_G_Nc1CalcEqnMtrx_rt_Array_Float_27_10:0, KaTSXR_r_G_Nc1CalcEqnMtrx_KaTSXR_r_G_Nc1CalcEqnMtrx_rt_Array_Float_27_11:0, KaTSXR_r_G_Nc1CalcEqnMtrx_KaTSXR_r_G_Nc1CalcEqnMtrx_rt_Array_Float_27_12:0, KaTSXR_r_G_Nc1CalcEqnMtrx_KaTSXR_r_G_Nc1CalcEqnMtrx_rt_Array_Float_27_13:0, KaTSXR_r_G_Nc1CalcEqnMtrx_KaTSXR_r_G_Nc1CalcEqnMtrx_rt_Array_Float_27_14:0, KaTSXR_r_G_Nc1CalcEqnMtrx_KaTSXR_r_G_Nc1CalcEqnMtrx_rt_Array_Float_27_15:0, KaTSXR_r_G_Nc1CalcEqnMtrx_KaTSXR_r_G_Nc1CalcEqnMtrx_rt_Array_Float_27_16:0, KaTSXR_r_G_Nc1CalcEqnMtrx_KaTSXR_r_G_Nc1CalcEqnMtrx_rt_Array_Float_27_17:0, KaTSXR_r_G_Nc1CalcEqnMtrx_KaTSXR_r_G_Nc1CalcEqnMtrx_rt_Array_Float_27_18:0, KaTSXR_r_G_Nc1CalcEqnMtrx_KaTSXR_r_G_Nc1CalcEqnMtrx_rt_Array_Float_27_19:0, KaTSXR_r_G_Nc1CalcEqnMtrx_KaTSXR_r_G_Nc1CalcEqnMtrx_rt_Array_Float_27_20:0, KaTSXR_r_G_Nc1CalcEqnMtrx_KaTSXR_r_G_Nc1CalcEqnMtrx_rt_Array_Float_27_21:0, KaTSXR_r_G_Nc1CalcEqnMtrx_KaTSXR_r_G_Nc1CalcEqnMtrx_rt_Array_Float_27_22:0, KaTSXR_r_G_Nc1CalcEqnMtrx_KaTSXR_r_G_Nc1CalcEqnMtrx_rt_Array_Float_27_23:0, KaTSXR_r_G_Nc1CalcEqnMtrx_KaTSXR_r_G_Nc1CalcEqnMtrx_rt_Array_Float_27_24:0, KaTSXR_r_G_Nc1CalcEqnMtrx_KaTSXR_r_G_Nc1CalcEqnMtrx_rt_Array_Float_27_25:0, KaTSXR_r_G_Nc1CalcEqnMtrx_KaTSXR_r_G_Nc1CalcEqnMtrx_rt_Array_Float_27_26:0, KaTSXR_r_G_Nc1CalcEqnMtrx_KaTSXR_r_G_Nc1CalcEqnMtrx_rt_Array_Float_27_27:0], parameter=KaTSXR_r_G_Nc1CalcEqnMtrx}, required-interface=KaTSXR_r_G_Nc1CalcEqnMtrx
      KaTSXR_r_G_NcCalcEqnMtrx: parameter-require-com-spec{init-value=KaTSXR_r_G_NcCalcEqnMtrx_KaTSXR_r_G_NcCalcEqnMtrx:[KaTSXR_r_G_NcCalcEqnMtrx_KaTSXR_r_G_NcCalcEqnMtrx_rt_Array_Float_27_1:0, KaTSXR_r_G_NcCalcEqnMtrx_KaTSXR_r_G_NcCalcEqnMtrx_rt_Array_Float_27_2:0, KaTSXR_r_G_NcCalcEqnMtrx_KaTSXR_r_G_NcCalcEqnMtrx_rt_Array_Float_27_3:0, KaTSXR_r_G_NcCalcEqnMtrx_KaTSXR_r_G_NcCalcEqnMtrx_rt_Array_Float_27_4:0, KaTSXR_r_G_NcCalcEqnMtrx_KaTSXR_r_G_NcCalcEqnMtrx_rt_Array_Float_27_5:0, KaTSXR_r_G_NcCalcEqnMtrx_KaTSXR_r_G_NcCalcEqnMtrx_rt_Array_Float_27_6:0, KaTSXR_r_G_NcCalcEqnMtrx_KaTSXR_r_G_NcCalcEqnMtrx_rt_Array_Float_27_7:0, KaTSXR_r_G_NcCalcEqnMtrx_KaTSXR_r_G_NcCalcEqnMtrx_rt_Array_Float_27_8:0, KaTSXR_r_G_NcCalcEqnMtrx_KaTSXR_r_G_NcCalcEqnMtrx_rt_Array_Float_27_9:0, KaTSXR_r_G_NcCalcEqnMtrx_KaTSXR_r_G_NcCalcEqnMtrx_rt_Array_Float_27_10:0, KaTSXR_r_G_NcCalcEqnMtrx_KaTSXR_r_G_NcCalcEqnMtrx_rt_Array_Float_27_11:0, KaTSXR_r_G_NcCalcEqnMtrx_KaTSXR_r_G_NcCalcEqnMtrx_rt_Array_Float_27_12:0, KaTSXR_r_G_NcCalcEqnMtrx_KaTSXR_r_G_NcCalcEqnMtrx_rt_Array_Float_27_13:0, KaTSXR_r_G_NcCalcEqnMtrx_KaTSXR_r_G_NcCalcEqnMtrx_rt_Array_Float_27_14:0, KaTSXR_r_G_NcCalcEqnMtrx_KaTSXR_r_G_NcCalcEqnMtrx_rt_Array_Float_27_15:0, KaTSXR_r_G_NcCalcEqnMtrx_KaTSXR_r_G_NcCalcEqnMtrx_rt_Array_Float_27_16:0, KaTSXR_r_G_NcCalcEqnMtrx_KaTSXR_r_G_NcCalcEqnMtrx_rt_Array_Float_27_17:0, KaTSXR_r_G_NcCalcEqnMtrx_KaTSXR_r_G_NcCalcEqnMtrx_rt_Array_Float_27_18:0, KaTSXR_r_G_NcCalcEqnMtrx_KaTSXR_r_G_NcCalcEqnMtrx_rt_Array_Float_27_19:0, KaTSXR_r_G_NcCalcEqnMtrx_KaTSXR_r_G_NcCalcEqnMtrx_rt_Array_Float_27_20:0, KaTSXR_r_G_NcCalcEqnMtrx_KaTSXR_r_G_NcCalcEqnMtrx_rt_Array_Float_27_21:0, KaTSXR_r_G_NcCalcEqnMtrx_KaTSXR_r_G_NcCalcEqnMtrx_rt_Array_Float_27_22:0, KaTSXR_r_G_NcCalcEqnMtrx_KaTSXR_r_G_NcCalcEqnMtrx_rt_Array_Float_27_23:0, KaTSXR_r_G_NcCalcEqnMtrx_KaTSXR_r_G_NcCalcEqnMtrx_rt_Array_Float_27_24:0, KaTSXR_r_G_NcCalcEqnMtrx_KaTSXR_r_G_NcCalcEqnMtrx_rt_Array_Float_27_25:0, KaTSXR_r_G_NcCalcEqnMtrx_KaTSXR_r_G_NcCalcEqnMtrx_rt_Array_Float_27_26:0, KaTSXR_r_G_NcCalcEqnMtrx_KaTSXR_r_G_NcCalcEqnMtrx_rt_Array_Float_27_27:0], parameter=KaTSXR_r_G_NcCalcEqnMtrx}, required-interface=KaTSXR_r_G_NcCalcEqnMtrx
      KaTSXR_r_G_TM1_ToConstrn: parameter-require-com-spec{init-value=KaTSXR_r_G_TM1_ToConstrn_KaTSXR_r_G_TM1_ToConstrn:[KaTSXR_r_G_TM1_ToConstrn_KaTSXR_r_G_TM1_ToConstrn_rt_Array_Float_126_1:0, KaTSXR_r_G_TM1_ToConstrn_KaTSXR_r_G_TM1_ToConstrn_rt_Array_Float_126_2:0, KaTSXR_r_G_TM1_ToConstrn_KaTSXR_r_G_TM1_ToConstrn_rt_Array_Float_126_3:0, KaTSXR_r_G_TM1_ToConstrn_KaTSXR_r_G_TM1_ToConstrn_rt_Array_Float_126_4:0, KaTSXR_r_G_TM1_ToConstrn_KaTSXR_r_G_TM1_ToConstrn_rt_Array_Float_126_5:0, KaTSXR_r_G_TM1_ToConstrn_KaTSXR_r_G_TM1_ToConstrn_rt_Array_Float_126_6:0, KaTSXR_r_G_TM1_ToConstrn_KaTSXR_r_G_TM1_ToConstrn_rt_Array_Float_126_7:0, KaTSXR_r_G_TM1_ToConstrn_KaTSXR_r_G_TM1_ToConstrn_rt_Array_Float_126_8:0, KaTSXR_r_G_TM1_ToConstrn_KaTSXR_r_G_TM1_ToConstrn_rt_Array_Float_126_9:0, KaTSXR_r_G_TM1_ToConstrn_KaTSXR_r_G_TM1_ToConstrn_rt_Array_Float_126_10:0, KaTSXR_r_G_TM1_ToConstrn_KaTSXR_r_G_TM1_ToConstrn_rt_Array_Float_126_11:0, KaTSXR_r_G_TM1_ToConstrn_KaTSXR_r_G_TM1_ToConstrn_rt_Array_Float_126_12:0, KaTSXR_r_G_TM1_ToConstrn_KaTSXR_r_G_TM1_ToConstrn_rt_Array_Float_126_13:0, KaTSXR_r_G_TM1_ToConstrn_KaTSXR_r_G_TM1_ToConstrn_rt_Array_Float_126_14:0, KaTSXR_r_G_TM1_ToConstrn_KaTSXR_r_G_TM1_ToConstrn_rt_Array_Float_126_15:0, KaTSXR_r_G_TM1_ToConstrn_KaTSXR_r_G_TM1_ToConstrn_rt_Array_Float_126_16:0, KaTSXR_r_G_TM1_ToConstrn_KaTSXR_r_G_TM1_ToConstrn_rt_Array_Float_126_17:0, KaTSXR_r_G_TM1_ToConstrn_KaTSXR_r_G_TM1_ToConstrn_rt_Array_Float_126_18:0, KaTSXR_r_G_TM1_ToConstrn_KaTSXR_r_G_TM1_ToConstrn_rt_Array_Float_126_19:0, KaTSXR_r_G_TM1_ToConstrn_KaTSXR_r_G_TM1_ToConstrn_rt_Array_Float_126_20:0, KaTSXR_r_G_TM1_ToConstrn_KaTSXR_r_G_TM1_ToConstrn_rt_Array_Float_126_21:0, KaTSXR_r_G_TM1_ToConstrn_KaTSXR_r_G_TM1_ToConstrn_rt_Array_Float_126_22:0, KaTSXR_r_G_TM1_ToConstrn_KaTSXR_r_G_TM1_ToConstrn_rt_Array_Float_126_23:0, KaTSXR_r_G_TM1_ToConstrn_KaTSXR_r_G_TM1_ToConstrn_rt_Array_Float_126_24:0, KaTSXR_r_G_TM1_ToConstrn_KaTSXR_r_G_TM1_ToConstrn_rt_Array_Float_126_25:0, KaTSXR_r_G_TM1_ToConstrn_KaTSXR_r_G_TM1_ToConstrn_rt_Array_Float_126_26:0, KaTSXR_r_G_TM1_ToConstrn_KaTSXR_r_G_TM1_ToConstrn_rt_Array_Float_126_27:0, KaTSXR_r_G_TM1_ToConstrn_KaTSXR_r_G_TM1_ToConstrn_rt_Array_Float_126_28:0, KaTSXR_r_G_TM1_ToConstrn_KaTSXR_r_G_TM1_ToConstrn_rt_Array_Float_126_29:0, KaTSXR_r_G_TM1_ToConstrn_KaTSXR_r_G_TM1_ToConstrn_rt_Array_Float_126_30:0, KaTSXR_r_G_TM1_ToConstrn_KaTSXR_r_G_TM1_ToConstrn_rt_Array_Float_126_31:0, KaTSXR_r_G_TM1_ToConstrn_KaTSXR_r_G_TM1_ToConstrn_rt_Array_Float_126_32:0, KaTSXR_r_G_TM1_ToConstrn_KaTSXR_r_G_TM1_ToConstrn_rt_Array_Float_126_33:0, KaTSXR_r_G_TM1_ToConstrn_KaTSXR_r_G_TM1_ToConstrn_rt_Array_Float_126_34:0, KaTSXR_r_G_TM1_ToConstrn_KaTSXR_r_G_TM1_ToConstrn_rt_Array_Float_126_35:0, KaTSXR_r_G_TM1_ToConstrn_KaTSXR_r_G_TM1_ToConstrn_rt_Array_Float_126_36:0, KaTSXR_r_G_TM1_ToConstrn_KaTSXR_r_G_TM1_ToConstrn_rt_Array_Float_126_37:0, KaTSXR_r_G_TM1_ToConstrn_KaTSXR_r_G_TM1_ToConstrn_rt_Array_Float_126_38:0, KaTSXR_r_G_TM1_ToConstrn_KaTSXR_r_G_TM1_ToConstrn_rt_Array_Float_126_39:0, KaTSXR_r_G_TM1_ToConstrn_KaTSXR_r_G_TM1_ToConstrn_rt_Array_Float_126_40:0, KaTSXR_r_G_TM1_ToConstrn_KaTSXR_r_G_TM1_ToConstrn_rt_Array_Float_126_41:0, KaTSXR_r_G_TM1_ToConstrn_KaTSXR_r_G_TM1_ToConstrn_rt_Array_Float_126_42:0, KaTSXR_r_G_TM1_ToConstrn_KaTSXR_r_G_TM1_ToConstrn_rt_Array_Float_126_43:0, KaTSXR_r_G_TM1_ToConstrn_KaTSXR_r_G_TM1_ToConstrn_rt_Array_Float_126_44:0, KaTSXR_r_G_TM1_ToConstrn_KaTSXR_r_G_TM1_ToConstrn_rt_Array_Float_126_45:0, KaTSXR_r_G_TM1_ToConstrn_KaTSXR_r_G_TM1_ToConstrn_rt_Array_Float_126_46:0, KaTSXR_r_G_TM1_ToConstrn_KaTSXR_r_G_TM1_ToConstrn_rt_Array_Float_126_47:0, KaTSXR_r_G_TM1_ToConstrn_KaTSXR_r_G_TM1_ToConstrn_rt_Array_Float_126_48:0, KaTSXR_r_G_TM1_ToConstrn_KaTSXR_r_G_TM1_ToConstrn_rt_Array_Float_126_49:0, KaTSXR_r_G_TM1_ToConstrn_KaTSXR_r_G_TM1_ToConstrn_rt_Array_Float_126_50:0, KaTSXR_r_G_TM1_ToConstrn_KaTSXR_r_G_TM1_ToConstrn_rt_Array_Float_126_51:0, KaTSXR_r_G_TM1_ToConstrn_KaTSXR_r_G_TM1_ToConstrn_rt_Array_Float_126_52:0, KaTSXR_r_G_TM1_ToConstrn_KaTSXR_r_G_TM1_ToConstrn_rt_Array_Float_126_53:0, KaTSXR_r_G_TM1_ToConstrn_KaTSXR_r_G_TM1_ToConstrn_rt_Array_Float_126_54:0, KaTSXR_r_G_TM1_ToConstrn_KaTSXR_r_G_TM1_ToConstrn_rt_Array_Float_126_55:0, KaTSXR_r_G_TM1_ToConstrn_KaTSXR_r_G_TM1_ToConstrn_rt_Array_Float_126_56:0, KaTSXR_r_G_TM1_ToConstrn_KaTSXR_r_G_TM1_ToConstrn_rt_Array_Float_126_57:0, KaTSXR_r_G_TM1_ToConstrn_KaTSXR_r_G_TM1_ToConstrn_rt_Array_Float_126_58:0, KaTSXR_r_G_TM1_ToConstrn_KaTSXR_r_G_TM1_ToConstrn_rt_Array_Float_126_59:0, KaTSXR_r_G_TM1_ToConstrn_KaTSXR_r_G_TM1_ToConstrn_rt_Array_Float_126_60:0, KaTSXR_r_G_TM1_ToConstrn_KaTSXR_r_G_TM1_ToConstrn_rt_Array_Float_126_61:0, KaTSXR_r_G_TM1_ToConstrn_KaTSXR_r_G_TM1_ToConstrn_rt_Array_Float_126_62:0, KaTSXR_r_G_TM1_ToConstrn_KaTSXR_r_G_TM1_ToConstrn_rt_Array_Float_126_63:0, KaTSXR_r_G_TM1_ToConstrn_KaTSXR_r_G_TM1_ToConstrn_rt_Array_Float_126_64:0, KaTSXR_r_G_TM1_ToConstrn_KaTSXR_r_G_TM1_ToConstrn_rt_Array_Float_126_65:0, KaTSXR_r_G_TM1_ToConstrn_KaTSXR_r_G_TM1_ToConstrn_rt_Array_Float_126_66:0, KaTSXR_r_G_TM1_ToConstrn_KaTSXR_r_G_TM1_ToConstrn_rt_Array_Float_126_67:0, KaTSXR_r_G_TM1_ToConstrn_KaTSXR_r_G_TM1_ToConstrn_rt_Array_Float_126_68:0, KaTSXR_r_G_TM1_ToConstrn_KaTSXR_r_G_TM1_ToConstrn_rt_Array_Float_126_69:0, KaTSXR_r_G_TM1_ToConstrn_KaTSXR_r_G_TM1_ToConstrn_rt_Array_Float_126_70:0, KaTSXR_r_G_TM1_ToConstrn_KaTSXR_r_G_TM1_ToConstrn_rt_Array_Float_126_71:0, KaTSXR_r_G_TM1_ToConstrn_KaTSXR_r_G_TM1_ToConstrn_rt_Array_Float_126_72:0, KaTSXR_r_G_TM1_ToConstrn_KaTSXR_r_G_TM1_ToConstrn_rt_Array_Float_126_73:0, KaTSXR_r_G_TM1_ToConstrn_KaTSXR_r_G_TM1_ToConstrn_rt_Array_Float_126_74:0, KaTSXR_r_G_TM1_ToConstrn_KaTSXR_r_G_TM1_ToConstrn_rt_Array_Float_126_75:0, KaTSXR_r_G_TM1_ToConstrn_KaTSXR_r_G_TM1_ToConstrn_rt_Array_Float_126_76:0, KaTSXR_r_G_TM1_ToConstrn_KaTSXR_r_G_TM1_ToConstrn_rt_Array_Float_126_77:0, KaTSXR_r_G_TM1_ToConstrn_KaTSXR_r_G_TM1_ToConstrn_rt_Array_Float_126_78:0, KaTSXR_r_G_TM1_ToConstrn_KaTSXR_r_G_TM1_ToConstrn_rt_Array_Float_126_79:0, KaTSXR_r_G_TM1_ToConstrn_KaTSXR_r_G_TM1_ToConstrn_rt_Array_Float_126_80:0, KaTSXR_r_G_TM1_ToConstrn_KaTSXR_r_G_TM1_ToConstrn_rt_Array_Float_126_81:0, KaTSXR_r_G_TM1_ToConstrn_KaTSXR_r_G_TM1_ToConstrn_rt_Array_Float_126_82:0, KaTSXR_r_G_TM1_ToConstrn_KaTSXR_r_G_TM1_ToConstrn_rt_Array_Float_126_83:0, KaTSXR_r_G_TM1_ToConstrn_KaTSXR_r_G_TM1_ToConstrn_rt_Array_Float_126_84:0, KaTSXR_r_G_TM1_ToConstrn_KaTSXR_r_G_TM1_ToConstrn_rt_Array_Float_126_85:0, KaTSXR_r_G_TM1_ToConstrn_KaTSXR_r_G_TM1_ToConstrn_rt_Array_Float_126_86:0, KaTSXR_r_G_TM1_ToConstrn_KaTSXR_r_G_TM1_ToConstrn_rt_Array_Float_126_87:0, KaTSXR_r_G_TM1_ToConstrn_KaTSXR_r_G_TM1_ToConstrn_rt_Array_Float_126_88:0, KaTSXR_r_G_TM1_ToConstrn_KaTSXR_r_G_TM1_ToConstrn_rt_Array_Float_126_89:0, KaTSXR_r_G_TM1_ToConstrn_KaTSXR_r_G_TM1_ToConstrn_rt_Array_Float_126_90:0, KaTSXR_r_G_TM1_ToConstrn_KaTSXR_r_G_TM1_ToConstrn_rt_Array_Float_126_91:0, KaTSXR_r_G_TM1_ToConstrn_KaTSXR_r_G_TM1_ToConstrn_rt_Array_Float_126_92:0, KaTSXR_r_G_TM1_ToConstrn_KaTSXR_r_G_TM1_ToConstrn_rt_Array_Float_126_93:0, KaTSXR_r_G_TM1_ToConstrn_KaTSXR_r_G_TM1_ToConstrn_rt_Array_Float_126_94:0, KaTSXR_r_G_TM1_ToConstrn_KaTSXR_r_G_TM1_ToConstrn_rt_Array_Float_126_95:0, KaTSXR_r_G_TM1_ToConstrn_KaTSXR_r_G_TM1_ToConstrn_rt_Array_Float_126_96:0, KaTSXR_r_G_TM1_ToConstrn_KaTSXR_r_G_TM1_ToConstrn_rt_Array_Float_126_97:0, KaTSXR_r_G_TM1_ToConstrn_KaTSXR_r_G_TM1_ToConstrn_rt_Array_Float_126_98:0, KaTSXR_r_G_TM1_ToConstrn_KaTSXR_r_G_TM1_ToConstrn_rt_Array_Float_126_99:0, KaTSXR_r_G_TM1_ToConstrn_KaTSXR_r_G_TM1_ToConstrn_rt_Array_Float_126_100:0, KaTSXR_r_G_TM1_ToConstrn_KaTSXR_r_G_TM1_ToConstrn_rt_Array_Float_126_101:0, KaTSXR_r_G_TM1_ToConstrn_KaTSXR_r_G_TM1_ToConstrn_rt_Array_Float_126_102:0, KaTSXR_r_G_TM1_ToConstrn_KaTSXR_r_G_TM1_ToConstrn_rt_Array_Float_126_103:0, KaTSXR_r_G_TM1_ToConstrn_KaTSXR_r_G_TM1_ToConstrn_rt_Array_Float_126_104:0, KaTSXR_r_G_TM1_ToConstrn_KaTSXR_r_G_TM1_ToConstrn_rt_Array_Float_126_105:0, KaTSXR_r_G_TM1_ToConstrn_KaTSXR_r_G_TM1_ToConstrn_rt_Array_Float_126_106:0, KaTSXR_r_G_TM1_ToConstrn_KaTSXR_r_G_TM1_ToConstrn_rt_Array_Float_126_107:0, KaTSXR_r_G_TM1_ToConstrn_KaTSXR_r_G_TM1_ToConstrn_rt_Array_Float_126_108:0, KaTSXR_r_G_TM1_ToConstrn_KaTSXR_r_G_TM1_ToConstrn_rt_Array_Float_126_109:0, KaTSXR_r_G_TM1_ToConstrn_KaTSXR_r_G_TM1_ToConstrn_rt_Array_Float_126_110:0, KaTSXR_r_G_TM1_ToConstrn_KaTSXR_r_G_TM1_ToConstrn_rt_Array_Float_126_111:0, KaTSXR_r_G_TM1_ToConstrn_KaTSXR_r_G_TM1_ToConstrn_rt_Array_Float_126_112:0, KaTSXR_r_G_TM1_ToConstrn_KaTSXR_r_G_TM1_ToConstrn_rt_Array_Float_126_113:0, KaTSXR_r_G_TM1_ToConstrn_KaTSXR_r_G_TM1_ToConstrn_rt_Array_Float_126_114:0, KaTSXR_r_G_TM1_ToConstrn_KaTSXR_r_G_TM1_ToConstrn_rt_Array_Float_126_115:0, KaTSXR_r_G_TM1_ToConstrn_KaTSXR_r_G_TM1_ToConstrn_rt_Array_Float_126_116:0, KaTSXR_r_G_TM1_ToConstrn_KaTSXR_r_G_TM1_ToConstrn_rt_Array_Float_126_117:0, KaTSXR_r_G_TM1_ToConstrn_KaTSXR_r_G_TM1_ToConstrn_rt_Array_Float_126_118:0, KaTSXR_r_G_TM1_ToConstrn_KaTSXR_r_G_TM1_ToConstrn_rt_Array_Float_126_119:0, KaTSXR_r_G_TM1_ToConstrn_KaTSXR_r_G_TM1_ToConstrn_rt_Array_Float_126_120:0, KaTSXR_r_G_TM1_ToConstrn_KaTSXR_r_G_TM1_ToConstrn_rt_Array_Float_126_121:0, KaTSXR_r_G_TM1_ToConstrn_KaTSXR_r_G_TM1_ToConstrn_rt_Array_Float_126_122:0, KaTSXR_r_G_TM1_ToConstrn_KaTSXR_r_G_TM1_ToConstrn_rt_Array_Float_126_123:0, KaTSXR_r_G_TM1_ToConstrn_KaTSXR_r_G_TM1_ToConstrn_rt_Array_Float_126_124:0, KaTSXR_r_G_TM1_ToConstrn_KaTSXR_r_G_TM1_ToConstrn_rt_Array_Float_126_125:0, KaTSXR_r_G_TM1_ToConstrn_KaTSXR_r_G_TM1_ToConstrn_rt_Array_Float_126_126:0], parameter=KaTSXR_r_G_TM1_ToConstrn}, required-interface=KaTSXR_r_G_TM1_ToConstrn
      KaTSXR_r_MA_NaCalcEqnMtrx: parameter-require-com-spec{init-value=KaTSXR_r_MA_NaCalcEqnMtrx_KaTSXR_r_MA_NaCalcEqnMtrx:[KaTSXR_r_MA_NaCalcEqnMtrx_KaTSXR_r_MA_NaCalcEqnMtrx_rt_Array_Float_27_1:0, KaTSXR_r_MA_NaCalcEqnMtrx_KaTSXR_r_MA_NaCalcEqnMtrx_rt_Array_Float_27_2:0, KaTSXR_r_MA_NaCalcEqnMtrx_KaTSXR_r_MA_NaCalcEqnMtrx_rt_Array_Float_27_3:0, KaTSXR_r_MA_NaCalcEqnMtrx_KaTSXR_r_MA_NaCalcEqnMtrx_rt_Array_Float_27_4:0, KaTSXR_r_MA_NaCalcEqnMtrx_KaTSXR_r_MA_NaCalcEqnMtrx_rt_Array_Float_27_5:0, KaTSXR_r_MA_NaCalcEqnMtrx_KaTSXR_r_MA_NaCalcEqnMtrx_rt_Array_Float_27_6:0, KaTSXR_r_MA_NaCalcEqnMtrx_KaTSXR_r_MA_NaCalcEqnMtrx_rt_Array_Float_27_7:0, KaTSXR_r_MA_NaCalcEqnMtrx_KaTSXR_r_MA_NaCalcEqnMtrx_rt_Array_Float_27_8:0, KaTSXR_r_MA_NaCalcEqnMtrx_KaTSXR_r_MA_NaCalcEqnMtrx_rt_Array_Float_27_9:0, KaTSXR_r_MA_NaCalcEqnMtrx_KaTSXR_r_MA_NaCalcEqnMtrx_rt_Array_Float_27_10:0, KaTSXR_r_MA_NaCalcEqnMtrx_KaTSXR_r_MA_NaCalcEqnMtrx_rt_Array_Float_27_11:0, KaTSXR_r_MA_NaCalcEqnMtrx_KaTSXR_r_MA_NaCalcEqnMtrx_rt_Array_Float_27_12:0, KaTSXR_r_MA_NaCalcEqnMtrx_KaTSXR_r_MA_NaCalcEqnMtrx_rt_Array_Float_27_13:0, KaTSXR_r_MA_NaCalcEqnMtrx_KaTSXR_r_MA_NaCalcEqnMtrx_rt_Array_Float_27_14:0, KaTSXR_r_MA_NaCalcEqnMtrx_KaTSXR_r_MA_NaCalcEqnMtrx_rt_Array_Float_27_15:0, KaTSXR_r_MA_NaCalcEqnMtrx_KaTSXR_r_MA_NaCalcEqnMtrx_rt_Array_Float_27_16:0, KaTSXR_r_MA_NaCalcEqnMtrx_KaTSXR_r_MA_NaCalcEqnMtrx_rt_Array_Float_27_17:0, KaTSXR_r_MA_NaCalcEqnMtrx_KaTSXR_r_MA_NaCalcEqnMtrx_rt_Array_Float_27_18:0, KaTSXR_r_MA_NaCalcEqnMtrx_KaTSXR_r_MA_NaCalcEqnMtrx_rt_Array_Float_27_19:0, KaTSXR_r_MA_NaCalcEqnMtrx_KaTSXR_r_MA_NaCalcEqnMtrx_rt_Array_Float_27_20:0, KaTSXR_r_MA_NaCalcEqnMtrx_KaTSXR_r_MA_NaCalcEqnMtrx_rt_Array_Float_27_21:0, KaTSXR_r_MA_NaCalcEqnMtrx_KaTSXR_r_MA_NaCalcEqnMtrx_rt_Array_Float_27_22:0, KaTSXR_r_MA_NaCalcEqnMtrx_KaTSXR_r_MA_NaCalcEqnMtrx_rt_Array_Float_27_23:0, KaTSXR_r_MA_NaCalcEqnMtrx_KaTSXR_r_MA_NaCalcEqnMtrx_rt_Array_Float_27_24:0, KaTSXR_r_MA_NaCalcEqnMtrx_KaTSXR_r_MA_NaCalcEqnMtrx_rt_Array_Float_27_25:0, KaTSXR_r_MA_NaCalcEqnMtrx_KaTSXR_r_MA_NaCalcEqnMtrx_rt_Array_Float_27_26:0, KaTSXR_r_MA_NaCalcEqnMtrx_KaTSXR_r_MA_NaCalcEqnMtrx_rt_Array_Float_27_27:0], parameter=KaTSXR_r_MA_NaCalcEqnMtrx}, required-interface=KaTSXR_r_MA_NaCalcEqnMtrx
      KaTSXR_r_MA_NbCalcEqnMtrx: parameter-require-com-spec{init-value=KaTSXR_r_MA_NbCalcEqnMtrx_KaTSXR_r_MA_NbCalcEqnMtrx:[KaTSXR_r_MA_NbCalcEqnMtrx_KaTSXR_r_MA_NbCalcEqnMtrx_rt_Array_Float_27_1:0, KaTSXR_r_MA_NbCalcEqnMtrx_KaTSXR_r_MA_NbCalcEqnMtrx_rt_Array_Float_27_2:0, KaTSXR_r_MA_NbCalcEqnMtrx_KaTSXR_r_MA_NbCalcEqnMtrx_rt_Array_Float_27_3:0, KaTSXR_r_MA_NbCalcEqnMtrx_KaTSXR_r_MA_NbCalcEqnMtrx_rt_Array_Float_27_4:0, KaTSXR_r_MA_NbCalcEqnMtrx_KaTSXR_r_MA_NbCalcEqnMtrx_rt_Array_Float_27_5:0, KaTSXR_r_MA_NbCalcEqnMtrx_KaTSXR_r_MA_NbCalcEqnMtrx_rt_Array_Float_27_6:0, KaTSXR_r_MA_NbCalcEqnMtrx_KaTSXR_r_MA_NbCalcEqnMtrx_rt_Array_Float_27_7:0, KaTSXR_r_MA_NbCalcEqnMtrx_KaTSXR_r_MA_NbCalcEqnMtrx_rt_Array_Float_27_8:0, KaTSXR_r_MA_NbCalcEqnMtrx_KaTSXR_r_MA_NbCalcEqnMtrx_rt_Array_Float_27_9:0, KaTSXR_r_MA_NbCalcEqnMtrx_KaTSXR_r_MA_NbCalcEqnMtrx_rt_Array_Float_27_10:0, KaTSXR_r_MA_NbCalcEqnMtrx_KaTSXR_r_MA_NbCalcEqnMtrx_rt_Array_Float_27_11:0, KaTSXR_r_MA_NbCalcEqnMtrx_KaTSXR_r_MA_NbCalcEqnMtrx_rt_Array_Float_27_12:0, KaTSXR_r_MA_NbCalcEqnMtrx_KaTSXR_r_MA_NbCalcEqnMtrx_rt_Array_Float_27_13:0, KaTSXR_r_MA_NbCalcEqnMtrx_KaTSXR_r_MA_NbCalcEqnMtrx_rt_Array_Float_27_14:0, KaTSXR_r_MA_NbCalcEqnMtrx_KaTSXR_r_MA_NbCalcEqnMtrx_rt_Array_Float_27_15:0, KaTSXR_r_MA_NbCalcEqnMtrx_KaTSXR_r_MA_NbCalcEqnMtrx_rt_Array_Float_27_16:0, KaTSXR_r_MA_NbCalcEqnMtrx_KaTSXR_r_MA_NbCalcEqnMtrx_rt_Array_Float_27_17:0, KaTSXR_r_MA_NbCalcEqnMtrx_KaTSXR_r_MA_NbCalcEqnMtrx_rt_Array_Float_27_18:0, KaTSXR_r_MA_NbCalcEqnMtrx_KaTSXR_r_MA_NbCalcEqnMtrx_rt_Array_Float_27_19:0, KaTSXR_r_MA_NbCalcEqnMtrx_KaTSXR_r_MA_NbCalcEqnMtrx_rt_Array_Float_27_20:0, KaTSXR_r_MA_NbCalcEqnMtrx_KaTSXR_r_MA_NbCalcEqnMtrx_rt_Array_Float_27_21:0, KaTSXR_r_MA_NbCalcEqnMtrx_KaTSXR_r_MA_NbCalcEqnMtrx_rt_Array_Float_27_22:0, KaTSXR_r_MA_NbCalcEqnMtrx_KaTSXR_r_MA_NbCalcEqnMtrx_rt_Array_Float_27_23:0, KaTSXR_r_MA_NbCalcEqnMtrx_KaTSXR_r_MA_NbCalcEqnMtrx_rt_Array_Float_27_24:0, KaTSXR_r_MA_NbCalcEqnMtrx_KaTSXR_r_MA_NbCalcEqnMtrx_rt_Array_Float_27_25:0, KaTSXR_r_MA_NbCalcEqnMtrx_KaTSXR_r_MA_NbCalcEqnMtrx_rt_Array_Float_27_26:0, KaTSXR_r_MA_NbCalcEqnMtrx_KaTSXR_r_MA_NbCalcEqnMtrx_rt_Array_Float_27_27:0], parameter=KaTSXR_r_MA_NbCalcEqnMtrx}, required-interface=KaTSXR_r_MA_NbCalcEqnMtrx
      KaTSXR_r_MA_Nc1CalcEqnMtrx: parameter-require-com-spec{init-value=KaTSXR_r_MA_Nc1CalcEqnMtrx_KaTSXR_r_MA_Nc1CalcEqnMtrx:[KaTSXR_r_MA_Nc1CalcEqnMtrx_KaTSXR_r_MA_Nc1CalcEqnMtrx_rt_Array_Float_27_1:0, KaTSXR_r_MA_Nc1CalcEqnMtrx_KaTSXR_r_MA_Nc1CalcEqnMtrx_rt_Array_Float_27_2:0, KaTSXR_r_MA_Nc1CalcEqnMtrx_KaTSXR_r_MA_Nc1CalcEqnMtrx_rt_Array_Float_27_3:0, KaTSXR_r_MA_Nc1CalcEqnMtrx_KaTSXR_r_MA_Nc1CalcEqnMtrx_rt_Array_Float_27_4:0, KaTSXR_r_MA_Nc1CalcEqnMtrx_KaTSXR_r_MA_Nc1CalcEqnMtrx_rt_Array_Float_27_5:0, KaTSXR_r_MA_Nc1CalcEqnMtrx_KaTSXR_r_MA_Nc1CalcEqnMtrx_rt_Array_Float_27_6:0, KaTSXR_r_MA_Nc1CalcEqnMtrx_KaTSXR_r_MA_Nc1CalcEqnMtrx_rt_Array_Float_27_7:0, KaTSXR_r_MA_Nc1CalcEqnMtrx_KaTSXR_r_MA_Nc1CalcEqnMtrx_rt_Array_Float_27_8:0, KaTSXR_r_MA_Nc1CalcEqnMtrx_KaTSXR_r_MA_Nc1CalcEqnMtrx_rt_Array_Float_27_9:0, KaTSXR_r_MA_Nc1CalcEqnMtrx_KaTSXR_r_MA_Nc1CalcEqnMtrx_rt_Array_Float_27_10:0, KaTSXR_r_MA_Nc1CalcEqnMtrx_KaTSXR_r_MA_Nc1CalcEqnMtrx_rt_Array_Float_27_11:0, KaTSXR_r_MA_Nc1CalcEqnMtrx_KaTSXR_r_MA_Nc1CalcEqnMtrx_rt_Array_Float_27_12:0, KaTSXR_r_MA_Nc1CalcEqnMtrx_KaTSXR_r_MA_Nc1CalcEqnMtrx_rt_Array_Float_27_13:0, KaTSXR_r_MA_Nc1CalcEqnMtrx_KaTSXR_r_MA_Nc1CalcEqnMtrx_rt_Array_Float_27_14:0, KaTSXR_r_MA_Nc1CalcEqnMtrx_KaTSXR_r_MA_Nc1CalcEqnMtrx_rt_Array_Float_27_15:0, KaTSXR_r_MA_Nc1CalcEqnMtrx_KaTSXR_r_MA_Nc1CalcEqnMtrx_rt_Array_Float_27_16:0, KaTSXR_r_MA_Nc1CalcEqnMtrx_KaTSXR_r_MA_Nc1CalcEqnMtrx_rt_Array_Float_27_17:0, KaTSXR_r_MA_Nc1CalcEqnMtrx_KaTSXR_r_MA_Nc1CalcEqnMtrx_rt_Array_Float_27_18:0, KaTSXR_r_MA_Nc1CalcEqnMtrx_KaTSXR_r_MA_Nc1CalcEqnMtrx_rt_Array_Float_27_19:0, KaTSXR_r_MA_Nc1CalcEqnMtrx_KaTSXR_r_MA_Nc1CalcEqnMtrx_rt_Array_Float_27_20:0, KaTSXR_r_MA_Nc1CalcEqnMtrx_KaTSXR_r_MA_Nc1CalcEqnMtrx_rt_Array_Float_27_21:0, KaTSXR_r_MA_Nc1CalcEqnMtrx_KaTSXR_r_MA_Nc1CalcEqnMtrx_rt_Array_Float_27_22:0, KaTSXR_r_MA_Nc1CalcEqnMtrx_KaTSXR_r_MA_Nc1CalcEqnMtrx_rt_Array_Float_27_23:0, KaTSXR_r_MA_Nc1CalcEqnMtrx_KaTSXR_r_MA_Nc1CalcEqnMtrx_rt_Array_Float_27_24:0, KaTSXR_r_MA_Nc1CalcEqnMtrx_KaTSXR_r_MA_Nc1CalcEqnMtrx_rt_Array_Float_27_25:0, KaTSXR_r_MA_Nc1CalcEqnMtrx_KaTSXR_r_MA_Nc1CalcEqnMtrx_rt_Array_Float_27_26:0, KaTSXR_r_MA_Nc1CalcEqnMtrx_KaTSXR_r_MA_Nc1CalcEqnMtrx_rt_Array_Float_27_27:0], parameter=KaTSXR_r_MA_Nc1CalcEqnMtrx}, required-interface=KaTSXR_r_MA_Nc1CalcEqnMtrx
      KaTSXR_r_MA_NcCalcEqnMtrx: parameter-require-com-spec{init-value=KaTSXR_r_MA_NcCalcEqnMtrx_KaTSXR_r_MA_NcCalcEqnMtrx:[KaTSXR_r_MA_NcCalcEqnMtrx_KaTSXR_r_MA_NcCalcEqnMtrx_rt_Array_Float_27_1:0, KaTSXR_r_MA_NcCalcEqnMtrx_KaTSXR_r_MA_NcCalcEqnMtrx_rt_Array_Float_27_2:0, KaTSXR_r_MA_NcCalcEqnMtrx_KaTSXR_r_MA_NcCalcEqnMtrx_rt_Array_Float_27_3:0, KaTSXR_r_MA_NcCalcEqnMtrx_KaTSXR_r_MA_NcCalcEqnMtrx_rt_Array_Float_27_4:0, KaTSXR_r_MA_NcCalcEqnMtrx_KaTSXR_r_MA_NcCalcEqnMtrx_rt_Array_Float_27_5:0, KaTSXR_r_MA_NcCalcEqnMtrx_KaTSXR_r_MA_NcCalcEqnMtrx_rt_Array_Float_27_6:0, KaTSXR_r_MA_NcCalcEqnMtrx_KaTSXR_r_MA_NcCalcEqnMtrx_rt_Array_Float_27_7:0, KaTSXR_r_MA_NcCalcEqnMtrx_KaTSXR_r_MA_NcCalcEqnMtrx_rt_Array_Float_27_8:0, KaTSXR_r_MA_NcCalcEqnMtrx_KaTSXR_r_MA_NcCalcEqnMtrx_rt_Array_Float_27_9:0, KaTSXR_r_MA_NcCalcEqnMtrx_KaTSXR_r_MA_NcCalcEqnMtrx_rt_Array_Float_27_10:0, KaTSXR_r_MA_NcCalcEqnMtrx_KaTSXR_r_MA_NcCalcEqnMtrx_rt_Array_Float_27_11:0, KaTSXR_r_MA_NcCalcEqnMtrx_KaTSXR_r_MA_NcCalcEqnMtrx_rt_Array_Float_27_12:0, KaTSXR_r_MA_NcCalcEqnMtrx_KaTSXR_r_MA_NcCalcEqnMtrx_rt_Array_Float_27_13:0, KaTSXR_r_MA_NcCalcEqnMtrx_KaTSXR_r_MA_NcCalcEqnMtrx_rt_Array_Float_27_14:0, KaTSXR_r_MA_NcCalcEqnMtrx_KaTSXR_r_MA_NcCalcEqnMtrx_rt_Array_Float_27_15:0, KaTSXR_r_MA_NcCalcEqnMtrx_KaTSXR_r_MA_NcCalcEqnMtrx_rt_Array_Float_27_16:0, KaTSXR_r_MA_NcCalcEqnMtrx_KaTSXR_r_MA_NcCalcEqnMtrx_rt_Array_Float_27_17:0, KaTSXR_r_MA_NcCalcEqnMtrx_KaTSXR_r_MA_NcCalcEqnMtrx_rt_Array_Float_27_18:0, KaTSXR_r_MA_NcCalcEqnMtrx_KaTSXR_r_MA_NcCalcEqnMtrx_rt_Array_Float_27_19:0, KaTSXR_r_MA_NcCalcEqnMtrx_KaTSXR_r_MA_NcCalcEqnMtrx_rt_Array_Float_27_20:0, KaTSXR_r_MA_NcCalcEqnMtrx_KaTSXR_r_MA_NcCalcEqnMtrx_rt_Array_Float_27_21:0, KaTSXR_r_MA_NcCalcEqnMtrx_KaTSXR_r_MA_NcCalcEqnMtrx_rt_Array_Float_27_22:0, KaTSXR_r_MA_NcCalcEqnMtrx_KaTSXR_r_MA_NcCalcEqnMtrx_rt_Array_Float_27_23:0, KaTSXR_r_MA_NcCalcEqnMtrx_KaTSXR_r_MA_NcCalcEqnMtrx_rt_Array_Float_27_24:0, KaTSXR_r_MA_NcCalcEqnMtrx_KaTSXR_r_MA_NcCalcEqnMtrx_rt_Array_Float_27_25:0, KaTSXR_r_MA_NcCalcEqnMtrx_KaTSXR_r_MA_NcCalcEqnMtrx_rt_Array_Float_27_26:0, KaTSXR_r_MA_NcCalcEqnMtrx_KaTSXR_r_MA_NcCalcEqnMtrx_rt_Array_Float_27_27:0], parameter=KaTSXR_r_MA_NcCalcEqnMtrx}, required-interface=KaTSXR_r_MA_NcCalcEqnMtrx
      KaTSXR_r_MA_TM1_ToConstrn: parameter-require-com-spec{init-value=KaTSXR_r_MA_TM1_ToConstrn_KaTSXR_r_MA_TM1_ToConstrn:[KaTSXR_r_MA_TM1_ToConstrn_KaTSXR_r_MA_TM1_ToConstrn_rt_Array_Float_126_1:0, KaTSXR_r_MA_TM1_ToConstrn_KaTSXR_r_MA_TM1_ToConstrn_rt_Array_Float_126_2:0, KaTSXR_r_MA_TM1_ToConstrn_KaTSXR_r_MA_TM1_ToConstrn_rt_Array_Float_126_3:0, KaTSXR_r_MA_TM1_ToConstrn_KaTSXR_r_MA_TM1_ToConstrn_rt_Array_Float_126_4:0, KaTSXR_r_MA_TM1_ToConstrn_KaTSXR_r_MA_TM1_ToConstrn_rt_Array_Float_126_5:0, KaTSXR_r_MA_TM1_ToConstrn_KaTSXR_r_MA_TM1_ToConstrn_rt_Array_Float_126_6:0, KaTSXR_r_MA_TM1_ToConstrn_KaTSXR_r_MA_TM1_ToConstrn_rt_Array_Float_126_7:0, KaTSXR_r_MA_TM1_ToConstrn_KaTSXR_r_MA_TM1_ToConstrn_rt_Array_Float_126_8:0, KaTSXR_r_MA_TM1_ToConstrn_KaTSXR_r_MA_TM1_ToConstrn_rt_Array_Float_126_9:0, KaTSXR_r_MA_TM1_ToConstrn_KaTSXR_r_MA_TM1_ToConstrn_rt_Array_Float_126_10:0, KaTSXR_r_MA_TM1_ToConstrn_KaTSXR_r_MA_TM1_ToConstrn_rt_Array_Float_126_11:0, KaTSXR_r_MA_TM1_ToConstrn_KaTSXR_r_MA_TM1_ToConstrn_rt_Array_Float_126_12:0, KaTSXR_r_MA_TM1_ToConstrn_KaTSXR_r_MA_TM1_ToConstrn_rt_Array_Float_126_13:0, KaTSXR_r_MA_TM1_ToConstrn_KaTSXR_r_MA_TM1_ToConstrn_rt_Array_Float_126_14:0, KaTSXR_r_MA_TM1_ToConstrn_KaTSXR_r_MA_TM1_ToConstrn_rt_Array_Float_126_15:0, KaTSXR_r_MA_TM1_ToConstrn_KaTSXR_r_MA_TM1_ToConstrn_rt_Array_Float_126_16:0, KaTSXR_r_MA_TM1_ToConstrn_KaTSXR_r_MA_TM1_ToConstrn_rt_Array_Float_126_17:0, KaTSXR_r_MA_TM1_ToConstrn_KaTSXR_r_MA_TM1_ToConstrn_rt_Array_Float_126_18:0, KaTSXR_r_MA_TM1_ToConstrn_KaTSXR_r_MA_TM1_ToConstrn_rt_Array_Float_126_19:0, KaTSXR_r_MA_TM1_ToConstrn_KaTSXR_r_MA_TM1_ToConstrn_rt_Array_Float_126_20:0, KaTSXR_r_MA_TM1_ToConstrn_KaTSXR_r_MA_TM1_ToConstrn_rt_Array_Float_126_21:0, KaTSXR_r_MA_TM1_ToConstrn_KaTSXR_r_MA_TM1_ToConstrn_rt_Array_Float_126_22:0, KaTSXR_r_MA_TM1_ToConstrn_KaTSXR_r_MA_TM1_ToConstrn_rt_Array_Float_126_23:0, KaTSXR_r_MA_TM1_ToConstrn_KaTSXR_r_MA_TM1_ToConstrn_rt_Array_Float_126_24:0, KaTSXR_r_MA_TM1_ToConstrn_KaTSXR_r_MA_TM1_ToConstrn_rt_Array_Float_126_25:0, KaTSXR_r_MA_TM1_ToConstrn_KaTSXR_r_MA_TM1_ToConstrn_rt_Array_Float_126_26:0, KaTSXR_r_MA_TM1_ToConstrn_KaTSXR_r_MA_TM1_ToConstrn_rt_Array_Float_126_27:0, KaTSXR_r_MA_TM1_ToConstrn_KaTSXR_r_MA_TM1_ToConstrn_rt_Array_Float_126_28:0, KaTSXR_r_MA_TM1_ToConstrn_KaTSXR_r_MA_TM1_ToConstrn_rt_Array_Float_126_29:0, KaTSXR_r_MA_TM1_ToConstrn_KaTSXR_r_MA_TM1_ToConstrn_rt_Array_Float_126_30:0, KaTSXR_r_MA_TM1_ToConstrn_KaTSXR_r_MA_TM1_ToConstrn_rt_Array_Float_126_31:0, KaTSXR_r_MA_TM1_ToConstrn_KaTSXR_r_MA_TM1_ToConstrn_rt_Array_Float_126_32:0, KaTSXR_r_MA_TM1_ToConstrn_KaTSXR_r_MA_TM1_ToConstrn_rt_Array_Float_126_33:0, KaTSXR_r_MA_TM1_ToConstrn_KaTSXR_r_MA_TM1_ToConstrn_rt_Array_Float_126_34:0, KaTSXR_r_MA_TM1_ToConstrn_KaTSXR_r_MA_TM1_ToConstrn_rt_Array_Float_126_35:0, KaTSXR_r_MA_TM1_ToConstrn_KaTSXR_r_MA_TM1_ToConstrn_rt_Array_Float_126_36:0, KaTSXR_r_MA_TM1_ToConstrn_KaTSXR_r_MA_TM1_ToConstrn_rt_Array_Float_126_37:0, KaTSXR_r_MA_TM1_ToConstrn_KaTSXR_r_MA_TM1_ToConstrn_rt_Array_Float_126_38:0, KaTSXR_r_MA_TM1_ToConstrn_KaTSXR_r_MA_TM1_ToConstrn_rt_Array_Float_126_39:0, KaTSXR_r_MA_TM1_ToConstrn_KaTSXR_r_MA_TM1_ToConstrn_rt_Array_Float_126_40:0, KaTSXR_r_MA_TM1_ToConstrn_KaTSXR_r_MA_TM1_ToConstrn_rt_Array_Float_126_41:0, KaTSXR_r_MA_TM1_ToConstrn_KaTSXR_r_MA_TM1_ToConstrn_rt_Array_Float_126_42:0, KaTSXR_r_MA_TM1_ToConstrn_KaTSXR_r_MA_TM1_ToConstrn_rt_Array_Float_126_43:0, KaTSXR_r_MA_TM1_ToConstrn_KaTSXR_r_MA_TM1_ToConstrn_rt_Array_Float_126_44:0, KaTSXR_r_MA_TM1_ToConstrn_KaTSXR_r_MA_TM1_ToConstrn_rt_Array_Float_126_45:0, KaTSXR_r_MA_TM1_ToConstrn_KaTSXR_r_MA_TM1_ToConstrn_rt_Array_Float_126_46:0, KaTSXR_r_MA_TM1_ToConstrn_KaTSXR_r_MA_TM1_ToConstrn_rt_Array_Float_126_47:0, KaTSXR_r_MA_TM1_ToConstrn_KaTSXR_r_MA_TM1_ToConstrn_rt_Array_Float_126_48:0, KaTSXR_r_MA_TM1_ToConstrn_KaTSXR_r_MA_TM1_ToConstrn_rt_Array_Float_126_49:0, KaTSXR_r_MA_TM1_ToConstrn_KaTSXR_r_MA_TM1_ToConstrn_rt_Array_Float_126_50:0, KaTSXR_r_MA_TM1_ToConstrn_KaTSXR_r_MA_TM1_ToConstrn_rt_Array_Float_126_51:0, KaTSXR_r_MA_TM1_ToConstrn_KaTSXR_r_MA_TM1_ToConstrn_rt_Array_Float_126_52:0, KaTSXR_r_MA_TM1_ToConstrn_KaTSXR_r_MA_TM1_ToConstrn_rt_Array_Float_126_53:0, KaTSXR_r_MA_TM1_ToConstrn_KaTSXR_r_MA_TM1_ToConstrn_rt_Array_Float_126_54:0, KaTSXR_r_MA_TM1_ToConstrn_KaTSXR_r_MA_TM1_ToConstrn_rt_Array_Float_126_55:0, KaTSXR_r_MA_TM1_ToConstrn_KaTSXR_r_MA_TM1_ToConstrn_rt_Array_Float_126_56:0, KaTSXR_r_MA_TM1_ToConstrn_KaTSXR_r_MA_TM1_ToConstrn_rt_Array_Float_126_57:0, KaTSXR_r_MA_TM1_ToConstrn_KaTSXR_r_MA_TM1_ToConstrn_rt_Array_Float_126_58:0, KaTSXR_r_MA_TM1_ToConstrn_KaTSXR_r_MA_TM1_ToConstrn_rt_Array_Float_126_59:0, KaTSXR_r_MA_TM1_ToConstrn_KaTSXR_r_MA_TM1_ToConstrn_rt_Array_Float_126_60:0, KaTSXR_r_MA_TM1_ToConstrn_KaTSXR_r_MA_TM1_ToConstrn_rt_Array_Float_126_61:0, KaTSXR_r_MA_TM1_ToConstrn_KaTSXR_r_MA_TM1_ToConstrn_rt_Array_Float_126_62:0, KaTSXR_r_MA_TM1_ToConstrn_KaTSXR_r_MA_TM1_ToConstrn_rt_Array_Float_126_63:0, KaTSXR_r_MA_TM1_ToConstrn_KaTSXR_r_MA_TM1_ToConstrn_rt_Array_Float_126_64:0, KaTSXR_r_MA_TM1_ToConstrn_KaTSXR_r_MA_TM1_ToConstrn_rt_Array_Float_126_65:0, KaTSXR_r_MA_TM1_ToConstrn_KaTSXR_r_MA_TM1_ToConstrn_rt_Array_Float_126_66:0, KaTSXR_r_MA_TM1_ToConstrn_KaTSXR_r_MA_TM1_ToConstrn_rt_Array_Float_126_67:0, KaTSXR_r_MA_TM1_ToConstrn_KaTSXR_r_MA_TM1_ToConstrn_rt_Array_Float_126_68:0, KaTSXR_r_MA_TM1_ToConstrn_KaTSXR_r_MA_TM1_ToConstrn_rt_Array_Float_126_69:0, KaTSXR_r_MA_TM1_ToConstrn_KaTSXR_r_MA_TM1_ToConstrn_rt_Array_Float_126_70:0, KaTSXR_r_MA_TM1_ToConstrn_KaTSXR_r_MA_TM1_ToConstrn_rt_Array_Float_126_71:0, KaTSXR_r_MA_TM1_ToConstrn_KaTSXR_r_MA_TM1_ToConstrn_rt_Array_Float_126_72:0, KaTSXR_r_MA_TM1_ToConstrn_KaTSXR_r_MA_TM1_ToConstrn_rt_Array_Float_126_73:0, KaTSXR_r_MA_TM1_ToConstrn_KaTSXR_r_MA_TM1_ToConstrn_rt_Array_Float_126_74:0, KaTSXR_r_MA_TM1_ToConstrn_KaTSXR_r_MA_TM1_ToConstrn_rt_Array_Float_126_75:0, KaTSXR_r_MA_TM1_ToConstrn_KaTSXR_r_MA_TM1_ToConstrn_rt_Array_Float_126_76:0, KaTSXR_r_MA_TM1_ToConstrn_KaTSXR_r_MA_TM1_ToConstrn_rt_Array_Float_126_77:0, KaTSXR_r_MA_TM1_ToConstrn_KaTSXR_r_MA_TM1_ToConstrn_rt_Array_Float_126_78:0, KaTSXR_r_MA_TM1_ToConstrn_KaTSXR_r_MA_TM1_ToConstrn_rt_Array_Float_126_79:0, KaTSXR_r_MA_TM1_ToConstrn_KaTSXR_r_MA_TM1_ToConstrn_rt_Array_Float_126_80:0, KaTSXR_r_MA_TM1_ToConstrn_KaTSXR_r_MA_TM1_ToConstrn_rt_Array_Float_126_81:0, KaTSXR_r_MA_TM1_ToConstrn_KaTSXR_r_MA_TM1_ToConstrn_rt_Array_Float_126_82:0, KaTSXR_r_MA_TM1_ToConstrn_KaTSXR_r_MA_TM1_ToConstrn_rt_Array_Float_126_83:0, KaTSXR_r_MA_TM1_ToConstrn_KaTSXR_r_MA_TM1_ToConstrn_rt_Array_Float_126_84:0, KaTSXR_r_MA_TM1_ToConstrn_KaTSXR_r_MA_TM1_ToConstrn_rt_Array_Float_126_85:0, KaTSXR_r_MA_TM1_ToConstrn_KaTSXR_r_MA_TM1_ToConstrn_rt_Array_Float_126_86:0, KaTSXR_r_MA_TM1_ToConstrn_KaTSXR_r_MA_TM1_ToConstrn_rt_Array_Float_126_87:0, KaTSXR_r_MA_TM1_ToConstrn_KaTSXR_r_MA_TM1_ToConstrn_rt_Array_Float_126_88:0, KaTSXR_r_MA_TM1_ToConstrn_KaTSXR_r_MA_TM1_ToConstrn_rt_Array_Float_126_89:0, KaTSXR_r_MA_TM1_ToConstrn_KaTSXR_r_MA_TM1_ToConstrn_rt_Array_Float_126_90:0, KaTSXR_r_MA_TM1_ToConstrn_KaTSXR_r_MA_TM1_ToConstrn_rt_Array_Float_126_91:0, KaTSXR_r_MA_TM1_ToConstrn_KaTSXR_r_MA_TM1_ToConstrn_rt_Array_Float_126_92:0, KaTSXR_r_MA_TM1_ToConstrn_KaTSXR_r_MA_TM1_ToConstrn_rt_Array_Float_126_93:0, KaTSXR_r_MA_TM1_ToConstrn_KaTSXR_r_MA_TM1_ToConstrn_rt_Array_Float_126_94:0, KaTSXR_r_MA_TM1_ToConstrn_KaTSXR_r_MA_TM1_ToConstrn_rt_Array_Float_126_95:0, KaTSXR_r_MA_TM1_ToConstrn_KaTSXR_r_MA_TM1_ToConstrn_rt_Array_Float_126_96:0, KaTSXR_r_MA_TM1_ToConstrn_KaTSXR_r_MA_TM1_ToConstrn_rt_Array_Float_126_97:0, KaTSXR_r_MA_TM1_ToConstrn_KaTSXR_r_MA_TM1_ToConstrn_rt_Array_Float_126_98:0, KaTSXR_r_MA_TM1_ToConstrn_KaTSXR_r_MA_TM1_ToConstrn_rt_Array_Float_126_99:0, KaTSXR_r_MA_TM1_ToConstrn_KaTSXR_r_MA_TM1_ToConstrn_rt_Array_Float_126_100:0, KaTSXR_r_MA_TM1_ToConstrn_KaTSXR_r_MA_TM1_ToConstrn_rt_Array_Float_126_101:0, KaTSXR_r_MA_TM1_ToConstrn_KaTSXR_r_MA_TM1_ToConstrn_rt_Array_Float_126_102:0, KaTSXR_r_MA_TM1_ToConstrn_KaTSXR_r_MA_TM1_ToConstrn_rt_Array_Float_126_103:0, KaTSXR_r_MA_TM1_ToConstrn_KaTSXR_r_MA_TM1_ToConstrn_rt_Array_Float_126_104:0, KaTSXR_r_MA_TM1_ToConstrn_KaTSXR_r_MA_TM1_ToConstrn_rt_Array_Float_126_105:0, KaTSXR_r_MA_TM1_ToConstrn_KaTSXR_r_MA_TM1_ToConstrn_rt_Array_Float_126_106:0, KaTSXR_r_MA_TM1_ToConstrn_KaTSXR_r_MA_TM1_ToConstrn_rt_Array_Float_126_107:0, KaTSXR_r_MA_TM1_ToConstrn_KaTSXR_r_MA_TM1_ToConstrn_rt_Array_Float_126_108:0, KaTSXR_r_MA_TM1_ToConstrn_KaTSXR_r_MA_TM1_ToConstrn_rt_Array_Float_126_109:0, KaTSXR_r_MA_TM1_ToConstrn_KaTSXR_r_MA_TM1_ToConstrn_rt_Array_Float_126_110:0, KaTSXR_r_MA_TM1_ToConstrn_KaTSXR_r_MA_TM1_ToConstrn_rt_Array_Float_126_111:0, KaTSXR_r_MA_TM1_ToConstrn_KaTSXR_r_MA_TM1_ToConstrn_rt_Array_Float_126_112:0, KaTSXR_r_MA_TM1_ToConstrn_KaTSXR_r_MA_TM1_ToConstrn_rt_Array_Float_126_113:0, KaTSXR_r_MA_TM1_ToConstrn_KaTSXR_r_MA_TM1_ToConstrn_rt_Array_Float_126_114:0, KaTSXR_r_MA_TM1_ToConstrn_KaTSXR_r_MA_TM1_ToConstrn_rt_Array_Float_126_115:0, KaTSXR_r_MA_TM1_ToConstrn_KaTSXR_r_MA_TM1_ToConstrn_rt_Array_Float_126_116:0, KaTSXR_r_MA_TM1_ToConstrn_KaTSXR_r_MA_TM1_ToConstrn_rt_Array_Float_126_117:0, KaTSXR_r_MA_TM1_ToConstrn_KaTSXR_r_MA_TM1_ToConstrn_rt_Array_Float_126_118:0, KaTSXR_r_MA_TM1_ToConstrn_KaTSXR_r_MA_TM1_ToConstrn_rt_Array_Float_126_119:0, KaTSXR_r_MA_TM1_ToConstrn_KaTSXR_r_MA_TM1_ToConstrn_rt_Array_Float_126_120:0, KaTSXR_r_MA_TM1_ToConstrn_KaTSXR_r_MA_TM1_ToConstrn_rt_Array_Float_126_121:0, KaTSXR_r_MA_TM1_ToConstrn_KaTSXR_r_MA_TM1_ToConstrn_rt_Array_Float_126_122:0, KaTSXR_r_MA_TM1_ToConstrn_KaTSXR_r_MA_TM1_ToConstrn_rt_Array_Float_126_123:0, KaTSXR_r_MA_TM1_ToConstrn_KaTSXR_r_MA_TM1_ToConstrn_rt_Array_Float_126_124:0, KaTSXR_r_MA_TM1_ToConstrn_KaTSXR_r_MA_TM1_ToConstrn_rt_Array_Float_126_125:0, KaTSXR_r_MA_TM1_ToConstrn_KaTSXR_r_MA_TM1_ToConstrn_rt_Array_Float_126_126:0], parameter=KaTSXR_r_MA_TM1_ToConstrn}, required-interface=KaTSXR_r_MA_TM1_ToConstrn
      KaTSXR_r_MB_NaCalcEqnMtrx: parameter-require-com-spec{init-value=KaTSXR_r_MB_NaCalcEqnMtrx_KaTSXR_r_MB_NaCalcEqnMtrx:[KaTSXR_r_MB_NaCalcEqnMtrx_KaTSXR_r_MB_NaCalcEqnMtrx_rt_Array_Float_27_1:0, KaTSXR_r_MB_NaCalcEqnMtrx_KaTSXR_r_MB_NaCalcEqnMtrx_rt_Array_Float_27_2:0, KaTSXR_r_MB_NaCalcEqnMtrx_KaTSXR_r_MB_NaCalcEqnMtrx_rt_Array_Float_27_3:0, KaTSXR_r_MB_NaCalcEqnMtrx_KaTSXR_r_MB_NaCalcEqnMtrx_rt_Array_Float_27_4:0, KaTSXR_r_MB_NaCalcEqnMtrx_KaTSXR_r_MB_NaCalcEqnMtrx_rt_Array_Float_27_5:0, KaTSXR_r_MB_NaCalcEqnMtrx_KaTSXR_r_MB_NaCalcEqnMtrx_rt_Array_Float_27_6:0, KaTSXR_r_MB_NaCalcEqnMtrx_KaTSXR_r_MB_NaCalcEqnMtrx_rt_Array_Float_27_7:0, KaTSXR_r_MB_NaCalcEqnMtrx_KaTSXR_r_MB_NaCalcEqnMtrx_rt_Array_Float_27_8:0, KaTSXR_r_MB_NaCalcEqnMtrx_KaTSXR_r_MB_NaCalcEqnMtrx_rt_Array_Float_27_9:0, KaTSXR_r_MB_NaCalcEqnMtrx_KaTSXR_r_MB_NaCalcEqnMtrx_rt_Array_Float_27_10:0, KaTSXR_r_MB_NaCalcEqnMtrx_KaTSXR_r_MB_NaCalcEqnMtrx_rt_Array_Float_27_11:0, KaTSXR_r_MB_NaCalcEqnMtrx_KaTSXR_r_MB_NaCalcEqnMtrx_rt_Array_Float_27_12:0, KaTSXR_r_MB_NaCalcEqnMtrx_KaTSXR_r_MB_NaCalcEqnMtrx_rt_Array_Float_27_13:0, KaTSXR_r_MB_NaCalcEqnMtrx_KaTSXR_r_MB_NaCalcEqnMtrx_rt_Array_Float_27_14:0, KaTSXR_r_MB_NaCalcEqnMtrx_KaTSXR_r_MB_NaCalcEqnMtrx_rt_Array_Float_27_15:0, KaTSXR_r_MB_NaCalcEqnMtrx_KaTSXR_r_MB_NaCalcEqnMtrx_rt_Array_Float_27_16:0, KaTSXR_r_MB_NaCalcEqnMtrx_KaTSXR_r_MB_NaCalcEqnMtrx_rt_Array_Float_27_17:0, KaTSXR_r_MB_NaCalcEqnMtrx_KaTSXR_r_MB_NaCalcEqnMtrx_rt_Array_Float_27_18:0, KaTSXR_r_MB_NaCalcEqnMtrx_KaTSXR_r_MB_NaCalcEqnMtrx_rt_Array_Float_27_19:0, KaTSXR_r_MB_NaCalcEqnMtrx_KaTSXR_r_MB_NaCalcEqnMtrx_rt_Array_Float_27_20:0, KaTSXR_r_MB_NaCalcEqnMtrx_KaTSXR_r_MB_NaCalcEqnMtrx_rt_Array_Float_27_21:0, KaTSXR_r_MB_NaCalcEqnMtrx_KaTSXR_r_MB_NaCalcEqnMtrx_rt_Array_Float_27_22:0, KaTSXR_r_MB_NaCalcEqnMtrx_KaTSXR_r_MB_NaCalcEqnMtrx_rt_Array_Float_27_23:0, KaTSXR_r_MB_NaCalcEqnMtrx_KaTSXR_r_MB_NaCalcEqnMtrx_rt_Array_Float_27_24:0, KaTSXR_r_MB_NaCalcEqnMtrx_KaTSXR_r_MB_NaCalcEqnMtrx_rt_Array_Float_27_25:0, KaTSXR_r_MB_NaCalcEqnMtrx_KaTSXR_r_MB_NaCalcEqnMtrx_rt_Array_Float_27_26:0, KaTSXR_r_MB_NaCalcEqnMtrx_KaTSXR_r_MB_NaCalcEqnMtrx_rt_Array_Float_27_27:0], parameter=KaTSXR_r_MB_NaCalcEqnMtrx}, required-interface=KaTSXR_r_MB_NaCalcEqnMtrx
      KaTSXR_r_MB_NbCalcEqnMtrx: parameter-require-com-spec{init-value=KaTSXR_r_MB_NbCalcEqnMtrx_KaTSXR_r_MB_NbCalcEqnMtrx:[KaTSXR_r_MB_NbCalcEqnMtrx_KaTSXR_r_MB_NbCalcEqnMtrx_rt_Array_Float_27_1:0, KaTSXR_r_MB_NbCalcEqnMtrx_KaTSXR_r_MB_NbCalcEqnMtrx_rt_Array_Float_27_2:0, KaTSXR_r_MB_NbCalcEqnMtrx_KaTSXR_r_MB_NbCalcEqnMtrx_rt_Array_Float_27_3:0, KaTSXR_r_MB_NbCalcEqnMtrx_KaTSXR_r_MB_NbCalcEqnMtrx_rt_Array_Float_27_4:0, KaTSXR_r_MB_NbCalcEqnMtrx_KaTSXR_r_MB_NbCalcEqnMtrx_rt_Array_Float_27_5:0, KaTSXR_r_MB_NbCalcEqnMtrx_KaTSXR_r_MB_NbCalcEqnMtrx_rt_Array_Float_27_6:0, KaTSXR_r_MB_NbCalcEqnMtrx_KaTSXR_r_MB_NbCalcEqnMtrx_rt_Array_Float_27_7:0, KaTSXR_r_MB_NbCalcEqnMtrx_KaTSXR_r_MB_NbCalcEqnMtrx_rt_Array_Float_27_8:0, KaTSXR_r_MB_NbCalcEqnMtrx_KaTSXR_r_MB_NbCalcEqnMtrx_rt_Array_Float_27_9:0, KaTSXR_r_MB_NbCalcEqnMtrx_KaTSXR_r_MB_NbCalcEqnMtrx_rt_Array_Float_27_10:0, KaTSXR_r_MB_NbCalcEqnMtrx_KaTSXR_r_MB_NbCalcEqnMtrx_rt_Array_Float_27_11:0, KaTSXR_r_MB_NbCalcEqnMtrx_KaTSXR_r_MB_NbCalcEqnMtrx_rt_Array_Float_27_12:0, KaTSXR_r_MB_NbCalcEqnMtrx_KaTSXR_r_MB_NbCalcEqnMtrx_rt_Array_Float_27_13:0, KaTSXR_r_MB_NbCalcEqnMtrx_KaTSXR_r_MB_NbCalcEqnMtrx_rt_Array_Float_27_14:0, KaTSXR_r_MB_NbCalcEqnMtrx_KaTSXR_r_MB_NbCalcEqnMtrx_rt_Array_Float_27_15:0, KaTSXR_r_MB_NbCalcEqnMtrx_KaTSXR_r_MB_NbCalcEqnMtrx_rt_Array_Float_27_16:0, KaTSXR_r_MB_NbCalcEqnMtrx_KaTSXR_r_MB_NbCalcEqnMtrx_rt_Array_Float_27_17:0, KaTSXR_r_MB_NbCalcEqnMtrx_KaTSXR_r_MB_NbCalcEqnMtrx_rt_Array_Float_27_18:0, KaTSXR_r_MB_NbCalcEqnMtrx_KaTSXR_r_MB_NbCalcEqnMtrx_rt_Array_Float_27_19:0, KaTSXR_r_MB_NbCalcEqnMtrx_KaTSXR_r_MB_NbCalcEqnMtrx_rt_Array_Float_27_20:0, KaTSXR_r_MB_NbCalcEqnMtrx_KaTSXR_r_MB_NbCalcEqnMtrx_rt_Array_Float_27_21:0, KaTSXR_r_MB_NbCalcEqnMtrx_KaTSXR_r_MB_NbCalcEqnMtrx_rt_Array_Float_27_22:0, KaTSXR_r_MB_NbCalcEqnMtrx_KaTSXR_r_MB_NbCalcEqnMtrx_rt_Array_Float_27_23:0, KaTSXR_r_MB_NbCalcEqnMtrx_KaTSXR_r_MB_NbCalcEqnMtrx_rt_Array_Float_27_24:0, KaTSXR_r_MB_NbCalcEqnMtrx_KaTSXR_r_MB_NbCalcEqnMtrx_rt_Array_Float_27_25:0, KaTSXR_r_MB_NbCalcEqnMtrx_KaTSXR_r_MB_NbCalcEqnMtrx_rt_Array_Float_27_26:0, KaTSXR_r_MB_NbCalcEqnMtrx_KaTSXR_r_MB_NbCalcEqnMtrx_rt_Array_Float_27_27:0], parameter=KaTSXR_r_MB_NbCalcEqnMtrx}, required-interface=KaTSXR_r_MB_NbCalcEqnMtrx
      KaTSXR_r_MB_Nc1CalcEqnMtrx: parameter-require-com-spec{init-value=KaTSXR_r_MB_Nc1CalcEqnMtrx_KaTSXR_r_MB_Nc1CalcEqnMtrx:[KaTSXR_r_MB_Nc1CalcEqnMtrx_KaTSXR_r_MB_Nc1CalcEqnMtrx_rt_Array_Float_27_1:0, KaTSXR_r_MB_Nc1CalcEqnMtrx_KaTSXR_r_MB_Nc1CalcEqnMtrx_rt_Array_Float_27_2:0, KaTSXR_r_MB_Nc1CalcEqnMtrx_KaTSXR_r_MB_Nc1CalcEqnMtrx_rt_Array_Float_27_3:0, KaTSXR_r_MB_Nc1CalcEqnMtrx_KaTSXR_r_MB_Nc1CalcEqnMtrx_rt_Array_Float_27_4:0, KaTSXR_r_MB_Nc1CalcEqnMtrx_KaTSXR_r_MB_Nc1CalcEqnMtrx_rt_Array_Float_27_5:0, KaTSXR_r_MB_Nc1CalcEqnMtrx_KaTSXR_r_MB_Nc1CalcEqnMtrx_rt_Array_Float_27_6:0, KaTSXR_r_MB_Nc1CalcEqnMtrx_KaTSXR_r_MB_Nc1CalcEqnMtrx_rt_Array_Float_27_7:0, KaTSXR_r_MB_Nc1CalcEqnMtrx_KaTSXR_r_MB_Nc1CalcEqnMtrx_rt_Array_Float_27_8:0, KaTSXR_r_MB_Nc1CalcEqnMtrx_KaTSXR_r_MB_Nc1CalcEqnMtrx_rt_Array_Float_27_9:0, KaTSXR_r_MB_Nc1CalcEqnMtrx_KaTSXR_r_MB_Nc1CalcEqnMtrx_rt_Array_Float_27_10:0, KaTSXR_r_MB_Nc1CalcEqnMtrx_KaTSXR_r_MB_Nc1CalcEqnMtrx_rt_Array_Float_27_11:0, KaTSXR_r_MB_Nc1CalcEqnMtrx_KaTSXR_r_MB_Nc1CalcEqnMtrx_rt_Array_Float_27_12:0, KaTSXR_r_MB_Nc1CalcEqnMtrx_KaTSXR_r_MB_Nc1CalcEqnMtrx_rt_Array_Float_27_13:0, KaTSXR_r_MB_Nc1CalcEqnMtrx_KaTSXR_r_MB_Nc1CalcEqnMtrx_rt_Array_Float_27_14:0, KaTSXR_r_MB_Nc1CalcEqnMtrx_KaTSXR_r_MB_Nc1CalcEqnMtrx_rt_Array_Float_27_15:0, KaTSXR_r_MB_Nc1CalcEqnMtrx_KaTSXR_r_MB_Nc1CalcEqnMtrx_rt_Array_Float_27_16:0, KaTSXR_r_MB_Nc1CalcEqnMtrx_KaTSXR_r_MB_Nc1CalcEqnMtrx_rt_Array_Float_27_17:0, KaTSXR_r_MB_Nc1CalcEqnMtrx_KaTSXR_r_MB_Nc1CalcEqnMtrx_rt_Array_Float_27_18:0, KaTSXR_r_MB_Nc1CalcEqnMtrx_KaTSXR_r_MB_Nc1CalcEqnMtrx_rt_Array_Float_27_19:0, KaTSXR_r_MB_Nc1CalcEqnMtrx_KaTSXR_r_MB_Nc1CalcEqnMtrx_rt_Array_Float_27_20:0, KaTSXR_r_MB_Nc1CalcEqnMtrx_KaTSXR_r_MB_Nc1CalcEqnMtrx_rt_Array_Float_27_21:0, KaTSXR_r_MB_Nc1CalcEqnMtrx_KaTSXR_r_MB_Nc1CalcEqnMtrx_rt_Array_Float_27_22:0, KaTSXR_r_MB_Nc1CalcEqnMtrx_KaTSXR_r_MB_Nc1CalcEqnMtrx_rt_Array_Float_27_23:0, KaTSXR_r_MB_Nc1CalcEqnMtrx_KaTSXR_r_MB_Nc1CalcEqnMtrx_rt_Array_Float_27_24:0, KaTSXR_r_MB_Nc1CalcEqnMtrx_KaTSXR_r_MB_Nc1CalcEqnMtrx_rt_Array_Float_27_25:0, KaTSXR_r_MB_Nc1CalcEqnMtrx_KaTSXR_r_MB_Nc1CalcEqnMtrx_rt_Array_Float_27_26:0, KaTSXR_r_MB_Nc1CalcEqnMtrx_KaTSXR_r_MB_Nc1CalcEqnMtrx_rt_Array_Float_27_27:0], parameter=KaTSXR_r_MB_Nc1CalcEqnMtrx}, required-interface=KaTSXR_r_MB_Nc1CalcEqnMtrx
      KaTSXR_r_MB_NcCalcEqnMtrx: parameter-require-com-spec{init-value=KaTSXR_r_MB_NcCalcEqnMtrx_KaTSXR_r_MB_NcCalcEqnMtrx:[KaTSXR_r_MB_NcCalcEqnMtrx_KaTSXR_r_MB_NcCalcEqnMtrx_rt_Array_Float_27_1:0, KaTSXR_r_MB_NcCalcEqnMtrx_KaTSXR_r_MB_NcCalcEqnMtrx_rt_Array_Float_27_2:0, KaTSXR_r_MB_NcCalcEqnMtrx_KaTSXR_r_MB_NcCalcEqnMtrx_rt_Array_Float_27_3:0, KaTSXR_r_MB_NcCalcEqnMtrx_KaTSXR_r_MB_NcCalcEqnMtrx_rt_Array_Float_27_4:0, KaTSXR_r_MB_NcCalcEqnMtrx_KaTSXR_r_MB_NcCalcEqnMtrx_rt_Array_Float_27_5:0, KaTSXR_r_MB_NcCalcEqnMtrx_KaTSXR_r_MB_NcCalcEqnMtrx_rt_Array_Float_27_6:0, KaTSXR_r_MB_NcCalcEqnMtrx_KaTSXR_r_MB_NcCalcEqnMtrx_rt_Array_Float_27_7:0, KaTSXR_r_MB_NcCalcEqnMtrx_KaTSXR_r_MB_NcCalcEqnMtrx_rt_Array_Float_27_8:0, KaTSXR_r_MB_NcCalcEqnMtrx_KaTSXR_r_MB_NcCalcEqnMtrx_rt_Array_Float_27_9:0, KaTSXR_r_MB_NcCalcEqnMtrx_KaTSXR_r_MB_NcCalcEqnMtrx_rt_Array_Float_27_10:0, KaTSXR_r_MB_NcCalcEqnMtrx_KaTSXR_r_MB_NcCalcEqnMtrx_rt_Array_Float_27_11:0, KaTSXR_r_MB_NcCalcEqnMtrx_KaTSXR_r_MB_NcCalcEqnMtrx_rt_Array_Float_27_12:0, KaTSXR_r_MB_NcCalcEqnMtrx_KaTSXR_r_MB_NcCalcEqnMtrx_rt_Array_Float_27_13:0, KaTSXR_r_MB_NcCalcEqnMtrx_KaTSXR_r_MB_NcCalcEqnMtrx_rt_Array_Float_27_14:0, KaTSXR_r_MB_NcCalcEqnMtrx_KaTSXR_r_MB_NcCalcEqnMtrx_rt_Array_Float_27_15:0, KaTSXR_r_MB_NcCalcEqnMtrx_KaTSXR_r_MB_NcCalcEqnMtrx_rt_Array_Float_27_16:0, KaTSXR_r_MB_NcCalcEqnMtrx_KaTSXR_r_MB_NcCalcEqnMtrx_rt_Array_Float_27_17:0, KaTSXR_r_MB_NcCalcEqnMtrx_KaTSXR_r_MB_NcCalcEqnMtrx_rt_Array_Float_27_18:0, KaTSXR_r_MB_NcCalcEqnMtrx_KaTSXR_r_MB_NcCalcEqnMtrx_rt_Array_Float_27_19:0, KaTSXR_r_MB_NcCalcEqnMtrx_KaTSXR_r_MB_NcCalcEqnMtrx_rt_Array_Float_27_20:0, KaTSXR_r_MB_NcCalcEqnMtrx_KaTSXR_r_MB_NcCalcEqnMtrx_rt_Array_Float_27_21:0, KaTSXR_r_MB_NcCalcEqnMtrx_KaTSXR_r_MB_NcCalcEqnMtrx_rt_Array_Float_27_22:0, KaTSXR_r_MB_NcCalcEqnMtrx_KaTSXR_r_MB_NcCalcEqnMtrx_rt_Array_Float_27_23:0, KaTSXR_r_MB_NcCalcEqnMtrx_KaTSXR_r_MB_NcCalcEqnMtrx_rt_Array_Float_27_24:0, KaTSXR_r_MB_NcCalcEqnMtrx_KaTSXR_r_MB_NcCalcEqnMtrx_rt_Array_Float_27_25:0, KaTSXR_r_MB_NcCalcEqnMtrx_KaTSXR_r_MB_NcCalcEqnMtrx_rt_Array_Float_27_26:0, KaTSXR_r_MB_NcCalcEqnMtrx_KaTSXR_r_MB_NcCalcEqnMtrx_rt_Array_Float_27_27:0], parameter=KaTSXR_r_MB_NcCalcEqnMtrx}, required-interface=KaTSXR_r_MB_NcCalcEqnMtrx
      KaTSXR_r_MB_TM1_ToConstrn: parameter-require-com-spec{init-value=KaTSXR_r_MB_TM1_ToConstrn_KaTSXR_r_MB_TM1_ToConstrn:[KaTSXR_r_MB_TM1_ToConstrn_KaTSXR_r_MB_TM1_ToConstrn_rt_Array_Float_126_1:0, KaTSXR_r_MB_TM1_ToConstrn_KaTSXR_r_MB_TM1_ToConstrn_rt_Array_Float_126_2:0, KaTSXR_r_MB_TM1_ToConstrn_KaTSXR_r_MB_TM1_ToConstrn_rt_Array_Float_126_3:0, KaTSXR_r_MB_TM1_ToConstrn_KaTSXR_r_MB_TM1_ToConstrn_rt_Array_Float_126_4:0, KaTSXR_r_MB_TM1_ToConstrn_KaTSXR_r_MB_TM1_ToConstrn_rt_Array_Float_126_5:0, KaTSXR_r_MB_TM1_ToConstrn_KaTSXR_r_MB_TM1_ToConstrn_rt_Array_Float_126_6:0, KaTSXR_r_MB_TM1_ToConstrn_KaTSXR_r_MB_TM1_ToConstrn_rt_Array_Float_126_7:0, KaTSXR_r_MB_TM1_ToConstrn_KaTSXR_r_MB_TM1_ToConstrn_rt_Array_Float_126_8:0, KaTSXR_r_MB_TM1_ToConstrn_KaTSXR_r_MB_TM1_ToConstrn_rt_Array_Float_126_9:0, KaTSXR_r_MB_TM1_ToConstrn_KaTSXR_r_MB_TM1_ToConstrn_rt_Array_Float_126_10:0, KaTSXR_r_MB_TM1_ToConstrn_KaTSXR_r_MB_TM1_ToConstrn_rt_Array_Float_126_11:0, KaTSXR_r_MB_TM1_ToConstrn_KaTSXR_r_MB_TM1_ToConstrn_rt_Array_Float_126_12:0, KaTSXR_r_MB_TM1_ToConstrn_KaTSXR_r_MB_TM1_ToConstrn_rt_Array_Float_126_13:0, KaTSXR_r_MB_TM1_ToConstrn_KaTSXR_r_MB_TM1_ToConstrn_rt_Array_Float_126_14:0, KaTSXR_r_MB_TM1_ToConstrn_KaTSXR_r_MB_TM1_ToConstrn_rt_Array_Float_126_15:0, KaTSXR_r_MB_TM1_ToConstrn_KaTSXR_r_MB_TM1_ToConstrn_rt_Array_Float_126_16:0, KaTSXR_r_MB_TM1_ToConstrn_KaTSXR_r_MB_TM1_ToConstrn_rt_Array_Float_126_17:0, KaTSXR_r_MB_TM1_ToConstrn_KaTSXR_r_MB_TM1_ToConstrn_rt_Array_Float_126_18:0, KaTSXR_r_MB_TM1_ToConstrn_KaTSXR_r_MB_TM1_ToConstrn_rt_Array_Float_126_19:0, KaTSXR_r_MB_TM1_ToConstrn_KaTSXR_r_MB_TM1_ToConstrn_rt_Array_Float_126_20:0, KaTSXR_r_MB_TM1_ToConstrn_KaTSXR_r_MB_TM1_ToConstrn_rt_Array_Float_126_21:0, KaTSXR_r_MB_TM1_ToConstrn_KaTSXR_r_MB_TM1_ToConstrn_rt_Array_Float_126_22:0, KaTSXR_r_MB_TM1_ToConstrn_KaTSXR_r_MB_TM1_ToConstrn_rt_Array_Float_126_23:0, KaTSXR_r_MB_TM1_ToConstrn_KaTSXR_r_MB_TM1_ToConstrn_rt_Array_Float_126_24:0, KaTSXR_r_MB_TM1_ToConstrn_KaTSXR_r_MB_TM1_ToConstrn_rt_Array_Float_126_25:0, KaTSXR_r_MB_TM1_ToConstrn_KaTSXR_r_MB_TM1_ToConstrn_rt_Array_Float_126_26:0, KaTSXR_r_MB_TM1_ToConstrn_KaTSXR_r_MB_TM1_ToConstrn_rt_Array_Float_126_27:0, KaTSXR_r_MB_TM1_ToConstrn_KaTSXR_r_MB_TM1_ToConstrn_rt_Array_Float_126_28:0, KaTSXR_r_MB_TM1_ToConstrn_KaTSXR_r_MB_TM1_ToConstrn_rt_Array_Float_126_29:0, KaTSXR_r_MB_TM1_ToConstrn_KaTSXR_r_MB_TM1_ToConstrn_rt_Array_Float_126_30:0, KaTSXR_r_MB_TM1_ToConstrn_KaTSXR_r_MB_TM1_ToConstrn_rt_Array_Float_126_31:0, KaTSXR_r_MB_TM1_ToConstrn_KaTSXR_r_MB_TM1_ToConstrn_rt_Array_Float_126_32:0, KaTSXR_r_MB_TM1_ToConstrn_KaTSXR_r_MB_TM1_ToConstrn_rt_Array_Float_126_33:0, KaTSXR_r_MB_TM1_ToConstrn_KaTSXR_r_MB_TM1_ToConstrn_rt_Array_Float_126_34:0, KaTSXR_r_MB_TM1_ToConstrn_KaTSXR_r_MB_TM1_ToConstrn_rt_Array_Float_126_35:0, KaTSXR_r_MB_TM1_ToConstrn_KaTSXR_r_MB_TM1_ToConstrn_rt_Array_Float_126_36:0, KaTSXR_r_MB_TM1_ToConstrn_KaTSXR_r_MB_TM1_ToConstrn_rt_Array_Float_126_37:0, KaTSXR_r_MB_TM1_ToConstrn_KaTSXR_r_MB_TM1_ToConstrn_rt_Array_Float_126_38:0, KaTSXR_r_MB_TM1_ToConstrn_KaTSXR_r_MB_TM1_ToConstrn_rt_Array_Float_126_39:0, KaTSXR_r_MB_TM1_ToConstrn_KaTSXR_r_MB_TM1_ToConstrn_rt_Array_Float_126_40:0, KaTSXR_r_MB_TM1_ToConstrn_KaTSXR_r_MB_TM1_ToConstrn_rt_Array_Float_126_41:0, KaTSXR_r_MB_TM1_ToConstrn_KaTSXR_r_MB_TM1_ToConstrn_rt_Array_Float_126_42:0, KaTSXR_r_MB_TM1_ToConstrn_KaTSXR_r_MB_TM1_ToConstrn_rt_Array_Float_126_43:0, KaTSXR_r_MB_TM1_ToConstrn_KaTSXR_r_MB_TM1_ToConstrn_rt_Array_Float_126_44:0, KaTSXR_r_MB_TM1_ToConstrn_KaTSXR_r_MB_TM1_ToConstrn_rt_Array_Float_126_45:0, KaTSXR_r_MB_TM1_ToConstrn_KaTSXR_r_MB_TM1_ToConstrn_rt_Array_Float_126_46:0, KaTSXR_r_MB_TM1_ToConstrn_KaTSXR_r_MB_TM1_ToConstrn_rt_Array_Float_126_47:0, KaTSXR_r_MB_TM1_ToConstrn_KaTSXR_r_MB_TM1_ToConstrn_rt_Array_Float_126_48:0, KaTSXR_r_MB_TM1_ToConstrn_KaTSXR_r_MB_TM1_ToConstrn_rt_Array_Float_126_49:0, KaTSXR_r_MB_TM1_ToConstrn_KaTSXR_r_MB_TM1_ToConstrn_rt_Array_Float_126_50:0, KaTSXR_r_MB_TM1_ToConstrn_KaTSXR_r_MB_TM1_ToConstrn_rt_Array_Float_126_51:0, KaTSXR_r_MB_TM1_ToConstrn_KaTSXR_r_MB_TM1_ToConstrn_rt_Array_Float_126_52:0, KaTSXR_r_MB_TM1_ToConstrn_KaTSXR_r_MB_TM1_ToConstrn_rt_Array_Float_126_53:0, KaTSXR_r_MB_TM1_ToConstrn_KaTSXR_r_MB_TM1_ToConstrn_rt_Array_Float_126_54:0, KaTSXR_r_MB_TM1_ToConstrn_KaTSXR_r_MB_TM1_ToConstrn_rt_Array_Float_126_55:0, KaTSXR_r_MB_TM1_ToConstrn_KaTSXR_r_MB_TM1_ToConstrn_rt_Array_Float_126_56:0, KaTSXR_r_MB_TM1_ToConstrn_KaTSXR_r_MB_TM1_ToConstrn_rt_Array_Float_126_57:0, KaTSXR_r_MB_TM1_ToConstrn_KaTSXR_r_MB_TM1_ToConstrn_rt_Array_Float_126_58:0, KaTSXR_r_MB_TM1_ToConstrn_KaTSXR_r_MB_TM1_ToConstrn_rt_Array_Float_126_59:0, KaTSXR_r_MB_TM1_ToConstrn_KaTSXR_r_MB_TM1_ToConstrn_rt_Array_Float_126_60:0, KaTSXR_r_MB_TM1_ToConstrn_KaTSXR_r_MB_TM1_ToConstrn_rt_Array_Float_126_61:0, KaTSXR_r_MB_TM1_ToConstrn_KaTSXR_r_MB_TM1_ToConstrn_rt_Array_Float_126_62:0, KaTSXR_r_MB_TM1_ToConstrn_KaTSXR_r_MB_TM1_ToConstrn_rt_Array_Float_126_63:0, KaTSXR_r_MB_TM1_ToConstrn_KaTSXR_r_MB_TM1_ToConstrn_rt_Array_Float_126_64:0, KaTSXR_r_MB_TM1_ToConstrn_KaTSXR_r_MB_TM1_ToConstrn_rt_Array_Float_126_65:0, KaTSXR_r_MB_TM1_ToConstrn_KaTSXR_r_MB_TM1_ToConstrn_rt_Array_Float_126_66:0, KaTSXR_r_MB_TM1_ToConstrn_KaTSXR_r_MB_TM1_ToConstrn_rt_Array_Float_126_67:0, KaTSXR_r_MB_TM1_ToConstrn_KaTSXR_r_MB_TM1_ToConstrn_rt_Array_Float_126_68:0, KaTSXR_r_MB_TM1_ToConstrn_KaTSXR_r_MB_TM1_ToConstrn_rt_Array_Float_126_69:0, KaTSXR_r_MB_TM1_ToConstrn_KaTSXR_r_MB_TM1_ToConstrn_rt_Array_Float_126_70:0, KaTSXR_r_MB_TM1_ToConstrn_KaTSXR_r_MB_TM1_ToConstrn_rt_Array_Float_126_71:0, KaTSXR_r_MB_TM1_ToConstrn_KaTSXR_r_MB_TM1_ToConstrn_rt_Array_Float_126_72:0, KaTSXR_r_MB_TM1_ToConstrn_KaTSXR_r_MB_TM1_ToConstrn_rt_Array_Float_126_73:0, KaTSXR_r_MB_TM1_ToConstrn_KaTSXR_r_MB_TM1_ToConstrn_rt_Array_Float_126_74:0, KaTSXR_r_MB_TM1_ToConstrn_KaTSXR_r_MB_TM1_ToConstrn_rt_Array_Float_126_75:0, KaTSXR_r_MB_TM1_ToConstrn_KaTSXR_r_MB_TM1_ToConstrn_rt_Array_Float_126_76:0, KaTSXR_r_MB_TM1_ToConstrn_KaTSXR_r_MB_TM1_ToConstrn_rt_Array_Float_126_77:0, KaTSXR_r_MB_TM1_ToConstrn_KaTSXR_r_MB_TM1_ToConstrn_rt_Array_Float_126_78:0, KaTSXR_r_MB_TM1_ToConstrn_KaTSXR_r_MB_TM1_ToConstrn_rt_Array_Float_126_79:0, KaTSXR_r_MB_TM1_ToConstrn_KaTSXR_r_MB_TM1_ToConstrn_rt_Array_Float_126_80:0, KaTSXR_r_MB_TM1_ToConstrn_KaTSXR_r_MB_TM1_ToConstrn_rt_Array_Float_126_81:0, KaTSXR_r_MB_TM1_ToConstrn_KaTSXR_r_MB_TM1_ToConstrn_rt_Array_Float_126_82:0, KaTSXR_r_MB_TM1_ToConstrn_KaTSXR_r_MB_TM1_ToConstrn_rt_Array_Float_126_83:0, KaTSXR_r_MB_TM1_ToConstrn_KaTSXR_r_MB_TM1_ToConstrn_rt_Array_Float_126_84:0, KaTSXR_r_MB_TM1_ToConstrn_KaTSXR_r_MB_TM1_ToConstrn_rt_Array_Float_126_85:0, KaTSXR_r_MB_TM1_ToConstrn_KaTSXR_r_MB_TM1_ToConstrn_rt_Array_Float_126_86:0, KaTSXR_r_MB_TM1_ToConstrn_KaTSXR_r_MB_TM1_ToConstrn_rt_Array_Float_126_87:0, KaTSXR_r_MB_TM1_ToConstrn_KaTSXR_r_MB_TM1_ToConstrn_rt_Array_Float_126_88:0, KaTSXR_r_MB_TM1_ToConstrn_KaTSXR_r_MB_TM1_ToConstrn_rt_Array_Float_126_89:0, KaTSXR_r_MB_TM1_ToConstrn_KaTSXR_r_MB_TM1_ToConstrn_rt_Array_Float_126_90:0, KaTSXR_r_MB_TM1_ToConstrn_KaTSXR_r_MB_TM1_ToConstrn_rt_Array_Float_126_91:0, KaTSXR_r_MB_TM1_ToConstrn_KaTSXR_r_MB_TM1_ToConstrn_rt_Array_Float_126_92:0, KaTSXR_r_MB_TM1_ToConstrn_KaTSXR_r_MB_TM1_ToConstrn_rt_Array_Float_126_93:0, KaTSXR_r_MB_TM1_ToConstrn_KaTSXR_r_MB_TM1_ToConstrn_rt_Array_Float_126_94:0, KaTSXR_r_MB_TM1_ToConstrn_KaTSXR_r_MB_TM1_ToConstrn_rt_Array_Float_126_95:0, KaTSXR_r_MB_TM1_ToConstrn_KaTSXR_r_MB_TM1_ToConstrn_rt_Array_Float_126_96:0, KaTSXR_r_MB_TM1_ToConstrn_KaTSXR_r_MB_TM1_ToConstrn_rt_Array_Float_126_97:0, KaTSXR_r_MB_TM1_ToConstrn_KaTSXR_r_MB_TM1_ToConstrn_rt_Array_Float_126_98:0, KaTSXR_r_MB_TM1_ToConstrn_KaTSXR_r_MB_TM1_ToConstrn_rt_Array_Float_126_99:0, KaTSXR_r_MB_TM1_ToConstrn_KaTSXR_r_MB_TM1_ToConstrn_rt_Array_Float_126_100:0, KaTSXR_r_MB_TM1_ToConstrn_KaTSXR_r_MB_TM1_ToConstrn_rt_Array_Float_126_101:0, KaTSXR_r_MB_TM1_ToConstrn_KaTSXR_r_MB_TM1_ToConstrn_rt_Array_Float_126_102:0, KaTSXR_r_MB_TM1_ToConstrn_KaTSXR_r_MB_TM1_ToConstrn_rt_Array_Float_126_103:0, KaTSXR_r_MB_TM1_ToConstrn_KaTSXR_r_MB_TM1_ToConstrn_rt_Array_Float_126_104:0, KaTSXR_r_MB_TM1_ToConstrn_KaTSXR_r_MB_TM1_ToConstrn_rt_Array_Float_126_105:0, KaTSXR_r_MB_TM1_ToConstrn_KaTSXR_r_MB_TM1_ToConstrn_rt_Array_Float_126_106:0, KaTSXR_r_MB_TM1_ToConstrn_KaTSXR_r_MB_TM1_ToConstrn_rt_Array_Float_126_107:0, KaTSXR_r_MB_TM1_ToConstrn_KaTSXR_r_MB_TM1_ToConstrn_rt_Array_Float_126_108:0, KaTSXR_r_MB_TM1_ToConstrn_KaTSXR_r_MB_TM1_ToConstrn_rt_Array_Float_126_109:0, KaTSXR_r_MB_TM1_ToConstrn_KaTSXR_r_MB_TM1_ToConstrn_rt_Array_Float_126_110:0, KaTSXR_r_MB_TM1_ToConstrn_KaTSXR_r_MB_TM1_ToConstrn_rt_Array_Float_126_111:0, KaTSXR_r_MB_TM1_ToConstrn_KaTSXR_r_MB_TM1_ToConstrn_rt_Array_Float_126_112:0, KaTSXR_r_MB_TM1_ToConstrn_KaTSXR_r_MB_TM1_ToConstrn_rt_Array_Float_126_113:0, KaTSXR_r_MB_TM1_ToConstrn_KaTSXR_r_MB_TM1_ToConstrn_rt_Array_Float_126_114:0, KaTSXR_r_MB_TM1_ToConstrn_KaTSXR_r_MB_TM1_ToConstrn_rt_Array_Float_126_115:0, KaTSXR_r_MB_TM1_ToConstrn_KaTSXR_r_MB_TM1_ToConstrn_rt_Array_Float_126_116:0, KaTSXR_r_MB_TM1_ToConstrn_KaTSXR_r_MB_TM1_ToConstrn_rt_Array_Float_126_117:0, KaTSXR_r_MB_TM1_ToConstrn_KaTSXR_r_MB_TM1_ToConstrn_rt_Array_Float_126_118:0, KaTSXR_r_MB_TM1_ToConstrn_KaTSXR_r_MB_TM1_ToConstrn_rt_Array_Float_126_119:0, KaTSXR_r_MB_TM1_ToConstrn_KaTSXR_r_MB_TM1_ToConstrn_rt_Array_Float_126_120:0, KaTSXR_r_MB_TM1_ToConstrn_KaTSXR_r_MB_TM1_ToConstrn_rt_Array_Float_126_121:0, KaTSXR_r_MB_TM1_ToConstrn_KaTSXR_r_MB_TM1_ToConstrn_rt_Array_Float_126_122:0, KaTSXR_r_MB_TM1_ToConstrn_KaTSXR_r_MB_TM1_ToConstrn_rt_Array_Float_126_123:0, KaTSXR_r_MB_TM1_ToConstrn_KaTSXR_r_MB_TM1_ToConstrn_rt_Array_Float_126_124:0, KaTSXR_r_MB_TM1_ToConstrn_KaTSXR_r_MB_TM1_ToConstrn_rt_Array_Float_126_125:0, KaTSXR_r_MB_TM1_ToConstrn_KaTSXR_r_MB_TM1_ToConstrn_rt_Array_Float_126_126:0], parameter=KaTSXR_r_MB_TM1_ToConstrn}, required-interface=KaTSXR_r_MB_TM1_ToConstrn
      KaTSXR_r_N_NaCalcEqnMtrx: parameter-require-com-spec{init-value=KaTSXR_r_N_NaCalcEqnMtrx_KaTSXR_r_N_NaCalcEqnMtrx:[KaTSXR_r_N_NaCalcEqnMtrx_KaTSXR_r_N_NaCalcEqnMtrx_rt_Array_Float_27_1:0, KaTSXR_r_N_NaCalcEqnMtrx_KaTSXR_r_N_NaCalcEqnMtrx_rt_Array_Float_27_2:0, KaTSXR_r_N_NaCalcEqnMtrx_KaTSXR_r_N_NaCalcEqnMtrx_rt_Array_Float_27_3:0, KaTSXR_r_N_NaCalcEqnMtrx_KaTSXR_r_N_NaCalcEqnMtrx_rt_Array_Float_27_4:0, KaTSXR_r_N_NaCalcEqnMtrx_KaTSXR_r_N_NaCalcEqnMtrx_rt_Array_Float_27_5:0, KaTSXR_r_N_NaCalcEqnMtrx_KaTSXR_r_N_NaCalcEqnMtrx_rt_Array_Float_27_6:0, KaTSXR_r_N_NaCalcEqnMtrx_KaTSXR_r_N_NaCalcEqnMtrx_rt_Array_Float_27_7:0, KaTSXR_r_N_NaCalcEqnMtrx_KaTSXR_r_N_NaCalcEqnMtrx_rt_Array_Float_27_8:0, KaTSXR_r_N_NaCalcEqnMtrx_KaTSXR_r_N_NaCalcEqnMtrx_rt_Array_Float_27_9:0, KaTSXR_r_N_NaCalcEqnMtrx_KaTSXR_r_N_NaCalcEqnMtrx_rt_Array_Float_27_10:0, KaTSXR_r_N_NaCalcEqnMtrx_KaTSXR_r_N_NaCalcEqnMtrx_rt_Array_Float_27_11:0, KaTSXR_r_N_NaCalcEqnMtrx_KaTSXR_r_N_NaCalcEqnMtrx_rt_Array_Float_27_12:0, KaTSXR_r_N_NaCalcEqnMtrx_KaTSXR_r_N_NaCalcEqnMtrx_rt_Array_Float_27_13:0, KaTSXR_r_N_NaCalcEqnMtrx_KaTSXR_r_N_NaCalcEqnMtrx_rt_Array_Float_27_14:0, KaTSXR_r_N_NaCalcEqnMtrx_KaTSXR_r_N_NaCalcEqnMtrx_rt_Array_Float_27_15:0, KaTSXR_r_N_NaCalcEqnMtrx_KaTSXR_r_N_NaCalcEqnMtrx_rt_Array_Float_27_16:0, KaTSXR_r_N_NaCalcEqnMtrx_KaTSXR_r_N_NaCalcEqnMtrx_rt_Array_Float_27_17:0, KaTSXR_r_N_NaCalcEqnMtrx_KaTSXR_r_N_NaCalcEqnMtrx_rt_Array_Float_27_18:0, KaTSXR_r_N_NaCalcEqnMtrx_KaTSXR_r_N_NaCalcEqnMtrx_rt_Array_Float_27_19:0, KaTSXR_r_N_NaCalcEqnMtrx_KaTSXR_r_N_NaCalcEqnMtrx_rt_Array_Float_27_20:0, KaTSXR_r_N_NaCalcEqnMtrx_KaTSXR_r_N_NaCalcEqnMtrx_rt_Array_Float_27_21:0, KaTSXR_r_N_NaCalcEqnMtrx_KaTSXR_r_N_NaCalcEqnMtrx_rt_Array_Float_27_22:0, KaTSXR_r_N_NaCalcEqnMtrx_KaTSXR_r_N_NaCalcEqnMtrx_rt_Array_Float_27_23:0, KaTSXR_r_N_NaCalcEqnMtrx_KaTSXR_r_N_NaCalcEqnMtrx_rt_Array_Float_27_24:0, KaTSXR_r_N_NaCalcEqnMtrx_KaTSXR_r_N_NaCalcEqnMtrx_rt_Array_Float_27_25:0, KaTSXR_r_N_NaCalcEqnMtrx_KaTSXR_r_N_NaCalcEqnMtrx_rt_Array_Float_27_26:0, KaTSXR_r_N_NaCalcEqnMtrx_KaTSXR_r_N_NaCalcEqnMtrx_rt_Array_Float_27_27:0], parameter=KaTSXR_r_N_NaCalcEqnMtrx}, required-interface=KaTSXR_r_N_NaCalcEqnMtrx
      KaTSXR_r_N_NbCalcEqnMtrx: parameter-require-com-spec{init-value=KaTSXR_r_N_NbCalcEqnMtrx_KaTSXR_r_N_NbCalcEqnMtrx:[KaTSXR_r_N_NbCalcEqnMtrx_KaTSXR_r_N_NbCalcEqnMtrx_rt_Array_Float_27_1:0, KaTSXR_r_N_NbCalcEqnMtrx_KaTSXR_r_N_NbCalcEqnMtrx_rt_Array_Float_27_2:0, KaTSXR_r_N_NbCalcEqnMtrx_KaTSXR_r_N_NbCalcEqnMtrx_rt_Array_Float_27_3:0, KaTSXR_r_N_NbCalcEqnMtrx_KaTSXR_r_N_NbCalcEqnMtrx_rt_Array_Float_27_4:0, KaTSXR_r_N_NbCalcEqnMtrx_KaTSXR_r_N_NbCalcEqnMtrx_rt_Array_Float_27_5:0, KaTSXR_r_N_NbCalcEqnMtrx_KaTSXR_r_N_NbCalcEqnMtrx_rt_Array_Float_27_6:0, KaTSXR_r_N_NbCalcEqnMtrx_KaTSXR_r_N_NbCalcEqnMtrx_rt_Array_Float_27_7:0, KaTSXR_r_N_NbCalcEqnMtrx_KaTSXR_r_N_NbCalcEqnMtrx_rt_Array_Float_27_8:0, KaTSXR_r_N_NbCalcEqnMtrx_KaTSXR_r_N_NbCalcEqnMtrx_rt_Array_Float_27_9:0, KaTSXR_r_N_NbCalcEqnMtrx_KaTSXR_r_N_NbCalcEqnMtrx_rt_Array_Float_27_10:0, KaTSXR_r_N_NbCalcEqnMtrx_KaTSXR_r_N_NbCalcEqnMtrx_rt_Array_Float_27_11:0, KaTSXR_r_N_NbCalcEqnMtrx_KaTSXR_r_N_NbCalcEqnMtrx_rt_Array_Float_27_12:0, KaTSXR_r_N_NbCalcEqnMtrx_KaTSXR_r_N_NbCalcEqnMtrx_rt_Array_Float_27_13:0, KaTSXR_r_N_NbCalcEqnMtrx_KaTSXR_r_N_NbCalcEqnMtrx_rt_Array_Float_27_14:0, KaTSXR_r_N_NbCalcEqnMtrx_KaTSXR_r_N_NbCalcEqnMtrx_rt_Array_Float_27_15:0, KaTSXR_r_N_NbCalcEqnMtrx_KaTSXR_r_N_NbCalcEqnMtrx_rt_Array_Float_27_16:0, KaTSXR_r_N_NbCalcEqnMtrx_KaTSXR_r_N_NbCalcEqnMtrx_rt_Array_Float_27_17:0, KaTSXR_r_N_NbCalcEqnMtrx_KaTSXR_r_N_NbCalcEqnMtrx_rt_Array_Float_27_18:0, KaTSXR_r_N_NbCalcEqnMtrx_KaTSXR_r_N_NbCalcEqnMtrx_rt_Array_Float_27_19:0, KaTSXR_r_N_NbCalcEqnMtrx_KaTSXR_r_N_NbCalcEqnMtrx_rt_Array_Float_27_20:0, KaTSXR_r_N_NbCalcEqnMtrx_KaTSXR_r_N_NbCalcEqnMtrx_rt_Array_Float_27_21:0, KaTSXR_r_N_NbCalcEqnMtrx_KaTSXR_r_N_NbCalcEqnMtrx_rt_Array_Float_27_22:0, KaTSXR_r_N_NbCalcEqnMtrx_KaTSXR_r_N_NbCalcEqnMtrx_rt_Array_Float_27_23:0, KaTSXR_r_N_NbCalcEqnMtrx_KaTSXR_r_N_NbCalcEqnMtrx_rt_Array_Float_27_24:0, KaTSXR_r_N_NbCalcEqnMtrx_KaTSXR_r_N_NbCalcEqnMtrx_rt_Array_Float_27_25:0, KaTSXR_r_N_NbCalcEqnMtrx_KaTSXR_r_N_NbCalcEqnMtrx_rt_Array_Float_27_26:0, KaTSXR_r_N_NbCalcEqnMtrx_KaTSXR_r_N_NbCalcEqnMtrx_rt_Array_Float_27_27:0], parameter=KaTSXR_r_N_NbCalcEqnMtrx}, required-interface=KaTSXR_r_N_NbCalcEqnMtrx
      KaTSXR_r_N_Nc1CalcEqnMtrx: parameter-require-com-spec{init-value=KaTSXR_r_N_Nc1CalcEqnMtrx_KaTSXR_r_N_Nc1CalcEqnMtrx:[KaTSXR_r_N_Nc1CalcEqnMtrx_KaTSXR_r_N_Nc1CalcEqnMtrx_rt_Array_Float_27_1:0, KaTSXR_r_N_Nc1CalcEqnMtrx_KaTSXR_r_N_Nc1CalcEqnMtrx_rt_Array_Float_27_2:0, KaTSXR_r_N_Nc1CalcEqnMtrx_KaTSXR_r_N_Nc1CalcEqnMtrx_rt_Array_Float_27_3:0, KaTSXR_r_N_Nc1CalcEqnMtrx_KaTSXR_r_N_Nc1CalcEqnMtrx_rt_Array_Float_27_4:0, KaTSXR_r_N_Nc1CalcEqnMtrx_KaTSXR_r_N_Nc1CalcEqnMtrx_rt_Array_Float_27_5:0, KaTSXR_r_N_Nc1CalcEqnMtrx_KaTSXR_r_N_Nc1CalcEqnMtrx_rt_Array_Float_27_6:0, KaTSXR_r_N_Nc1CalcEqnMtrx_KaTSXR_r_N_Nc1CalcEqnMtrx_rt_Array_Float_27_7:0, KaTSXR_r_N_Nc1CalcEqnMtrx_KaTSXR_r_N_Nc1CalcEqnMtrx_rt_Array_Float_27_8:0, KaTSXR_r_N_Nc1CalcEqnMtrx_KaTSXR_r_N_Nc1CalcEqnMtrx_rt_Array_Float_27_9:0, KaTSXR_r_N_Nc1CalcEqnMtrx_KaTSXR_r_N_Nc1CalcEqnMtrx_rt_Array_Float_27_10:0, KaTSXR_r_N_Nc1CalcEqnMtrx_KaTSXR_r_N_Nc1CalcEqnMtrx_rt_Array_Float_27_11:0, KaTSXR_r_N_Nc1CalcEqnMtrx_KaTSXR_r_N_Nc1CalcEqnMtrx_rt_Array_Float_27_12:0, KaTSXR_r_N_Nc1CalcEqnMtrx_KaTSXR_r_N_Nc1CalcEqnMtrx_rt_Array_Float_27_13:0, KaTSXR_r_N_Nc1CalcEqnMtrx_KaTSXR_r_N_Nc1CalcEqnMtrx_rt_Array_Float_27_14:0, KaTSXR_r_N_Nc1CalcEqnMtrx_KaTSXR_r_N_Nc1CalcEqnMtrx_rt_Array_Float_27_15:0, KaTSXR_r_N_Nc1CalcEqnMtrx_KaTSXR_r_N_Nc1CalcEqnMtrx_rt_Array_Float_27_16:0, KaTSXR_r_N_Nc1CalcEqnMtrx_KaTSXR_r_N_Nc1CalcEqnMtrx_rt_Array_Float_27_17:0, KaTSXR_r_N_Nc1CalcEqnMtrx_KaTSXR_r_N_Nc1CalcEqnMtrx_rt_Array_Float_27_18:0, KaTSXR_r_N_Nc1CalcEqnMtrx_KaTSXR_r_N_Nc1CalcEqnMtrx_rt_Array_Float_27_19:0, KaTSXR_r_N_Nc1CalcEqnMtrx_KaTSXR_r_N_Nc1CalcEqnMtrx_rt_Array_Float_27_20:0, KaTSXR_r_N_Nc1CalcEqnMtrx_KaTSXR_r_N_Nc1CalcEqnMtrx_rt_Array_Float_27_21:0, KaTSXR_r_N_Nc1CalcEqnMtrx_KaTSXR_r_N_Nc1CalcEqnMtrx_rt_Array_Float_27_22:0, KaTSXR_r_N_Nc1CalcEqnMtrx_KaTSXR_r_N_Nc1CalcEqnMtrx_rt_Array_Float_27_23:0, KaTSXR_r_N_Nc1CalcEqnMtrx_KaTSXR_r_N_Nc1CalcEqnMtrx_rt_Array_Float_27_24:0, KaTSXR_r_N_Nc1CalcEqnMtrx_KaTSXR_r_N_Nc1CalcEqnMtrx_rt_Array_Float_27_25:0, KaTSXR_r_N_Nc1CalcEqnMtrx_KaTSXR_r_N_Nc1CalcEqnMtrx_rt_Array_Float_27_26:0, KaTSXR_r_N_Nc1CalcEqnMtrx_KaTSXR_r_N_Nc1CalcEqnMtrx_rt_Array_Float_27_27:0], parameter=KaTSXR_r_N_Nc1CalcEqnMtrx}, required-interface=KaTSXR_r_N_Nc1CalcEqnMtrx
      KaTSXR_r_N_Nc1TargetEqnMtrx: parameter-require-com-spec{init-value=KaTSXR_r_N_Nc1TargetEqnMtrx_KaTSXR_r_N_Nc1TargetEqnMtrx:[KaTSXR_r_N_Nc1TargetEqnMtrx_KaTSXR_r_N_Nc1TargetEqnMtrx_rt_Array_Float_27_1:0, KaTSXR_r_N_Nc1TargetEqnMtrx_KaTSXR_r_N_Nc1TargetEqnMtrx_rt_Array_Float_27_2:0, KaTSXR_r_N_Nc1TargetEqnMtrx_KaTSXR_r_N_Nc1TargetEqnMtrx_rt_Array_Float_27_3:0, KaTSXR_r_N_Nc1TargetEqnMtrx_KaTSXR_r_N_Nc1TargetEqnMtrx_rt_Array_Float_27_4:0, KaTSXR_r_N_Nc1TargetEqnMtrx_KaTSXR_r_N_Nc1TargetEqnMtrx_rt_Array_Float_27_5:0, KaTSXR_r_N_Nc1TargetEqnMtrx_KaTSXR_r_N_Nc1TargetEqnMtrx_rt_Array_Float_27_6:0, KaTSXR_r_N_Nc1TargetEqnMtrx_KaTSXR_r_N_Nc1TargetEqnMtrx_rt_Array_Float_27_7:0, KaTSXR_r_N_Nc1TargetEqnMtrx_KaTSXR_r_N_Nc1TargetEqnMtrx_rt_Array_Float_27_8:0, KaTSXR_r_N_Nc1TargetEqnMtrx_KaTSXR_r_N_Nc1TargetEqnMtrx_rt_Array_Float_27_9:0, KaTSXR_r_N_Nc1TargetEqnMtrx_KaTSXR_r_N_Nc1TargetEqnMtrx_rt_Array_Float_27_10:0, KaTSXR_r_N_Nc1TargetEqnMtrx_KaTSXR_r_N_Nc1TargetEqnMtrx_rt_Array_Float_27_11:0, KaTSXR_r_N_Nc1TargetEqnMtrx_KaTSXR_r_N_Nc1TargetEqnMtrx_rt_Array_Float_27_12:0, KaTSXR_r_N_Nc1TargetEqnMtrx_KaTSXR_r_N_Nc1TargetEqnMtrx_rt_Array_Float_27_13:0, KaTSXR_r_N_Nc1TargetEqnMtrx_KaTSXR_r_N_Nc1TargetEqnMtrx_rt_Array_Float_27_14:0, KaTSXR_r_N_Nc1TargetEqnMtrx_KaTSXR_r_N_Nc1TargetEqnMtrx_rt_Array_Float_27_15:0, KaTSXR_r_N_Nc1TargetEqnMtrx_KaTSXR_r_N_Nc1TargetEqnMtrx_rt_Array_Float_27_16:0, KaTSXR_r_N_Nc1TargetEqnMtrx_KaTSXR_r_N_Nc1TargetEqnMtrx_rt_Array_Float_27_17:0, KaTSXR_r_N_Nc1TargetEqnMtrx_KaTSXR_r_N_Nc1TargetEqnMtrx_rt_Array_Float_27_18:0, KaTSXR_r_N_Nc1TargetEqnMtrx_KaTSXR_r_N_Nc1TargetEqnMtrx_rt_Array_Float_27_19:0, KaTSXR_r_N_Nc1TargetEqnMtrx_KaTSXR_r_N_Nc1TargetEqnMtrx_rt_Array_Float_27_20:0, KaTSXR_r_N_Nc1TargetEqnMtrx_KaTSXR_r_N_Nc1TargetEqnMtrx_rt_Array_Float_27_21:0, KaTSXR_r_N_Nc1TargetEqnMtrx_KaTSXR_r_N_Nc1TargetEqnMtrx_rt_Array_Float_27_22:0, KaTSXR_r_N_Nc1TargetEqnMtrx_KaTSXR_r_N_Nc1TargetEqnMtrx_rt_Array_Float_27_23:0, KaTSXR_r_N_Nc1TargetEqnMtrx_KaTSXR_r_N_Nc1TargetEqnMtrx_rt_Array_Float_27_24:0, KaTSXR_r_N_Nc1TargetEqnMtrx_KaTSXR_r_N_Nc1TargetEqnMtrx_rt_Array_Float_27_25:0, KaTSXR_r_N_Nc1TargetEqnMtrx_KaTSXR_r_N_Nc1TargetEqnMtrx_rt_Array_Float_27_26:0, KaTSXR_r_N_Nc1TargetEqnMtrx_KaTSXR_r_N_Nc1TargetEqnMtrx_rt_Array_Float_27_27:0], parameter=KaTSXR_r_N_Nc1TargetEqnMtrx}, required-interface=KaTSXR_r_N_Nc1TargetEqnMtrx
      KaTSXR_r_N_NcCalcEqnMtrx: parameter-require-com-spec{init-value=KaTSXR_r_N_NcCalcEqnMtrx_KaTSXR_r_N_NcCalcEqnMtrx:[KaTSXR_r_N_NcCalcEqnMtrx_KaTSXR_r_N_NcCalcEqnMtrx_rt_Array_Float_27_1:0, KaTSXR_r_N_NcCalcEqnMtrx_KaTSXR_r_N_NcCalcEqnMtrx_rt_Array_Float_27_2:0, KaTSXR_r_N_NcCalcEqnMtrx_KaTSXR_r_N_NcCalcEqnMtrx_rt_Array_Float_27_3:0, KaTSXR_r_N_NcCalcEqnMtrx_KaTSXR_r_N_NcCalcEqnMtrx_rt_Array_Float_27_4:0, KaTSXR_r_N_NcCalcEqnMtrx_KaTSXR_r_N_NcCalcEqnMtrx_rt_Array_Float_27_5:0, KaTSXR_r_N_NcCalcEqnMtrx_KaTSXR_r_N_NcCalcEqnMtrx_rt_Array_Float_27_6:0, KaTSXR_r_N_NcCalcEqnMtrx_KaTSXR_r_N_NcCalcEqnMtrx_rt_Array_Float_27_7:0, KaTSXR_r_N_NcCalcEqnMtrx_KaTSXR_r_N_NcCalcEqnMtrx_rt_Array_Float_27_8:0, KaTSXR_r_N_NcCalcEqnMtrx_KaTSXR_r_N_NcCalcEqnMtrx_rt_Array_Float_27_9:0, KaTSXR_r_N_NcCalcEqnMtrx_KaTSXR_r_N_NcCalcEqnMtrx_rt_Array_Float_27_10:0, KaTSXR_r_N_NcCalcEqnMtrx_KaTSXR_r_N_NcCalcEqnMtrx_rt_Array_Float_27_11:0, KaTSXR_r_N_NcCalcEqnMtrx_KaTSXR_r_N_NcCalcEqnMtrx_rt_Array_Float_27_12:0, KaTSXR_r_N_NcCalcEqnMtrx_KaTSXR_r_N_NcCalcEqnMtrx_rt_Array_Float_27_13:0, KaTSXR_r_N_NcCalcEqnMtrx_KaTSXR_r_N_NcCalcEqnMtrx_rt_Array_Float_27_14:0, KaTSXR_r_N_NcCalcEqnMtrx_KaTSXR_r_N_NcCalcEqnMtrx_rt_Array_Float_27_15:0, KaTSXR_r_N_NcCalcEqnMtrx_KaTSXR_r_N_NcCalcEqnMtrx_rt_Array_Float_27_16:0, KaTSXR_r_N_NcCalcEqnMtrx_KaTSXR_r_N_NcCalcEqnMtrx_rt_Array_Float_27_17:0, KaTSXR_r_N_NcCalcEqnMtrx_KaTSXR_r_N_NcCalcEqnMtrx_rt_Array_Float_27_18:0, KaTSXR_r_N_NcCalcEqnMtrx_KaTSXR_r_N_NcCalcEqnMtrx_rt_Array_Float_27_19:0, KaTSXR_r_N_NcCalcEqnMtrx_KaTSXR_r_N_NcCalcEqnMtrx_rt_Array_Float_27_20:0, KaTSXR_r_N_NcCalcEqnMtrx_KaTSXR_r_N_NcCalcEqnMtrx_rt_Array_Float_27_21:0, KaTSXR_r_N_NcCalcEqnMtrx_KaTSXR_r_N_NcCalcEqnMtrx_rt_Array_Float_27_22:0, KaTSXR_r_N_NcCalcEqnMtrx_KaTSXR_r_N_NcCalcEqnMtrx_rt_Array_Float_27_23:0, KaTSXR_r_N_NcCalcEqnMtrx_KaTSXR_r_N_NcCalcEqnMtrx_rt_Array_Float_27_24:0, KaTSXR_r_N_NcCalcEqnMtrx_KaTSXR_r_N_NcCalcEqnMtrx_rt_Array_Float_27_25:0, KaTSXR_r_N_NcCalcEqnMtrx_KaTSXR_r_N_NcCalcEqnMtrx_rt_Array_Float_27_26:0, KaTSXR_r_N_NcCalcEqnMtrx_KaTSXR_r_N_NcCalcEqnMtrx_rt_Array_Float_27_27:0], parameter=KaTSXR_r_N_NcCalcEqnMtrx}, required-interface=KaTSXR_r_N_NcCalcEqnMtrx
      KaTSXR_r_N_TM1_ToConstrn: parameter-require-com-spec{init-value=KaTSXR_r_N_TM1_ToConstrn_KaTSXR_r_N_TM1_ToConstrn:[KaTSXR_r_N_TM1_ToConstrn_KaTSXR_r_N_TM1_ToConstrn_rt_Array_Float_126_1:0, KaTSXR_r_N_TM1_ToConstrn_KaTSXR_r_N_TM1_ToConstrn_rt_Array_Float_126_2:0, KaTSXR_r_N_TM1_ToConstrn_KaTSXR_r_N_TM1_ToConstrn_rt_Array_Float_126_3:0, KaTSXR_r_N_TM1_ToConstrn_KaTSXR_r_N_TM1_ToConstrn_rt_Array_Float_126_4:0, KaTSXR_r_N_TM1_ToConstrn_KaTSXR_r_N_TM1_ToConstrn_rt_Array_Float_126_5:0, KaTSXR_r_N_TM1_ToConstrn_KaTSXR_r_N_TM1_ToConstrn_rt_Array_Float_126_6:0, KaTSXR_r_N_TM1_ToConstrn_KaTSXR_r_N_TM1_ToConstrn_rt_Array_Float_126_7:0, KaTSXR_r_N_TM1_ToConstrn_KaTSXR_r_N_TM1_ToConstrn_rt_Array_Float_126_8:0, KaTSXR_r_N_TM1_ToConstrn_KaTSXR_r_N_TM1_ToConstrn_rt_Array_Float_126_9:0, KaTSXR_r_N_TM1_ToConstrn_KaTSXR_r_N_TM1_ToConstrn_rt_Array_Float_126_10:0, KaTSXR_r_N_TM1_ToConstrn_KaTSXR_r_N_TM1_ToConstrn_rt_Array_Float_126_11:0, KaTSXR_r_N_TM1_ToConstrn_KaTSXR_r_N_TM1_ToConstrn_rt_Array_Float_126_12:0, KaTSXR_r_N_TM1_ToConstrn_KaTSXR_r_N_TM1_ToConstrn_rt_Array_Float_126_13:0, KaTSXR_r_N_TM1_ToConstrn_KaTSXR_r_N_TM1_ToConstrn_rt_Array_Float_126_14:0, KaTSXR_r_N_TM1_ToConstrn_KaTSXR_r_N_TM1_ToConstrn_rt_Array_Float_126_15:0, KaTSXR_r_N_TM1_ToConstrn_KaTSXR_r_N_TM1_ToConstrn_rt_Array_Float_126_16:0, KaTSXR_r_N_TM1_ToConstrn_KaTSXR_r_N_TM1_ToConstrn_rt_Array_Float_126_17:0, KaTSXR_r_N_TM1_ToConstrn_KaTSXR_r_N_TM1_ToConstrn_rt_Array_Float_126_18:0, KaTSXR_r_N_TM1_ToConstrn_KaTSXR_r_N_TM1_ToConstrn_rt_Array_Float_126_19:0, KaTSXR_r_N_TM1_ToConstrn_KaTSXR_r_N_TM1_ToConstrn_rt_Array_Float_126_20:0, KaTSXR_r_N_TM1_ToConstrn_KaTSXR_r_N_TM1_ToConstrn_rt_Array_Float_126_21:0, KaTSXR_r_N_TM1_ToConstrn_KaTSXR_r_N_TM1_ToConstrn_rt_Array_Float_126_22:0, KaTSXR_r_N_TM1_ToConstrn_KaTSXR_r_N_TM1_ToConstrn_rt_Array_Float_126_23:0, KaTSXR_r_N_TM1_ToConstrn_KaTSXR_r_N_TM1_ToConstrn_rt_Array_Float_126_24:0, KaTSXR_r_N_TM1_ToConstrn_KaTSXR_r_N_TM1_ToConstrn_rt_Array_Float_126_25:0, KaTSXR_r_N_TM1_ToConstrn_KaTSXR_r_N_TM1_ToConstrn_rt_Array_Float_126_26:0, KaTSXR_r_N_TM1_ToConstrn_KaTSXR_r_N_TM1_ToConstrn_rt_Array_Float_126_27:0, KaTSXR_r_N_TM1_ToConstrn_KaTSXR_r_N_TM1_ToConstrn_rt_Array_Float_126_28:0, KaTSXR_r_N_TM1_ToConstrn_KaTSXR_r_N_TM1_ToConstrn_rt_Array_Float_126_29:0, KaTSXR_r_N_TM1_ToConstrn_KaTSXR_r_N_TM1_ToConstrn_rt_Array_Float_126_30:0, KaTSXR_r_N_TM1_ToConstrn_KaTSXR_r_N_TM1_ToConstrn_rt_Array_Float_126_31:0, KaTSXR_r_N_TM1_ToConstrn_KaTSXR_r_N_TM1_ToConstrn_rt_Array_Float_126_32:0, KaTSXR_r_N_TM1_ToConstrn_KaTSXR_r_N_TM1_ToConstrn_rt_Array_Float_126_33:0, KaTSXR_r_N_TM1_ToConstrn_KaTSXR_r_N_TM1_ToConstrn_rt_Array_Float_126_34:0, KaTSXR_r_N_TM1_ToConstrn_KaTSXR_r_N_TM1_ToConstrn_rt_Array_Float_126_35:0, KaTSXR_r_N_TM1_ToConstrn_KaTSXR_r_N_TM1_ToConstrn_rt_Array_Float_126_36:0, KaTSXR_r_N_TM1_ToConstrn_KaTSXR_r_N_TM1_ToConstrn_rt_Array_Float_126_37:0, KaTSXR_r_N_TM1_ToConstrn_KaTSXR_r_N_TM1_ToConstrn_rt_Array_Float_126_38:0, KaTSXR_r_N_TM1_ToConstrn_KaTSXR_r_N_TM1_ToConstrn_rt_Array_Float_126_39:0, KaTSXR_r_N_TM1_ToConstrn_KaTSXR_r_N_TM1_ToConstrn_rt_Array_Float_126_40:0, KaTSXR_r_N_TM1_ToConstrn_KaTSXR_r_N_TM1_ToConstrn_rt_Array_Float_126_41:0, KaTSXR_r_N_TM1_ToConstrn_KaTSXR_r_N_TM1_ToConstrn_rt_Array_Float_126_42:0, KaTSXR_r_N_TM1_ToConstrn_KaTSXR_r_N_TM1_ToConstrn_rt_Array_Float_126_43:0, KaTSXR_r_N_TM1_ToConstrn_KaTSXR_r_N_TM1_ToConstrn_rt_Array_Float_126_44:0, KaTSXR_r_N_TM1_ToConstrn_KaTSXR_r_N_TM1_ToConstrn_rt_Array_Float_126_45:0, KaTSXR_r_N_TM1_ToConstrn_KaTSXR_r_N_TM1_ToConstrn_rt_Array_Float_126_46:0, KaTSXR_r_N_TM1_ToConstrn_KaTSXR_r_N_TM1_ToConstrn_rt_Array_Float_126_47:0, KaTSXR_r_N_TM1_ToConstrn_KaTSXR_r_N_TM1_ToConstrn_rt_Array_Float_126_48:0, KaTSXR_r_N_TM1_ToConstrn_KaTSXR_r_N_TM1_ToConstrn_rt_Array_Float_126_49:0, KaTSXR_r_N_TM1_ToConstrn_KaTSXR_r_N_TM1_ToConstrn_rt_Array_Float_126_50:0, KaTSXR_r_N_TM1_ToConstrn_KaTSXR_r_N_TM1_ToConstrn_rt_Array_Float_126_51:0, KaTSXR_r_N_TM1_ToConstrn_KaTSXR_r_N_TM1_ToConstrn_rt_Array_Float_126_52:0, KaTSXR_r_N_TM1_ToConstrn_KaTSXR_r_N_TM1_ToConstrn_rt_Array_Float_126_53:0, KaTSXR_r_N_TM1_ToConstrn_KaTSXR_r_N_TM1_ToConstrn_rt_Array_Float_126_54:0, KaTSXR_r_N_TM1_ToConstrn_KaTSXR_r_N_TM1_ToConstrn_rt_Array_Float_126_55:0, KaTSXR_r_N_TM1_ToConstrn_KaTSXR_r_N_TM1_ToConstrn_rt_Array_Float_126_56:0, KaTSXR_r_N_TM1_ToConstrn_KaTSXR_r_N_TM1_ToConstrn_rt_Array_Float_126_57:0, KaTSXR_r_N_TM1_ToConstrn_KaTSXR_r_N_TM1_ToConstrn_rt_Array_Float_126_58:0, KaTSXR_r_N_TM1_ToConstrn_KaTSXR_r_N_TM1_ToConstrn_rt_Array_Float_126_59:0, KaTSXR_r_N_TM1_ToConstrn_KaTSXR_r_N_TM1_ToConstrn_rt_Array_Float_126_60:0, KaTSXR_r_N_TM1_ToConstrn_KaTSXR_r_N_TM1_ToConstrn_rt_Array_Float_126_61:0, KaTSXR_r_N_TM1_ToConstrn_KaTSXR_r_N_TM1_ToConstrn_rt_Array_Float_126_62:0, KaTSXR_r_N_TM1_ToConstrn_KaTSXR_r_N_TM1_ToConstrn_rt_Array_Float_126_63:0, KaTSXR_r_N_TM1_ToConstrn_KaTSXR_r_N_TM1_ToConstrn_rt_Array_Float_126_64:0, KaTSXR_r_N_TM1_ToConstrn_KaTSXR_r_N_TM1_ToConstrn_rt_Array_Float_126_65:0, KaTSXR_r_N_TM1_ToConstrn_KaTSXR_r_N_TM1_ToConstrn_rt_Array_Float_126_66:0, KaTSXR_r_N_TM1_ToConstrn_KaTSXR_r_N_TM1_ToConstrn_rt_Array_Float_126_67:0, KaTSXR_r_N_TM1_ToConstrn_KaTSXR_r_N_TM1_ToConstrn_rt_Array_Float_126_68:0, KaTSXR_r_N_TM1_ToConstrn_KaTSXR_r_N_TM1_ToConstrn_rt_Array_Float_126_69:0, KaTSXR_r_N_TM1_ToConstrn_KaTSXR_r_N_TM1_ToConstrn_rt_Array_Float_126_70:0, KaTSXR_r_N_TM1_ToConstrn_KaTSXR_r_N_TM1_ToConstrn_rt_Array_Float_126_71:0, KaTSXR_r_N_TM1_ToConstrn_KaTSXR_r_N_TM1_ToConstrn_rt_Array_Float_126_72:0, KaTSXR_r_N_TM1_ToConstrn_KaTSXR_r_N_TM1_ToConstrn_rt_Array_Float_126_73:0, KaTSXR_r_N_TM1_ToConstrn_KaTSXR_r_N_TM1_ToConstrn_rt_Array_Float_126_74:0, KaTSXR_r_N_TM1_ToConstrn_KaTSXR_r_N_TM1_ToConstrn_rt_Array_Float_126_75:0, KaTSXR_r_N_TM1_ToConstrn_KaTSXR_r_N_TM1_ToConstrn_rt_Array_Float_126_76:0, KaTSXR_r_N_TM1_ToConstrn_KaTSXR_r_N_TM1_ToConstrn_rt_Array_Float_126_77:0, KaTSXR_r_N_TM1_ToConstrn_KaTSXR_r_N_TM1_ToConstrn_rt_Array_Float_126_78:0, KaTSXR_r_N_TM1_ToConstrn_KaTSXR_r_N_TM1_ToConstrn_rt_Array_Float_126_79:0, KaTSXR_r_N_TM1_ToConstrn_KaTSXR_r_N_TM1_ToConstrn_rt_Array_Float_126_80:0, KaTSXR_r_N_TM1_ToConstrn_KaTSXR_r_N_TM1_ToConstrn_rt_Array_Float_126_81:0, KaTSXR_r_N_TM1_ToConstrn_KaTSXR_r_N_TM1_ToConstrn_rt_Array_Float_126_82:0, KaTSXR_r_N_TM1_ToConstrn_KaTSXR_r_N_TM1_ToConstrn_rt_Array_Float_126_83:0, KaTSXR_r_N_TM1_ToConstrn_KaTSXR_r_N_TM1_ToConstrn_rt_Array_Float_126_84:0, KaTSXR_r_N_TM1_ToConstrn_KaTSXR_r_N_TM1_ToConstrn_rt_Array_Float_126_85:0, KaTSXR_r_N_TM1_ToConstrn_KaTSXR_r_N_TM1_ToConstrn_rt_Array_Float_126_86:0, KaTSXR_r_N_TM1_ToConstrn_KaTSXR_r_N_TM1_ToConstrn_rt_Array_Float_126_87:0, KaTSXR_r_N_TM1_ToConstrn_KaTSXR_r_N_TM1_ToConstrn_rt_Array_Float_126_88:0, KaTSXR_r_N_TM1_ToConstrn_KaTSXR_r_N_TM1_ToConstrn_rt_Array_Float_126_89:0, KaTSXR_r_N_TM1_ToConstrn_KaTSXR_r_N_TM1_ToConstrn_rt_Array_Float_126_90:0, KaTSXR_r_N_TM1_ToConstrn_KaTSXR_r_N_TM1_ToConstrn_rt_Array_Float_126_91:0, KaTSXR_r_N_TM1_ToConstrn_KaTSXR_r_N_TM1_ToConstrn_rt_Array_Float_126_92:0, KaTSXR_r_N_TM1_ToConstrn_KaTSXR_r_N_TM1_ToConstrn_rt_Array_Float_126_93:0, KaTSXR_r_N_TM1_ToConstrn_KaTSXR_r_N_TM1_ToConstrn_rt_Array_Float_126_94:0, KaTSXR_r_N_TM1_ToConstrn_KaTSXR_r_N_TM1_ToConstrn_rt_Array_Float_126_95:0, KaTSXR_r_N_TM1_ToConstrn_KaTSXR_r_N_TM1_ToConstrn_rt_Array_Float_126_96:0, KaTSXR_r_N_TM1_ToConstrn_KaTSXR_r_N_TM1_ToConstrn_rt_Array_Float_126_97:0, KaTSXR_r_N_TM1_ToConstrn_KaTSXR_r_N_TM1_ToConstrn_rt_Array_Float_126_98:0, KaTSXR_r_N_TM1_ToConstrn_KaTSXR_r_N_TM1_ToConstrn_rt_Array_Float_126_99:0, KaTSXR_r_N_TM1_ToConstrn_KaTSXR_r_N_TM1_ToConstrn_rt_Array_Float_126_100:0, KaTSXR_r_N_TM1_ToConstrn_KaTSXR_r_N_TM1_ToConstrn_rt_Array_Float_126_101:0, KaTSXR_r_N_TM1_ToConstrn_KaTSXR_r_N_TM1_ToConstrn_rt_Array_Float_126_102:0, KaTSXR_r_N_TM1_ToConstrn_KaTSXR_r_N_TM1_ToConstrn_rt_Array_Float_126_103:0, KaTSXR_r_N_TM1_ToConstrn_KaTSXR_r_N_TM1_ToConstrn_rt_Array_Float_126_104:0, KaTSXR_r_N_TM1_ToConstrn_KaTSXR_r_N_TM1_ToConstrn_rt_Array_Float_126_105:0, KaTSXR_r_N_TM1_ToConstrn_KaTSXR_r_N_TM1_ToConstrn_rt_Array_Float_126_106:0, KaTSXR_r_N_TM1_ToConstrn_KaTSXR_r_N_TM1_ToConstrn_rt_Array_Float_126_107:0, KaTSXR_r_N_TM1_ToConstrn_KaTSXR_r_N_TM1_ToConstrn_rt_Array_Float_126_108:0, KaTSXR_r_N_TM1_ToConstrn_KaTSXR_r_N_TM1_ToConstrn_rt_Array_Float_126_109:0, KaTSXR_r_N_TM1_ToConstrn_KaTSXR_r_N_TM1_ToConstrn_rt_Array_Float_126_110:0, KaTSXR_r_N_TM1_ToConstrn_KaTSXR_r_N_TM1_ToConstrn_rt_Array_Float_126_111:0, KaTSXR_r_N_TM1_ToConstrn_KaTSXR_r_N_TM1_ToConstrn_rt_Array_Float_126_112:0, KaTSXR_r_N_TM1_ToConstrn_KaTSXR_r_N_TM1_ToConstrn_rt_Array_Float_126_113:0, KaTSXR_r_N_TM1_ToConstrn_KaTSXR_r_N_TM1_ToConstrn_rt_Array_Float_126_114:0, KaTSXR_r_N_TM1_ToConstrn_KaTSXR_r_N_TM1_ToConstrn_rt_Array_Float_126_115:0, KaTSXR_r_N_TM1_ToConstrn_KaTSXR_r_N_TM1_ToConstrn_rt_Array_Float_126_116:0, KaTSXR_r_N_TM1_ToConstrn_KaTSXR_r_N_TM1_ToConstrn_rt_Array_Float_126_117:0, KaTSXR_r_N_TM1_ToConstrn_KaTSXR_r_N_TM1_ToConstrn_rt_Array_Float_126_118:0, KaTSXR_r_N_TM1_ToConstrn_KaTSXR_r_N_TM1_ToConstrn_rt_Array_Float_126_119:0, KaTSXR_r_N_TM1_ToConstrn_KaTSXR_r_N_TM1_ToConstrn_rt_Array_Float_126_120:0, KaTSXR_r_N_TM1_ToConstrn_KaTSXR_r_N_TM1_ToConstrn_rt_Array_Float_126_121:0, KaTSXR_r_N_TM1_ToConstrn_KaTSXR_r_N_TM1_ToConstrn_rt_Array_Float_126_122:0, KaTSXR_r_N_TM1_ToConstrn_KaTSXR_r_N_TM1_ToConstrn_rt_Array_Float_126_123:0, KaTSXR_r_N_TM1_ToConstrn_KaTSXR_r_N_TM1_ToConstrn_rt_Array_Float_126_124:0, KaTSXR_r_N_TM1_ToConstrn_KaTSXR_r_N_TM1_ToConstrn_rt_Array_Float_126_125:0, KaTSXR_r_N_TM1_ToConstrn_KaTSXR_r_N_TM1_ToConstrn_rt_Array_Float_126_126:0], parameter=KaTSXR_r_N_TM1_ToConstrn}, required-interface=KaTSXR_r_N_TM1_ToConstrn
      KeHSCR_M_Adher_Limiting: parameter-require-com-spec{init-value=KeHSCR_M_Adher_Limiting_KeHSCR_M_Adher_Limiting:5, parameter=KeHSCR_M_Adher_Limiting}, required-interface=KeHSCR_M_Adher_Limiting
      KeHSCR_M_Adherence_LSP: parameter-require-com-spec{init-value=KeHSCR_M_Adherence_LSP_KeHSCR_M_Adherence_LSP:1, parameter=KeHSCR_M_Adherence_LSP}, required-interface=KeHSCR_M_Adherence_LSP
      KeHSCR_M_Adherence_RSP: parameter-require-com-spec{init-value=KeHSCR_M_Adherence_RSP_KeHSCR_M_Adherence_RSP:10, parameter=KeHSCR_M_Adherence_RSP}, required-interface=KeHSCR_M_Adherence_RSP
      KeHSCR_k_AdherenceFilt: parameter-require-com-spec{init-value=KeHSCR_k_AdherenceFilt_KeHSCR_k_AdherenceFilt:0.200000002980232, parameter=KeHSCR_k_AdherenceFilt}, required-interface=KeHSCR_k_AdherenceFilt
      KeHSCR_k_FiltCoeffFrnt_LowMu: parameter-require-com-spec{init-value=KeHSCR_k_FiltCoeffFrnt_LowMu_KeHSCR_k_FiltCoeffFrnt_LowMu:0.100000001490116, parameter=KeHSCR_k_FiltCoeffFrnt_LowMu}, required-interface=KeHSCR_k_FiltCoeffFrnt_LowMu
      KeHSCR_k_FiltCoeffRear_LowMu: parameter-require-com-spec{init-value=KeHSCR_k_FiltCoeffRear_LowMu_KeHSCR_k_FiltCoeffRear_LowMu:0.100000001490116, parameter=KeHSCR_k_FiltCoeffRear_LowMu}, required-interface=KeHSCR_k_FiltCoeffRear_LowMu
      KeOPTR_M_P2ZeroIdle_2Pdl_BrkTrq_LSP: parameter-require-com-spec{init-value=KeOPTR_M_P2ZeroIdle_2Pdl_BrkTrq_LSP_KeOPTR_M_P2ZeroIdle_2Pdl_BrkTrq_LSP:-50, parameter=KeOPTR_M_P2ZeroIdle_2Pdl_BrkTrq_LSP}, required-interface=KeOPTR_M_P2ZeroIdle_2Pdl_BrkTrq_LSP
      KeOPTR_M_P2ZeroIdle_2Pdl_BrkTrq_RSP: parameter-require-com-spec{init-value=KeOPTR_M_P2ZeroIdle_2Pdl_BrkTrq_RSP_KeOPTR_M_P2ZeroIdle_2Pdl_BrkTrq_RSP:-30, parameter=KeOPTR_M_P2ZeroIdle_2Pdl_BrkTrq_RSP}, required-interface=KeOPTR_M_P2ZeroIdle_2Pdl_BrkTrq_RSP
      KeOPTR_M_P2ZeroIdle_BrkTrqMin_RSP_OS: parameter-require-com-spec{init-value=KeOPTR_M_P2ZeroIdle_BrkTrqMin_RSP_OS_KeOPTR_M_P2ZeroIdle_BrkTrqMin_RSP_OS:30, parameter=KeOPTR_M_P2ZeroIdle_BrkTrqMin_RSP_OS}, required-interface=KeOPTR_M_P2ZeroIdle_BrkTrqMin_RSP_OS
      KeOPTR_Pct_P2ZeroIdle_2Pdl_Acl_LSP: parameter-require-com-spec{init-value=KeOPTR_Pct_P2ZeroIdle_2Pdl_Acl_LSP_KeOPTR_Pct_P2ZeroIdle_2Pdl_Acl_LSP:1, parameter=KeOPTR_Pct_P2ZeroIdle_2Pdl_Acl_LSP}, required-interface=KeOPTR_Pct_P2ZeroIdle_2Pdl_Acl_LSP
      KeOPTR_Pct_P2ZeroIdle_2Pdl_Acl_RSP: parameter-require-com-spec{init-value=KeOPTR_Pct_P2ZeroIdle_2Pdl_Acl_RSP_KeOPTR_Pct_P2ZeroIdle_2Pdl_Acl_RSP:0, parameter=KeOPTR_Pct_P2ZeroIdle_2Pdl_Acl_RSP}, required-interface=KeOPTR_Pct_P2ZeroIdle_2Pdl_Acl_RSP
      KeOPTR_n_P2Idle_ZeroRPM: parameter-require-com-spec{init-value=KeOPTR_n_P2Idle_ZeroRPM_KeOPTR_n_P2Idle_ZeroRPM:0, parameter=KeOPTR_n_P2Idle_ZeroRPM}, required-interface=KeOPTR_n_P2Idle_ZeroRPM
      KeOPTR_n_P2MinIdle_TransMinSpd_LSP: parameter-require-com-spec{init-value=KeOPTR_n_P2MinIdle_TransMinSpd_LSP_KeOPTR_n_P2MinIdle_TransMinSpd_LSP:0.25, parameter=KeOPTR_n_P2MinIdle_TransMinSpd_LSP}, required-interface=KeOPTR_n_P2MinIdle_TransMinSpd_LSP
      KeOPTR_n_P2MinIdle_TransMinSpd_RSP: parameter-require-com-spec{init-value=KeOPTR_n_P2MinIdle_TransMinSpd_RSP_KeOPTR_n_P2MinIdle_TransMinSpd_RSP:0.5, parameter=KeOPTR_n_P2MinIdle_TransMinSpd_RSP}, required-interface=KeOPTR_n_P2MinIdle_TransMinSpd_RSP
      KeOPTR_n_P2ZeroIdle_NoMax_LSP: parameter-require-com-spec{init-value=KeOPTR_n_P2ZeroIdle_NoMax_LSP_KeOPTR_n_P2ZeroIdle_NoMax_LSP:20, parameter=KeOPTR_n_P2ZeroIdle_NoMax_LSP}, required-interface=KeOPTR_n_P2ZeroIdle_NoMax_LSP
      KeOPTR_n_P2ZeroIdle_NoMax_RSP: parameter-require-com-spec{init-value=KeOPTR_n_P2ZeroIdle_NoMax_RSP_KeOPTR_n_P2ZeroIdle_NoMax_RSP:25, parameter=KeOPTR_n_P2ZeroIdle_NoMax_RSP}, required-interface=KeOPTR_n_P2ZeroIdle_NoMax_RSP
      KeOPTR_n_RGS_ActivationThreshold: parameter-require-com-spec{init-value=KeOPTR_n_RGS_ActivationThreshold_KeOPTR_n_RGS_ActivationThreshold:500, parameter=KeOPTR_n_RGS_ActivationThreshold}, required-interface=KeOPTR_n_RGS_ActivationThreshold
      KeOPTR_n_RGS_IdleSpd: parameter-require-com-spec{init-value=KeOPTR_n_RGS_IdleSpd_KeOPTR_n_RGS_IdleSpd:950, parameter=KeOPTR_n_RGS_IdleSpd}, required-interface=KeOPTR_n_RGS_IdleSpd
      KeOPTR_r_NiTiFctrMin: parameter-require-com-spec{init-value=KeOPTR_r_NiTiFctrMin_KeOPTR_r_NiTiFctrMin:0.00999999977648258, parameter=KeOPTR_r_NiTiFctrMin}, required-interface=KeOPTR_r_NiTiFctrMin
      KeOPTR_t_BrkTrq_TstDer_CutOffT: parameter-require-com-spec{init-value=KeOPTR_t_BrkTrq_TstDer_CutOffT_KeOPTR_t_BrkTrq_TstDer_CutOffT:0.100000001490116, parameter=KeOPTR_t_BrkTrq_TstDer_CutOffT}, required-interface=KeOPTR_t_BrkTrq_TstDer_CutOffT
      KeOPTR_t_DelayTimeToggle: parameter-require-com-spec{init-value=KeOPTR_t_DelayTimeToggle_KeOPTR_t_DelayTimeToggle:10, parameter=KeOPTR_t_DelayTimeToggle}, required-interface=KeOPTR_t_DelayTimeToggle
      KeOPTR_t_RGS_Delay: parameter-require-com-spec{init-value=KeOPTR_t_RGS_Delay_KeOPTR_t_RGS_Delay:1, parameter=KeOPTR_t_RGS_Delay}, required-interface=KeOPTR_t_RGS_Delay
      KeOPTR_t_RGS_DelayTimeNTurb: parameter-require-com-spec{init-value=KeOPTR_t_RGS_DelayTimeNTurb_KeOPTR_t_RGS_DelayTimeNTurb:5, parameter=KeOPTR_t_RGS_DelayTimeNTurb}, required-interface=KeOPTR_t_RGS_DelayTimeNTurb
      KeTSXR_r_All_FDRratio: parameter-require-com-spec{init-value=KeTSXR_r_All_FDRratio_KeTSXR_r_All_FDRratio:3.64023876190186, parameter=KeTSXR_r_All_FDRratio}, required-interface=KeTSXR_r_All_FDRratio
      KeHSCR_dM_LowMuFact_LD: parameter-require-com-spec{init-value=KeHSCR_dM_LowMuFact_LD_KeHSCR_dM_LowMuFact_LD:-50, parameter=KeHSCR_dM_LowMuFact_LD}, required-interface=KeHSCR_dM_LowMuFact_LD
      KeHSCR_dM_LowMuRmpOutFrnt: parameter-require-com-spec{init-value=KeHSCR_dM_LowMuRmpOutFrnt_KeHSCR_dM_LowMuRmpOutFrnt:-50, parameter=KeHSCR_dM_LowMuRmpOutFrnt}, required-interface=KeHSCR_dM_LowMuRmpOutFrnt
      KeHSCR_dM_LowMuRmpOutRr: parameter-require-com-spec{init-value=KeHSCR_dM_LowMuRmpOutRr_KeHSCR_dM_LowMuRmpOutRr:-50, parameter=KeHSCR_dM_LowMuRmpOutRr}, required-interface=KeHSCR_dM_LowMuRmpOutRr
      KeHSCR_M_LowMuRmpEndLmt: parameter-require-com-spec{init-value=KeHSCR_M_LowMuRmpEndLmt_KeHSCR_M_LowMuRmpEndLmt:150, parameter=KeHSCR_M_LowMuRmpEndLmt}, required-interface=KeHSCR_M_LowMuRmpEndLmt
      KeHSCR_n_LowMuEndFrntTrq: parameter-require-com-spec{init-value=KeHSCR_n_LowMuEndFrntTrq_KeHSCR_n_LowMuEndFrntTrq:730, parameter=KeHSCR_n_LowMuEndFrntTrq}, required-interface=KeHSCR_n_LowMuEndFrntTrq
      KeHSCR_n_LowMuEndRearTrq: parameter-require-com-spec{init-value=KeHSCR_n_LowMuEndRearTrq_KeHSCR_n_LowMuEndRearTrq:730, parameter=KeHSCR_n_LowMuEndRearTrq}, required-interface=KeHSCR_n_LowMuEndRearTrq
      HaTSXR_b_EVM_NoEqn1Mtrx: parameter-require-com-spec{init-value=HaTSXR_b_EVM_NoEqn1Mtrx_HaTSXR_b_EVM_NoEqn1Mtrx:[HaTSXR_b_EVM_NoEqn1Mtrx_HaTSXR_b_EVM_NoEqn1Mtrx_rt_Array_Boolean_9_1:1, HaTSXR_b_EVM_NoEqn1Mtrx_HaTSXR_b_EVM_NoEqn1Mtrx_rt_Array_Boolean_9_2:0, HaTSXR_b_EVM_NoEqn1Mtrx_HaTSXR_b_EVM_NoEqn1Mtrx_rt_Array_Boolean_9_3:0, HaTSXR_b_EVM_NoEqn1Mtrx_HaTSXR_b_EVM_NoEqn1Mtrx_rt_Array_Boolean_9_4:0, HaTSXR_b_EVM_NoEqn1Mtrx_HaTSXR_b_EVM_NoEqn1Mtrx_rt_Array_Boolean_9_5:0, HaTSXR_b_EVM_NoEqn1Mtrx_HaTSXR_b_EVM_NoEqn1Mtrx_rt_Array_Boolean_9_6:0, HaTSXR_b_EVM_NoEqn1Mtrx_HaTSXR_b_EVM_NoEqn1Mtrx_rt_Array_Boolean_9_7:0, HaTSXR_b_EVM_NoEqn1Mtrx_HaTSXR_b_EVM_NoEqn1Mtrx_rt_Array_Boolean_9_8:0, HaTSXR_b_EVM_NoEqn1Mtrx_HaTSXR_b_EVM_NoEqn1Mtrx_rt_Array_Boolean_9_9:0], parameter=HaTSXR_b_EVM_NoEqn1Mtrx}, required-interface=HaTSXR_b_EVM_NoEqn1Mtrx
      HaTSXR_b_EVM_NoEqn2Mtrx: parameter-require-com-spec{init-value=HaTSXR_b_EVM_NoEqn2Mtrx_HaTSXR_b_EVM_NoEqn2Mtrx:[HaTSXR_b_EVM_NoEqn2Mtrx_HaTSXR_b_EVM_NoEqn2Mtrx_rt_Array_Boolean_9_1:1, HaTSXR_b_EVM_NoEqn2Mtrx_HaTSXR_b_EVM_NoEqn2Mtrx_rt_Array_Boolean_9_2:0, HaTSXR_b_EVM_NoEqn2Mtrx_HaTSXR_b_EVM_NoEqn2Mtrx_rt_Array_Boolean_9_3:0, HaTSXR_b_EVM_NoEqn2Mtrx_HaTSXR_b_EVM_NoEqn2Mtrx_rt_Array_Boolean_9_4:0, HaTSXR_b_EVM_NoEqn2Mtrx_HaTSXR_b_EVM_NoEqn2Mtrx_rt_Array_Boolean_9_5:0, HaTSXR_b_EVM_NoEqn2Mtrx_HaTSXR_b_EVM_NoEqn2Mtrx_rt_Array_Boolean_9_6:0, HaTSXR_b_EVM_NoEqn2Mtrx_HaTSXR_b_EVM_NoEqn2Mtrx_rt_Array_Boolean_9_7:0, HaTSXR_b_EVM_NoEqn2Mtrx_HaTSXR_b_EVM_NoEqn2Mtrx_rt_Array_Boolean_9_8:0, HaTSXR_b_EVM_NoEqn2Mtrx_HaTSXR_b_EVM_NoEqn2Mtrx_rt_Array_Boolean_9_9:0], parameter=HaTSXR_b_EVM_NoEqn2Mtrx}, required-interface=HaTSXR_b_EVM_NoEqn2Mtrx
      HaTSXR_b_EVM_NtiEqn1Mtrx: parameter-require-com-spec{init-value=HaTSXR_b_EVM_NtiEqn1Mtrx_HaTSXR_b_EVM_NtiEqn1Mtrx:[HaTSXR_b_EVM_NtiEqn1Mtrx_HaTSXR_b_EVM_NtiEqn1Mtrx_rt_Array_Boolean_9_1:0, HaTSXR_b_EVM_NtiEqn1Mtrx_HaTSXR_b_EVM_NtiEqn1Mtrx_rt_Array_Boolean_9_2:0, HaTSXR_b_EVM_NtiEqn1Mtrx_HaTSXR_b_EVM_NtiEqn1Mtrx_rt_Array_Boolean_9_3:0, HaTSXR_b_EVM_NtiEqn1Mtrx_HaTSXR_b_EVM_NtiEqn1Mtrx_rt_Array_Boolean_9_4:0, HaTSXR_b_EVM_NtiEqn1Mtrx_HaTSXR_b_EVM_NtiEqn1Mtrx_rt_Array_Boolean_9_5:0, HaTSXR_b_EVM_NtiEqn1Mtrx_HaTSXR_b_EVM_NtiEqn1Mtrx_rt_Array_Boolean_9_6:0, HaTSXR_b_EVM_NtiEqn1Mtrx_HaTSXR_b_EVM_NtiEqn1Mtrx_rt_Array_Boolean_9_7:0, HaTSXR_b_EVM_NtiEqn1Mtrx_HaTSXR_b_EVM_NtiEqn1Mtrx_rt_Array_Boolean_9_8:0, HaTSXR_b_EVM_NtiEqn1Mtrx_HaTSXR_b_EVM_NtiEqn1Mtrx_rt_Array_Boolean_9_9:0], parameter=HaTSXR_b_EVM_NtiEqn1Mtrx}, required-interface=HaTSXR_b_EVM_NtiEqn1Mtrx
      HaTSXR_b_EVM_NtiEqn2Mtrx: parameter-require-com-spec{init-value=HaTSXR_b_EVM_NtiEqn2Mtrx_HaTSXR_b_EVM_NtiEqn2Mtrx:[HaTSXR_b_EVM_NtiEqn2Mtrx_HaTSXR_b_EVM_NtiEqn2Mtrx_rt_Array_Boolean_9_1:0, HaTSXR_b_EVM_NtiEqn2Mtrx_HaTSXR_b_EVM_NtiEqn2Mtrx_rt_Array_Boolean_9_2:0, HaTSXR_b_EVM_NtiEqn2Mtrx_HaTSXR_b_EVM_NtiEqn2Mtrx_rt_Array_Boolean_9_3:0, HaTSXR_b_EVM_NtiEqn2Mtrx_HaTSXR_b_EVM_NtiEqn2Mtrx_rt_Array_Boolean_9_4:0, HaTSXR_b_EVM_NtiEqn2Mtrx_HaTSXR_b_EVM_NtiEqn2Mtrx_rt_Array_Boolean_9_5:0, HaTSXR_b_EVM_NtiEqn2Mtrx_HaTSXR_b_EVM_NtiEqn2Mtrx_rt_Array_Boolean_9_6:0, HaTSXR_b_EVM_NtiEqn2Mtrx_HaTSXR_b_EVM_NtiEqn2Mtrx_rt_Array_Boolean_9_7:0, HaTSXR_b_EVM_NtiEqn2Mtrx_HaTSXR_b_EVM_NtiEqn2Mtrx_rt_Array_Boolean_9_8:0, HaTSXR_b_EVM_NtiEqn2Mtrx_HaTSXR_b_EVM_NtiEqn2Mtrx_rt_Array_Boolean_9_9:0], parameter=HaTSXR_b_EVM_NtiEqn2Mtrx}, required-interface=HaTSXR_b_EVM_NtiEqn2Mtrx
      HaTSXR_b_EVN_Nc1Eqn2Mtrx: parameter-require-com-spec{init-value=HaTSXR_b_EVN_Nc1Eqn2Mtrx_HaTSXR_b_EVN_Nc1Eqn2Mtrx:[HaTSXR_b_EVN_Nc1Eqn2Mtrx_HaTSXR_b_EVN_Nc1Eqn2Mtrx_rt_Array_Boolean_9_1:0, HaTSXR_b_EVN_Nc1Eqn2Mtrx_HaTSXR_b_EVN_Nc1Eqn2Mtrx_rt_Array_Boolean_9_2:0, HaTSXR_b_EVN_Nc1Eqn2Mtrx_HaTSXR_b_EVN_Nc1Eqn2Mtrx_rt_Array_Boolean_9_3:0, HaTSXR_b_EVN_Nc1Eqn2Mtrx_HaTSXR_b_EVN_Nc1Eqn2Mtrx_rt_Array_Boolean_9_4:0, HaTSXR_b_EVN_Nc1Eqn2Mtrx_HaTSXR_b_EVN_Nc1Eqn2Mtrx_rt_Array_Boolean_9_5:0, HaTSXR_b_EVN_Nc1Eqn2Mtrx_HaTSXR_b_EVN_Nc1Eqn2Mtrx_rt_Array_Boolean_9_6:0, HaTSXR_b_EVN_Nc1Eqn2Mtrx_HaTSXR_b_EVN_Nc1Eqn2Mtrx_rt_Array_Boolean_9_7:0, HaTSXR_b_EVN_Nc1Eqn2Mtrx_HaTSXR_b_EVN_Nc1Eqn2Mtrx_rt_Array_Boolean_9_8:0, HaTSXR_b_EVN_Nc1Eqn2Mtrx_HaTSXR_b_EVN_Nc1Eqn2Mtrx_rt_Array_Boolean_9_9:0], parameter=HaTSXR_b_EVN_Nc1Eqn2Mtrx}, required-interface=HaTSXR_b_EVN_Nc1Eqn2Mtrx
      HaTSXR_b_EVN_NoEqn1Mtrx: parameter-require-com-spec{init-value=HaTSXR_b_EVN_NoEqn1Mtrx_HaTSXR_b_EVN_NoEqn1Mtrx:[HaTSXR_b_EVN_NoEqn1Mtrx_HaTSXR_b_EVN_NoEqn1Mtrx_rt_Array_Boolean_9_1:1, HaTSXR_b_EVN_NoEqn1Mtrx_HaTSXR_b_EVN_NoEqn1Mtrx_rt_Array_Boolean_9_2:0, HaTSXR_b_EVN_NoEqn1Mtrx_HaTSXR_b_EVN_NoEqn1Mtrx_rt_Array_Boolean_9_3:0, HaTSXR_b_EVN_NoEqn1Mtrx_HaTSXR_b_EVN_NoEqn1Mtrx_rt_Array_Boolean_9_4:0, HaTSXR_b_EVN_NoEqn1Mtrx_HaTSXR_b_EVN_NoEqn1Mtrx_rt_Array_Boolean_9_5:0, HaTSXR_b_EVN_NoEqn1Mtrx_HaTSXR_b_EVN_NoEqn1Mtrx_rt_Array_Boolean_9_6:0, HaTSXR_b_EVN_NoEqn1Mtrx_HaTSXR_b_EVN_NoEqn1Mtrx_rt_Array_Boolean_9_7:0, HaTSXR_b_EVN_NoEqn1Mtrx_HaTSXR_b_EVN_NoEqn1Mtrx_rt_Array_Boolean_9_8:0, HaTSXR_b_EVN_NoEqn1Mtrx_HaTSXR_b_EVN_NoEqn1Mtrx_rt_Array_Boolean_9_9:0], parameter=HaTSXR_b_EVN_NoEqn1Mtrx}, required-interface=HaTSXR_b_EVN_NoEqn1Mtrx
      HaTSXR_b_EVN_NoEqn2Mtrx: parameter-require-com-spec{init-value=HaTSXR_b_EVN_NoEqn2Mtrx_HaTSXR_b_EVN_NoEqn2Mtrx:[HaTSXR_b_EVN_NoEqn2Mtrx_HaTSXR_b_EVN_NoEqn2Mtrx_rt_Array_Boolean_9_1:1, HaTSXR_b_EVN_NoEqn2Mtrx_HaTSXR_b_EVN_NoEqn2Mtrx_rt_Array_Boolean_9_2:0, HaTSXR_b_EVN_NoEqn2Mtrx_HaTSXR_b_EVN_NoEqn2Mtrx_rt_Array_Boolean_9_3:0, HaTSXR_b_EVN_NoEqn2Mtrx_HaTSXR_b_EVN_NoEqn2Mtrx_rt_Array_Boolean_9_4:0, HaTSXR_b_EVN_NoEqn2Mtrx_HaTSXR_b_EVN_NoEqn2Mtrx_rt_Array_Boolean_9_5:0, HaTSXR_b_EVN_NoEqn2Mtrx_HaTSXR_b_EVN_NoEqn2Mtrx_rt_Array_Boolean_9_6:0, HaTSXR_b_EVN_NoEqn2Mtrx_HaTSXR_b_EVN_NoEqn2Mtrx_rt_Array_Boolean_9_7:0, HaTSXR_b_EVN_NoEqn2Mtrx_HaTSXR_b_EVN_NoEqn2Mtrx_rt_Array_Boolean_9_8:0, HaTSXR_b_EVN_NoEqn2Mtrx_HaTSXR_b_EVN_NoEqn2Mtrx_rt_Array_Boolean_9_9:0], parameter=HaTSXR_b_EVN_NoEqn2Mtrx}, required-interface=HaTSXR_b_EVN_NoEqn2Mtrx
      HaTSXR_b_EVN_NtiEqn1Mtrx: parameter-require-com-spec{init-value=HaTSXR_b_EVN_NtiEqn1Mtrx_HaTSXR_b_EVN_NtiEqn1Mtrx:[HaTSXR_b_EVN_NtiEqn1Mtrx_HaTSXR_b_EVN_NtiEqn1Mtrx_rt_Array_Boolean_9_1:0, HaTSXR_b_EVN_NtiEqn1Mtrx_HaTSXR_b_EVN_NtiEqn1Mtrx_rt_Array_Boolean_9_2:0, HaTSXR_b_EVN_NtiEqn1Mtrx_HaTSXR_b_EVN_NtiEqn1Mtrx_rt_Array_Boolean_9_3:0, HaTSXR_b_EVN_NtiEqn1Mtrx_HaTSXR_b_EVN_NtiEqn1Mtrx_rt_Array_Boolean_9_4:0, HaTSXR_b_EVN_NtiEqn1Mtrx_HaTSXR_b_EVN_NtiEqn1Mtrx_rt_Array_Boolean_9_5:0, HaTSXR_b_EVN_NtiEqn1Mtrx_HaTSXR_b_EVN_NtiEqn1Mtrx_rt_Array_Boolean_9_6:0, HaTSXR_b_EVN_NtiEqn1Mtrx_HaTSXR_b_EVN_NtiEqn1Mtrx_rt_Array_Boolean_9_7:0, HaTSXR_b_EVN_NtiEqn1Mtrx_HaTSXR_b_EVN_NtiEqn1Mtrx_rt_Array_Boolean_9_8:0, HaTSXR_b_EVN_NtiEqn1Mtrx_HaTSXR_b_EVN_NtiEqn1Mtrx_rt_Array_Boolean_9_9:0], parameter=HaTSXR_b_EVN_NtiEqn1Mtrx}, required-interface=HaTSXR_b_EVN_NtiEqn1Mtrx
      HaTSXR_b_EVN_NtiEqn2Mtrx: parameter-require-com-spec{init-value=HaTSXR_b_EVN_NtiEqn2Mtrx_HaTSXR_b_EVN_NtiEqn2Mtrx:[HaTSXR_b_EVN_NtiEqn2Mtrx_HaTSXR_b_EVN_NtiEqn2Mtrx_rt_Array_Boolean_9_1:0, HaTSXR_b_EVN_NtiEqn2Mtrx_HaTSXR_b_EVN_NtiEqn2Mtrx_rt_Array_Boolean_9_2:0, HaTSXR_b_EVN_NtiEqn2Mtrx_HaTSXR_b_EVN_NtiEqn2Mtrx_rt_Array_Boolean_9_3:0, HaTSXR_b_EVN_NtiEqn2Mtrx_HaTSXR_b_EVN_NtiEqn2Mtrx_rt_Array_Boolean_9_4:0, HaTSXR_b_EVN_NtiEqn2Mtrx_HaTSXR_b_EVN_NtiEqn2Mtrx_rt_Array_Boolean_9_5:0, HaTSXR_b_EVN_NtiEqn2Mtrx_HaTSXR_b_EVN_NtiEqn2Mtrx_rt_Array_Boolean_9_6:0, HaTSXR_b_EVN_NtiEqn2Mtrx_HaTSXR_b_EVN_NtiEqn2Mtrx_rt_Array_Boolean_9_7:0, HaTSXR_b_EVN_NtiEqn2Mtrx_HaTSXR_b_EVN_NtiEqn2Mtrx_rt_Array_Boolean_9_8:0, HaTSXR_b_EVN_NtiEqn2Mtrx_HaTSXR_b_EVN_NtiEqn2Mtrx_rt_Array_Boolean_9_9:0], parameter=HaTSXR_b_EVN_NtiEqn2Mtrx}, required-interface=HaTSXR_b_EVN_NtiEqn2Mtrx
      HeHSCR_b_ForceDrive: parameter-require-com-spec{init-value=HeHSCR_b_ForceDrive_HeHSCR_b_ForceDrive:0, parameter=HeHSCR_b_ForceDrive}, required-interface=HeHSCR_b_ForceDrive
      HeHSCR_b_ToMaxMinArbtBEV: parameter-require-com-spec{init-value=HeHSCR_b_ToMaxMinArbtBEV_HeHSCR_b_ToMaxMinArbtBEV:1, parameter=HeHSCR_b_ToMaxMinArbtBEV}, required-interface=HeHSCR_b_ToMaxMinArbtBEV
      HeOPTR_b_FixedGrDpndntRngSt_EVM: parameter-require-com-spec{init-value=HeOPTR_b_FixedGrDpndntRngSt_EVM_HeOPTR_b_FixedGrDpndntRngSt_EVM:0, parameter=HeOPTR_b_FixedGrDpndntRngSt_EVM}, required-interface=HeOPTR_b_FixedGrDpndntRngSt_EVM
      HeOPTR_b_FixedGrDpndntRngSt_EVN: parameter-require-com-spec{init-value=HeOPTR_b_FixedGrDpndntRngSt_EVN_HeOPTR_b_FixedGrDpndntRngSt_EVN:0, parameter=HeOPTR_b_FixedGrDpndntRngSt_EVN}, required-interface=HeOPTR_b_FixedGrDpndntRngSt_EVN
      HeOPTR_b_FixedGrDpndntRngSt_Gr: parameter-require-com-spec{init-value=HeOPTR_b_FixedGrDpndntRngSt_Gr_HeOPTR_b_FixedGrDpndntRngSt_Gr:0, parameter=HeOPTR_b_FixedGrDpndntRngSt_Gr}, required-interface=HeOPTR_b_FixedGrDpndntRngSt_Gr
      HeOPTR_b_FixedGrDpndntRngSt_MA: parameter-require-com-spec{init-value=HeOPTR_b_FixedGrDpndntRngSt_MA_HeOPTR_b_FixedGrDpndntRngSt_MA:0, parameter=HeOPTR_b_FixedGrDpndntRngSt_MA}, required-interface=HeOPTR_b_FixedGrDpndntRngSt_MA
      HeOPTR_b_FixedGrDpndntRngSt_MB: parameter-require-com-spec{init-value=HeOPTR_b_FixedGrDpndntRngSt_MB_HeOPTR_b_FixedGrDpndntRngSt_MB:0, parameter=HeOPTR_b_FixedGrDpndntRngSt_MB}, required-interface=HeOPTR_b_FixedGrDpndntRngSt_MB
      HeOPTR_b_FixedGrDpndntRngSt_N_GA: parameter-require-com-spec{init-value=HeOPTR_b_FixedGrDpndntRngSt_N_GA_HeOPTR_b_FixedGrDpndntRngSt_N_GA:0, parameter=HeOPTR_b_FixedGrDpndntRngSt_N_GA}, required-interface=HeOPTR_b_FixedGrDpndntRngSt_N_GA
      KaOPTR_b_RGS_Gears_Sel: parameter-require-com-spec{init-value=KaOPTR_b_RGS_Gears_Sel_KaOPTR_b_RGS_Gears_Sel:[KaOPTR_b_RGS_Gears_Sel_KaOPTR_b_RGS_Gears_Sel_rt_Array_Boolean_13_1:0, KaOPTR_b_RGS_Gears_Sel_KaOPTR_b_RGS_Gears_Sel_rt_Array_Boolean_13_2:0, KaOPTR_b_RGS_Gears_Sel_KaOPTR_b_RGS_Gears_Sel_rt_Array_Boolean_13_3:0, KaOPTR_b_RGS_Gears_Sel_KaOPTR_b_RGS_Gears_Sel_rt_Array_Boolean_13_4:0, KaOPTR_b_RGS_Gears_Sel_KaOPTR_b_RGS_Gears_Sel_rt_Array_Boolean_13_5:0, KaOPTR_b_RGS_Gears_Sel_KaOPTR_b_RGS_Gears_Sel_rt_Array_Boolean_13_6:0, KaOPTR_b_RGS_Gears_Sel_KaOPTR_b_RGS_Gears_Sel_rt_Array_Boolean_13_7:0, KaOPTR_b_RGS_Gears_Sel_KaOPTR_b_RGS_Gears_Sel_rt_Array_Boolean_13_8:0, KaOPTR_b_RGS_Gears_Sel_KaOPTR_b_RGS_Gears_Sel_rt_Array_Boolean_13_9:0, KaOPTR_b_RGS_Gears_Sel_KaOPTR_b_RGS_Gears_Sel_rt_Array_Boolean_13_10:0, KaOPTR_b_RGS_Gears_Sel_KaOPTR_b_RGS_Gears_Sel_rt_Array_Boolean_13_11:0, KaOPTR_b_RGS_Gears_Sel_KaOPTR_b_RGS_Gears_Sel_rt_Array_Boolean_13_12:0, KaOPTR_b_RGS_Gears_Sel_KaOPTR_b_RGS_Gears_Sel_rt_Array_Boolean_13_13:0], parameter=KaOPTR_b_RGS_Gears_Sel}, required-interface=KaOPTR_b_RGS_Gears_Sel
      KaOPTR_b_ZeroRPMAllowPRNDL: parameter-require-com-spec{init-value=KaOPTR_b_ZeroRPMAllowPRNDL_KaOPTR_b_ZeroRPMAllowPRNDL:[KaOPTR_b_ZeroRPMAllowPRNDL_KaOPTR_b_ZeroRPMAllowPRNDL_rt_Array_Boolean_4_1:0, KaOPTR_b_ZeroRPMAllowPRNDL_KaOPTR_b_ZeroRPMAllowPRNDL_rt_Array_Boolean_4_2:0, KaOPTR_b_ZeroRPMAllowPRNDL_KaOPTR_b_ZeroRPMAllowPRNDL_rt_Array_Boolean_4_3:0, KaOPTR_b_ZeroRPMAllowPRNDL_KaOPTR_b_ZeroRPMAllowPRNDL_rt_Array_Boolean_4_4:0], parameter=KaOPTR_b_ZeroRPMAllowPRNDL}, required-interface=KaOPTR_b_ZeroRPMAllowPRNDL
      KaOPTR_b_ZeroRPMAllowTCase: parameter-require-com-spec{init-value=KaOPTR_b_ZeroRPMAllowTCase_KaOPTR_b_ZeroRPMAllowTCase:[KaOPTR_b_ZeroRPMAllowTCase_KaOPTR_b_ZeroRPMAllowTCase_rt_Array_Boolean_8_1:1, KaOPTR_b_ZeroRPMAllowTCase_KaOPTR_b_ZeroRPMAllowTCase_rt_Array_Boolean_8_2:1, KaOPTR_b_ZeroRPMAllowTCase_KaOPTR_b_ZeroRPMAllowTCase_rt_Array_Boolean_8_3:1, KaOPTR_b_ZeroRPMAllowTCase_KaOPTR_b_ZeroRPMAllowTCase_rt_Array_Boolean_8_4:1, KaOPTR_b_ZeroRPMAllowTCase_KaOPTR_b_ZeroRPMAllowTCase_rt_Array_Boolean_8_5:1, KaOPTR_b_ZeroRPMAllowTCase_KaOPTR_b_ZeroRPMAllowTCase_rt_Array_Boolean_8_6:1, KaOPTR_b_ZeroRPMAllowTCase_KaOPTR_b_ZeroRPMAllowTCase_rt_Array_Boolean_8_7:1, KaOPTR_b_ZeroRPMAllowTCase_KaOPTR_b_ZeroRPMAllowTCase_rt_Array_Boolean_8_8:1], parameter=KaOPTR_b_ZeroRPMAllowTCase}, required-interface=KaOPTR_b_ZeroRPMAllowTCase
      KeHSCR_b_UseFiltFrntLowMu: parameter-require-com-spec{init-value=KeHSCR_b_UseFiltFrntLowMu_KeHSCR_b_UseFiltFrntLowMu:1, parameter=KeHSCR_b_UseFiltFrntLowMu}, required-interface=KeHSCR_b_UseFiltFrntLowMu
      KeHSCR_b_UseFiltRearLowMu: parameter-require-com-spec{init-value=KeHSCR_b_UseFiltRearLowMu_KeHSCR_b_UseFiltRearLowMu:1, parameter=KeHSCR_b_UseFiltRearLowMu}, required-interface=KeHSCR_b_UseFiltRearLowMu
      KeHSCR_b_UseLowMuLmtArbt: parameter-require-com-spec{init-value=KeHSCR_b_UseLowMuLmtArbt_KeHSCR_b_UseLowMuLmtArbt:1, parameter=KeHSCR_b_UseLowMuLmtArbt}, required-interface=KeHSCR_b_UseLowMuLmtArbt
      KeOPTR_b_RGS_Threshold_Disable: parameter-require-com-spec{init-value=KeOPTR_b_RGS_Threshold_Disable_KeOPTR_b_RGS_Threshold_Disable:0, parameter=KeOPTR_b_RGS_Threshold_Disable}, required-interface=KeOPTR_b_RGS_Threshold_Disable
      KtOPTR_r_BattTmpThermalCntrl: parameter-require-com-spec{init-value=15 x 1, parameter=KtOPTR_r_BattTmpThermalCntrl}, required-interface=KtOPTR_r_BattTmpThermalCntrl
      KxOPTR_r_BattTmpThermalCntrl: parameter-require-com-spec{init-value=[-150 -120 -100 -80 -60 -40 -20 0 20 40 60 80 100 125 150], parameter=KxOPTR_r_BattTmpThermalCntrl}, required-interface=KxOPTR_r_BattTmpThermalCntrl
      KtOPTR_r_INVR_A_ThermalCntrl: parameter-require-com-spec{init-value=[1 1 1 0.899999976158142 0], parameter=KtOPTR_r_INVR_A_ThermalCntrl}, required-interface=KtOPTR_r_INVR_A_ThermalCntrl
      KxOPTR_r_INVR_A_ThermalCntrl: parameter-require-com-spec{init-value=[0 90 95 100 110], parameter=KxOPTR_r_INVR_A_ThermalCntrl}, required-interface=KxOPTR_r_INVR_A_ThermalCntrl
      KtOPTR_r_INVR_B_ThermalCntrl: parameter-require-com-spec{init-value=[1 1 1 0.899999976158142 0], parameter=KtOPTR_r_INVR_B_ThermalCntrl}, required-interface=KtOPTR_r_INVR_B_ThermalCntrl
      KxOPTR_r_INVR_B_ThermalCntrl: parameter-require-com-spec{init-value=[0 90 95 100 110], parameter=KxOPTR_r_INVR_B_ThermalCntrl}, required-interface=KxOPTR_r_INVR_B_ThermalCntrl
      KtOPTR_r_INVR_C_ThermalCntrl: parameter-require-com-spec{init-value=[1 1 1 0.899999976158142 0], parameter=KtOPTR_r_INVR_C_ThermalCntrl}, required-interface=KtOPTR_r_INVR_C_ThermalCntrl
      KxOPTR_r_INVR_C_ThermalCntrl: parameter-require-com-spec{init-value=[0 90 95 100 110], parameter=KxOPTR_r_INVR_C_ThermalCntrl}, required-interface=KxOPTR_r_INVR_C_ThermalCntrl
      KtOPTR_r_Mtr_A_ThermalCntrl: parameter-require-com-spec{init-value=15 x 1, parameter=KtOPTR_r_Mtr_A_ThermalCntrl}, required-interface=KtOPTR_r_Mtr_A_ThermalCntrl
      KxOPTR_r_Mtr_A_ThermalCntrl: parameter-require-com-spec{init-value=[-50 -30 -10 10 30 50 70 100 120 140 160 180 200 225 250], parameter=KxOPTR_r_Mtr_A_ThermalCntrl}, required-interface=KxOPTR_r_Mtr_A_ThermalCntrl
      KtOPTR_r_Mtr_B_ThermalCntrl: parameter-require-com-spec{init-value=15 x 1, parameter=KtOPTR_r_Mtr_B_ThermalCntrl}, required-interface=KtOPTR_r_Mtr_B_ThermalCntrl
      KxOPTR_r_Mtr_B_ThermalCntrl: parameter-require-com-spec{init-value=[-50 -30 -10 10 30 50 70 100 120 140 160 180 200 225 250], parameter=KxOPTR_r_Mtr_B_ThermalCntrl}, required-interface=KxOPTR_r_Mtr_B_ThermalCntrl
      KtOPTR_r_Mtr_C_ThermalCntrl: parameter-require-com-spec{init-value=15 x 1, parameter=KtOPTR_r_Mtr_C_ThermalCntrl}, required-interface=KtOPTR_r_Mtr_C_ThermalCntrl
      KxOPTR_r_Mtr_C_ThermalCntrl: parameter-require-com-spec{init-value=[-50 -30 -10 10 30 50 70 100 120 140 160 180 200 225 250], parameter=KxOPTR_r_Mtr_C_ThermalCntrl}, required-interface=KxOPTR_r_Mtr_C_ThermalCntrl
      KtOPTR_n_P2IdleSpd: parameter-require-com-spec{init-value=10 x 720, parameter=KtOPTR_n_P2IdleSpd}, required-interface=KtOPTR_n_P2IdleSpd
      KxOPTR_n_P2IdleSpd: parameter-require-com-spec{init-value=[-3.3199999332428 0 0.670000016689301 0.839999973773956 1 1.27999997138977 1.66999995708466 2.09999990463257 3.14000010490417 4.71000003814697], parameter=KxOPTR_n_P2IdleSpd}, required-interface=KxOPTR_n_P2IdleSpd
      KtOPTR_M_P2ZeroIdle_BrkTrqThres: parameter-require-com-spec{init-value=[-100 -150 -250 -400 -500 -550], parameter=KtOPTR_M_P2ZeroIdle_BrkTrqThres}, required-interface=KtOPTR_M_P2ZeroIdle_BrkTrqThres
      KxOPTR_M_P2ZeroIdle_BrkTrqThres: parameter-require-com-spec{init-value=[0 100 200 500 1000 1500], parameter=KxOPTR_M_P2ZeroIdle_BrkTrqThres}, required-interface=KxOPTR_M_P2ZeroIdle_BrkTrqThres
      KtHSCR_K_LowSpdDnyRgnFrntMinTrq: parameter-require-com-spec{init-value=[0 0 0.330000013113022 0.660000026226044 1 1], parameter=KtHSCR_K_LowSpdDnyRgnFrntMinTrq}, required-interface=KtHSCR_K_LowSpdDnyRgnFrntMinTrq
      KxHSCR_K_LowSpdDnyRgnFrntMinTrq: parameter-require-com-spec{init-value=[0 420 510 590 680 750], parameter=KxHSCR_K_LowSpdDnyRgnFrntMinTrq}, required-interface=KxHSCR_K_LowSpdDnyRgnFrntMinTrq
      KtHSCR_K_LowSpdDnyRgnRrMinTrq: parameter-require-com-spec{init-value=[0 0 0.330000013113022 0.660000026226044 1 1], parameter=KtHSCR_K_LowSpdDnyRgnRrMinTrq}, required-interface=KtHSCR_K_LowSpdDnyRgnRrMinTrq
      KxHSCR_K_LowSpdDnyRgnRrMinTrq: parameter-require-com-spec{init-value=[0 420 510 590 680 750], parameter=KxHSCR_K_LowSpdDnyRgnRrMinTrq}, required-interface=KxHSCR_K_LowSpdDnyRgnRrMinTrq
